VERSION ""

NS_ :

BS_:

BU_: TestTool_HS BCP_HS ECM_HS TCM_HS CGM_HS BCM_HS EBCM_OBD_HS ACCM_HS EBCM_HS TCCM_HS SAS_HS ICCM_OBD_HS ICCM_HS EPS_HS EPB_HS HMIM_HS ONSTAR_HS

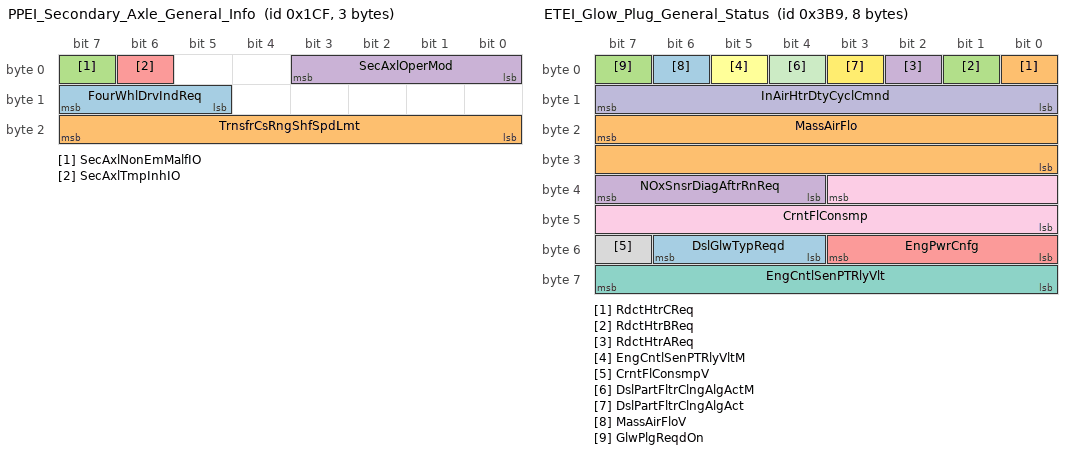
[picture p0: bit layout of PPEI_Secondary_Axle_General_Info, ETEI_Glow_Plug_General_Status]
BO_ 463 PPEI_Secondary_Axle_General_Info: 3 ECM_HS
 SG_ FourWhlDrvIndReq : 15|3@0+ (1,0) [0|7] ""  CGM_HS,BCM_HS
 SG_ TrnsfrCsRngShfSpdLmt : 23|8@0+ (1,0) [0|255] "km / h"  CGM_HS,BCM_HS
 SG_ SecAxlNonEmMalfIO : 7|1@0+ (1,0) [0|1] ""  CGM_HS,BCM_HS
 SG_ SecAxlOperMod : 3|4@0+ (1,0) [0|15] ""  CGM_HS,EBCM_OBD_HS,ONSTAR_HS,EBCM_HS,BCM_HS,TCM_HS,ECM_HS
 SG_ SecAxlTmpInhIO : 6|1@0+ (1,0) [0|1] ""  CGM_HS,ONSTAR_HS,BCM_HS

BO_ 953 ETEI_Glow_Plug_General_Status: 8 ECM_HS
 SG_ DslGlwTypReqd : 54|3@0+ (1,0) [0|7] "" Vector__XXX
 SG_ RdctHtrCReq : 0|1@0+ (1,0) [0|1] "" Vector__XXX
 SG_ RdctHtrBReq : 1|1@0+ (1,0) [0|1] "" Vector__XXX
 SG_ RdctHtrAReq : 2|1@0+ (1,0) [0|1] "" Vector__XXX
 SG_ EngPwrCnfg : 51|4@0+ (1,0) [0|15] "" Vector__XXX
 SG_ EngCntlSenPTRlyVltM : 5|1@0+ (1,0) [0|1] "" Vector__XXX
 SG_ EngCntlSenPTRlyVlt : 63|8@0+ (0.1,0) [0|25.5] "volts" Vector__XXX
 SG_ CrntFlConsmpV : 55|1@0+ (1,0) [0|1] "" Vector__XXX
 SG_ CrntFlConsmp : 35|12@0+ (0.05,0) [0|204.75] "mm3/stk" Vector__XXX
 SG_ InAirHtrDtyCyclCmnd : 15|8@0+ (0.392157,0) [0|100.000035] "%" Vector__XXX
 SG_ DslPartFltrClngAlgActM : 4|1@0+ (1,0) [0|1] "" Vector__XXX
 SG_ DslPartFltrClngAlgAct : 3|1@0+ (1,0) [0|1] "" Vector__XXX
 SG_ MassAirFloV : 6|1@0+ (1,0) [0|1] "" Vector__XXX
 SG_ MassAirFlo : 23|16@0+ (0.01,0) [0|655.35] "grams/s" Vector__XXX
 SG_ GlwPlgReqdOn : 7|1@0+ (1,0) [0|1] "" Vector__XXX
 SG_ NOxSnsrDiagAftrRnReq : 39|4@0+ (20,0) [0|300] "Sec" Vector__XXX

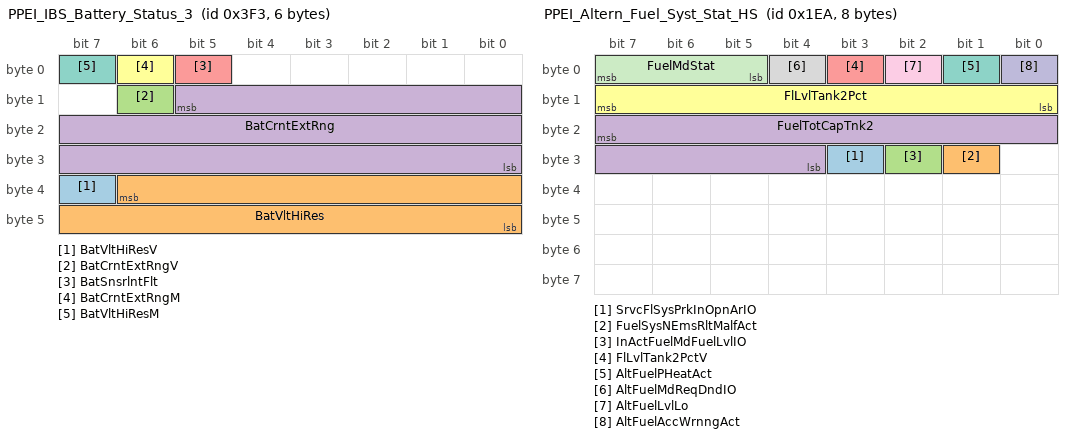
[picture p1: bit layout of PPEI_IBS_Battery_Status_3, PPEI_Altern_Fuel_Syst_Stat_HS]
BO_ 1011 PPEI_IBS_Battery_Status_3: 6 ECM_HS
 SG_ BatVltHiResV : 39|1@0+ (1,0) [0|1] ""  BCM_HS
 SG_ BatVltHiRes : 38|15@0+ (0.001,0) [0|32.767] "volts"  BCM_HS
 SG_ BatCrntExtRngV : 14|1@0+ (1,0) [0|1] ""  BCM_HS
 SG_ BatCrntExtRng : 13|22@0+ (0.001,-2097.152) [-2097.152|2097.151] "amps"  BCM_HS
 SG_ BatSnsrlntFlt : 5|1@0+ (1,0) [0|1] ""  BCM_HS
 SG_ BatCrntExtRngM : 6|1@0+ (1,0) [0|1] ""  BCM_HS
 SG_ BatVltHiResM : 7|1@0+ (1,0) [0|1] ""  BCM_HS

BO_ 490 PPEI_Altern_Fuel_Syst_Stat_HS: 8 ECM_HS
 SG_ SrvcFlSysPrkInOpnArIO : 27|1@0+ (1,0) [0|1] ""  BCM_HS
 SG_ FuelSysNEmsRltMalfAct : 25|1@0+ (1,0) [0|1] ""  BCM_HS
 SG_ InActFuelMdFuelLvlIO : 26|1@0+ (1,0) [0|1] ""  BCM_HS
 SG_ FuelTotCapTnk2 : 23|12@0+ (0.125,0) [0|511.875] "liters"  BCM_HS
 SG_ FlLvlTank2PctV : 3|1@0+ (1,0) [0|1] ""  BCM_HS
 SG_ FlLvlTank2Pct : 15|8@0+ (0.392157,0) [0|100.000035] "%"  BCM_HS
 SG_ AltFuelPHeatAct : 1|1@0+ (1,0) [0|1] ""  BCM_HS,ECM_HS
 SG_ AltFuelMdReqDndIO : 4|1@0+ (1,0) [0|1] ""  BCM_HS
 SG_ AltFuelLvlLo : 2|1@0+ (1,0) [0|1] ""  BCM_HS,ECM_HS
 SG_ AltFuelAccWrnngAct : 0|1@0+ (1,0) [0|1] ""  BCM_HS
 SG_ FuelMdStat : 7|3@0+ (1,0) [0|7] ""  BCM_HS,ECM_HS

BO_ 1267 PPEI_Powertrain_Config_Data_2: 1 ECM_HS
 SG_ VehMassNom : 7|8@0+ (20,500) [500|5600] "kg"  CGM_HS

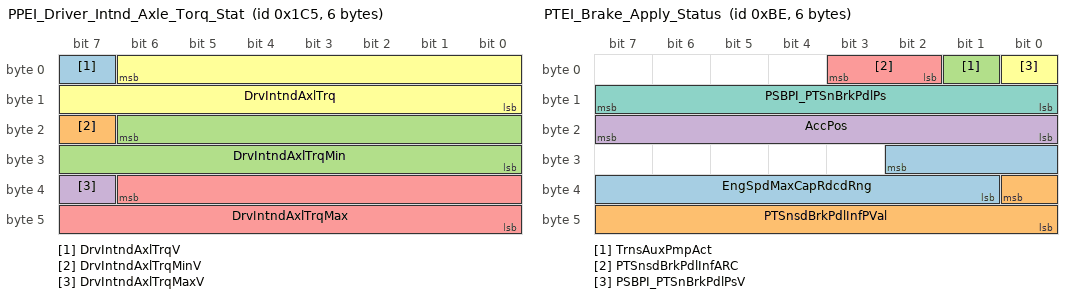
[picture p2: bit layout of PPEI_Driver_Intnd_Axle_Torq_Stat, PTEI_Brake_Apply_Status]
BO_ 453 PPEI_Driver_Intnd_Axle_Torq_Stat: 6 ECM_HS
 SG_ DrvIntndAxlTrqV : 7|1@0+ (1,0) [0|1] ""  CGM_HS,ICCM_OBD_HS,EBCM_OBD_HS,ICCM_HS,EBCM_HS
 SG_ DrvIntndAxlTrqMinV : 23|1@0+ (1,0) [0|1] ""  CGM_HS
 SG_ DrvIntndAxlTrqMin : 22|15@0+ (2,-22534) [-22534|43000] "Nm"  CGM_HS
 SG_ DrvIntndAxlTrqMaxV : 39|1@0+ (1,0) [0|1] ""  CGM_HS
 SG_ DrvIntndAxlTrqMax : 38|15@0+ (2,-22534) [-22534|43000] "Nm"  CGM_HS
 SG_ DrvIntndAxlTrq : 6|15@0+ (2,-22534) [-22534|43000] "Nm"  CGM_HS,ICCM_OBD_HS,EBCM_OBD_HS,ICCM_HS,EBCM_HS

BO_ 452 PPEI_Torque_Request_Status: 8 ECM_HS
 SG_ FSpRgACCSwADdPVal : 50|2@0+ (1,0) [0|3] ""  CGM_HS,EBCM_OBD_HS,EBCM_HS
 SG_ FSpRgACCSwADdARC : 6|2@0+ (1,0) [0|3] ""  CGM_HS,EBCM_OBD_HS,EBCM_HS
 SG_ FSpRgACCSwADd : 7|1@0+ (1,0) [0|1] ""  CGM_HS,EBCM_OBD_HS,EBCM_HS
 SG_ AutBrkAccActPsStRC : 34|2@0+ (1,0) [0|3] ""  CGM_HS,EBCM_OBD_HS,EPB_HS,EBCM_HS
 SG_ AutBrkAccActPsStPVal : 48|9@0+ (1,0) [0|511] ""  CGM_HS,EBCM_OBD_HS,EPB_HS,EBCM_HS
 SG_ ABAAPS_AccPos : 47|8@0+ (0.392157,0) [0|100.000035] "%"  CGM_HS,EBCM_OBD_HS,EPB_HS,EBCM_HS
 SG_ ABAAPS_AccPosV : 32|1@0+ (1,0) [0|1] ""  CGM_HS,EBCM_OBD_HS,EPB_HS,EBCM_HS
 SG_ ACCATCS_LmtgStat : 12|2@0+ (1,0) [0|3] ""  CGM_HS
 SG_ ACCATCS_RqStat : 15|3@0+ (1,0) [0|7] ""  CGM_HS
 SG_ RdLdNomAxlTrq : 10|19@0+ (0.125,-22534) [-22534|43001.875] "Nm"  CGM_HS
 SG_ AccPdlOvrrdAtvProtVal : 1|2@0+ (1,0) [0|3] ""  CGM_HS,EBCM_OBD_HS,EBCM_HS
 SG_ AccPdlOvrrdAtvARC : 3|2@0+ (1,0) [0|3] ""  CGM_HS,EBCM_OBD_HS,EBCM_HS
 SG_ AccPdlOvrrdAtv : 4|1@0+ (1,0) [0|1] ""  CGM_HS,EBCM_OBD_HS,EBCM_HS,BCM_HS
 SG_ CPSATCS_ReqStatus : 37|3@0+ (1,0) [0|7] ""  CGM_HS
 SG_ CPSATCS_LmtngStatus : 39|2@0+ (1,0) [0|3] ""  CGM_HS
 SG_ RVBATCS_ReqStat : 53|3@0+ (1,0) [0|7] ""  CGM_HS
 SG_ RVBATCS_LmtngStat : 55|2@0+ (1,0) [0|3] ""  CGM_HS

BO_ 190 PTEI_Brake_Apply_Status: 6 ECM_HS
 SG_ EngSpdMaxCapRdcdRng : 26|10@0+ (8,0) [0|8184] "rpm"  TCM_HS
 SG_ PTSnsdBrkPdlInfPVal : 32|9@0+ (1,0) [0|511] ""  ICCM_OBD_HS,EBCM_OBD_HS,ICCM_HS,EBCM_HS
 SG_ TrnsAuxPmpAct : 1|1@0+ (1,0) [0|1] ""  TCM_HS
 SG_ AccPos : 23|8@0+ (0.392157,0) [0|100.000035] "%"  BCP_HS,TCCM_HS,TCM_HS
 SG_ PTSnsdBrkPdlInfARC : 3|2@0+ (1,0) [0|3] ""  ICCM_OBD_HS,EBCM_OBD_HS,ICCM_HS,EBCM_HS
 SG_ PSBPI_PTSnBrkPdlPsV : 0|1@0+ (1,0) [0|1] ""  ICCM_OBD_HS,EBCM_OBD_HS,ICCM_HS,EBCM_HS,TCM_HS
 SG_ PSBPI_PTSnBrkPdlPs : 15|8@0+ (0.392157,0) [0|100.000035] "%"  ICCM_OBD_HS,EBCM_OBD_HS,ICCM_HS,EBCM_HS,TCM_HS

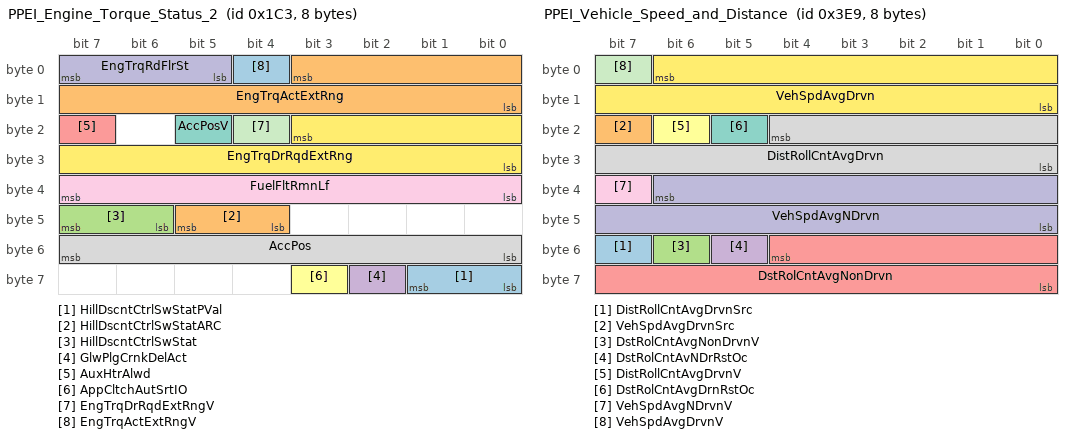
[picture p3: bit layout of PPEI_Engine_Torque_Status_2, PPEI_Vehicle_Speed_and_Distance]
BO_ 451 PPEI_Engine_Torque_Status_2: 8 ECM_HS
 SG_ HillDscntCtrlSwStatPVal : 57|2@0+ (1,0) [0|3] ""  CGM_HS,EBCM_OBD_HS,EBCM_HS
 SG_ HillDscntCtrlSwStatARC : 45|2@0+ (1,0) [0|3] ""  CGM_HS,EBCM_OBD_HS,EBCM_HS
 SG_ HillDscntCtrlSwStat : 47|2@0+ (1,0) [0|3] ""  CGM_HS,EBCM_OBD_HS,EBCM_HS
 SG_ GlwPlgCrnkDelAct : 58|1@0+ (1,0) [0|1] ""  CGM_HS,BCM_HS
 SG_ AuxHtrAlwd : 23|1@0+ (1,0) [0|1] ""  CGM_HS,BCM_HS
 SG_ AppCltchAutSrtIO : 59|1@0+ (1,0) [0|1] ""  CGM_HS,BCM_HS
 SG_ AccPosV : 21|1@0+ (1,0) [0|1] ""  CGM_HS,ICCM_OBD_HS,EBCM_OBD_HS,ICCM_HS,TCCM_HS,EBCM_HS
 SG_ AccPos : 55|8@0+ (0.392157,0) [0|100.000035] "%"  CGM_HS,ICCM_OBD_HS,EBCM_OBD_HS,ICCM_HS,TCCM_HS,EBCM_HS
 SG_ FuelFltRmnLf : 39|8@0+ (0.392157,0) [0|100.000035] "%"  CGM_HS,ONSTAR_HS,BCM_HS
 SG_ EngTrqRdFlrSt : 7|3@0+ (1,0) [0|7] ""  CGM_HS,EBCM_OBD_HS,EBCM_HS
 SG_ EngTrqDrRqdExtRngV : 20|1@0+ (1,0) [0|1] ""  CGM_HS,EBCM_OBD_HS,EBCM_HS,BCM_HS
 SG_ EngTrqDrRqdExtRng : 19|12@0+ (0.5,-848) [-848|1199.5] "Nm"  CGM_HS,EBCM_OBD_HS,EBCM_HS,BCM_HS
 SG_ EngTrqActExtRngV : 4|1@0+ (1,0) [0|1] ""  CGM_HS,ICCM_OBD_HS,EBCM_OBD_HS,ICCM_HS,EPS_HS,EPB_HS,TCCM_HS,EBCM_HS,BCM_HS
 SG_ EngTrqActExtRng : 3|12@0+ (0.5,-848) [-848|1199.5] "Nm"  CGM_HS,ICCM_OBD_HS,EBCM_OBD_HS,ICCM_HS,EPS_HS,EPB_HS,TCCM_HS,EBCM_HS,BCM_HS

BO_ 495 PPEI_Fuel_System_Request_2: 4 ECM_HS
 SG_ MassAirFloV : 7|1@0+ (1,0) [0|1] "" Vector__XXX
 SG_ MassAirFlo : 23|16@0+ (0.01,0) [0|655.35] "grams/s" Vector__XXX

BO_ 1906 DTC_Triggered_772: 7 ECM_HS
 SG_ DTCI_DTCFaultType_772 : 55|8@0+ (1,0) [0|255] ""  CGM_HS,HMIM_HS,ONSTAR_HS
 SG_ DTCI_CodeSupported_772 : 40|1@0+ (1,0) [0|1] ""  CGM_HS,HMIM_HS,ONSTAR_HS
 SG_ DTCI_CurrentStatus_772 : 41|1@0+ (1,0) [0|1] ""  CGM_HS,HMIM_HS,ONSTAR_HS
 SG_ DTCI_TstNPsdCdClrdSt_772 : 42|1@0+ (1,0) [0|1] ""  CGM_HS,HMIM_HS,ONSTAR_HS
 SG_ DTCI_TstFldCdClrdStat_772 : 43|1@0+ (1,0) [0|1] ""  CGM_HS,HMIM_HS,ONSTAR_HS
 SG_ DTCI_HistStat_772 : 44|1@0+ (1,0) [0|1] ""  CGM_HS,HMIM_HS,ONSTAR_HS
 SG_ DTCI_TstNPsdPwrUpSt_772 : 45|1@0+ (1,0) [0|1] ""  CGM_HS,HMIM_HS,ONSTAR_HS
 SG_ DTCI_TstFldPwrUpSt_772 : 46|1@0+ (1,0) [0|1] ""  CGM_HS,HMIM_HS,ONSTAR_HS
 SG_ DTCI_WrnIndRqdSt_772 : 47|1@0+ (1,0) [0|1] ""  CGM_HS,HMIM_HS,ONSTAR_HS
 SG_ DTCI_DTCFailType_772 : 39|8@0+ (1,0) [0|255] ""  CGM_HS,HMIM_HS,ONSTAR_HS
 SG_ DTCI_DTCNumber_772 : 23|16@0+ (1,0) [0|65535] ""  CGM_HS,HMIM_HS,ONSTAR_HS
 SG_ DTCI_DTCSource_772 : 15|8@0+ (1,0) [0|255] ""  CGM_HS,HMIM_HS,ONSTAR_HS
 SG_ DTCI_DTCTriggered_772 : 0|1@0+ (1,0) [0|1] ""  CGM_HS,HMIM_HS,ONSTAR_HS
 SG_ DTCIUnused7_772 : 1|1@0+ (1,0) [0|1] ""  CGM_HS,HMIM_HS,ONSTAR_HS
 SG_ DTCIUnused6_772 : 2|1@0+ (1,0) [0|1] ""  CGM_HS,HMIM_HS,ONSTAR_HS
 SG_ DTCIUnused5_772 : 3|1@0+ (1,0) [0|1] ""  CGM_HS,HMIM_HS,ONSTAR_HS
 SG_ DTCIUnused4_772 : 4|1@0+ (1,0) [0|1] ""  CGM_HS,HMIM_HS,ONSTAR_HS
 SG_ DTCIUnused3_772 : 5|1@0+ (1,0) [0|1] ""  CGM_HS,HMIM_HS,ONSTAR_HS
 SG_ DTCIUnused2_772 : 6|1@0+ (1,0) [0|1] ""  CGM_HS,HMIM_HS,ONSTAR_HS
 SG_ DTCIUnused1_772 : 7|1@0+ (1,0) [0|1] ""  CGM_HS,HMIM_HS,ONSTAR_HS

BO_ 1001 PPEI_Vehicle_Speed_and_Distance: 8 ECM_HS
 SG_ DistRollCntAvgDrvnSrc : 55|1@0+ (1,0) [0|1] ""  CGM_HS,EBCM_OBD_HS,HMIM_HS,EPS_HS,BCP_HS,TCCM_HS,EBCM_HS,BCM_HS,TCM_HS
 SG_ VehSpdAvgDrvnSrc : 23|1@0+ (1,0) [0|1] ""  CGM_HS,EBCM_OBD_HS,HMIM_HS,EPS_HS,EPB_HS,TCCM_HS,EBCM_HS,BCM_HS,TCM_HS
 SG_ DstRolCntAvgNonDrvnV : 54|1@0+ (1,0) [0|1] ""  CGM_HS,EBCM_OBD_HS,HMIM_HS,EPS_HS,TCCM_HS,EBCM_HS,BCM_HS
 SG_ DstRolCntAvNDrRstOc : 53|1@0+ (1,0) [0|1] ""  CGM_HS,EBCM_OBD_HS,HMIM_HS,EPS_HS,TCCM_HS,EBCM_HS,BCM_HS
 SG_ DstRolCntAvgNonDrvn : 52|13@0+ (0.125,0) [0|1023.875] "m"  CGM_HS,EBCM_OBD_HS,HMIM_HS,EPS_HS,TCCM_HS,EBCM_HS,BCM_HS
 SG_ DistRollCntAvgDrvnV : 22|1@0+ (1,0) [0|1] ""  CGM_HS,ICCM_OBD_HS,EBCM_OBD_HS,ICCM_HS,HMIM_HS,EPS_HS,BCP_HS,TCCM_HS,EBCM_HS,BCM_HS,TCM_HS
 SG_ DstRolCntAvgDrnRstOc : 21|1@0+ (1,0) [0|1] ""  CGM_HS,ICCM_OBD_HS,EBCM_OBD_HS,ICCM_HS,HMIM_HS,EPS_HS,BCP_HS,TCCM_HS,EBCM_HS,BCM_HS,TCM_HS
 SG_ DistRollCntAvgDrvn : 20|13@0+ (0.125,0) [0|1023.875] "m"  CGM_HS,ICCM_OBD_HS,EBCM_OBD_HS,ICCM_HS,HMIM_HS,EPS_HS,BCP_HS,TCCM_HS,EBCM_HS,BCM_HS,TCM_HS
 SG_ VehSpdAvgNDrvnV : 39|1@0+ (1,0) [0|1] ""  CGM_HS,ICCM_OBD_HS,EBCM_OBD_HS,ICCM_HS,HMIM_HS,EPS_HS,BCP_HS,ONSTAR_HS,EPB_HS,TCCM_HS,EBCM_HS,BCM_HS
 SG_ VehSpdAvgNDrvn : 38|15@0+ (0.015625,0) [0|511.984375] "km / h"  CGM_HS,ICCM_OBD_HS,EBCM_OBD_HS,ICCM_HS,HMIM_HS,EPS_HS,BCP_HS,ONSTAR_HS,EPB_HS,TCCM_HS,EBCM_HS,BCM_HS
 SG_ VehSpdAvgDrvnV : 7|1@0+ (1,0) [0|1] ""  CGM_HS,ICCM_OBD_HS,EBCM_OBD_HS,ICCM_HS,HMIM_HS,EPS_HS,BCP_HS,ONSTAR_HS,EPB_HS,TCCM_HS,EBCM_HS,BCM_HS,TCM_HS
 SG_ VehSpdAvgDrvn : 6|15@0+ (0.015625,0) [0|511.984375] "km / h"  CGM_HS,ICCM_OBD_HS,EBCM_OBD_HS,ICCM_HS,HMIM_HS,EPS_HS,BCP_HS,ONSTAR_HS,EPB_HS,TCCM_HS,EBCM_HS,BCM_HS,TCM_HS

BO_ 961 PPEI_Powertrain_Immobilizer_Data: 8 ECM_HS
 SG_ PTImmblzerInfo : 7|64@0+ (1,0) [0|1.84467440737096E+019] ""  ONSTAR_HS,BCM_HS,ECM_HS

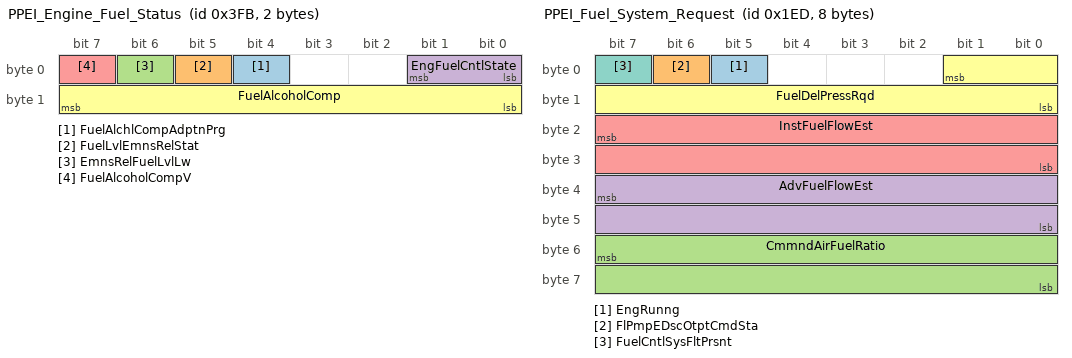
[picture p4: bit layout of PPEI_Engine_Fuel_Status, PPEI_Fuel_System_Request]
BO_ 1019 PPEI_Engine_Fuel_Status: 2 ECM_HS
 SG_ FuelAlchlCompAdptnPrg : 4|1@0+ (1,0) [0|1] ""  CGM_HS,BCM_HS
 SG_ FuelLvlEmnsRelStat : 5|1@0+ (1,0) [0|1] ""  CGM_HS,BCP_HS
 SG_ EmnsRelFuelLvlLw : 6|1@0+ (1,0) [0|1] ""  CGM_HS,ICCM_OBD_HS,ICCM_HS,BCP_HS
 SG_ EngFuelCntlState : 1|2@0+ (1,0) [0|3] ""  CGM_HS,ICCM_OBD_HS,ICCM_HS
 SG_ FuelAlcoholCompV : 7|1@0+ (1,0) [0|1] ""  CGM_HS,ICCM_OBD_HS,ICCM_HS,ONSTAR_HS,BCM_HS
 SG_ FuelAlcoholComp : 15|8@0+ (0.392157,0) [0|100.000035] "%"  CGM_HS,ICCM_OBD_HS,ICCM_HS,ONSTAR_HS,BCM_HS

BO_ 493 PPEI_Fuel_System_Request: 8 ECM_HS
 SG_ EngRunng : 5|1@0+ (1,0) [0|1] ""  CGM_HS,ICCM_OBD_HS,ICCM_HS
 SG_ FlPmpEDscOtptCmdSta : 6|1@0+ (1,0) [0|1] ""  CGM_HS,ICCM_OBD_HS,ICCM_HS
 SG_ CmmndAirFuelRatio : 55|16@0+ (0.000488281,0) [0|31.999495335] ""  CGM_HS,ICCM_OBD_HS,ICCM_HS
 SG_ AdvFuelFlowEst : 39|16@0+ (0.000976562,0) [0|63.99899067] "grams/s"  CGM_HS,ICCM_OBD_HS,ICCM_HS
 SG_ InstFuelFlowEst : 23|16@0+ (0.000976562,0) [0|63.99899067] "grams/s"  CGM_HS,ICCM_OBD_HS,ICCM_HS
 SG_ FuelDelPressRqd : 1|10@0+ (1,0) [0|1023] "kPa"  CGM_HS,ICCM_OBD_HS,ICCM_HS
 SG_ FuelCntlSysFltPrsnt : 7|1@0+ (1,0) [0|1] ""  CGM_HS,ICCM_OBD_HS,ICCM_HS

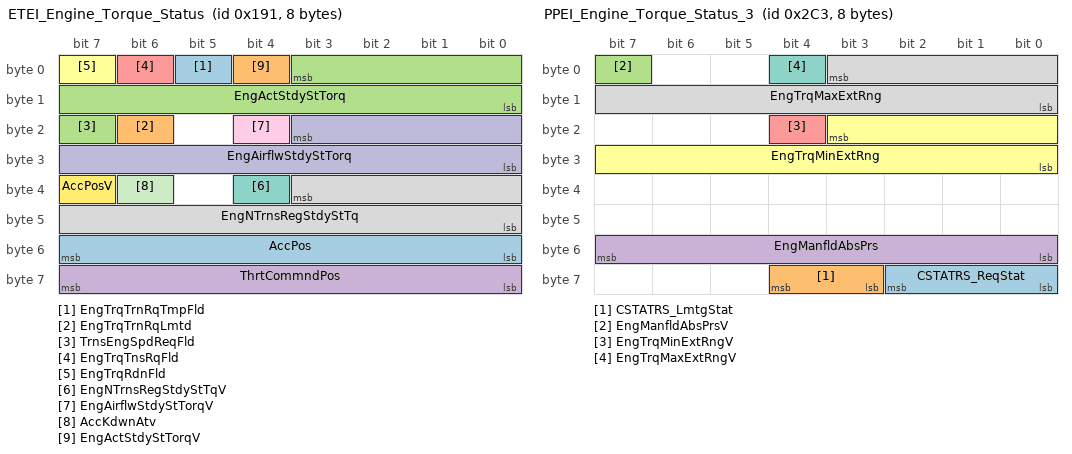
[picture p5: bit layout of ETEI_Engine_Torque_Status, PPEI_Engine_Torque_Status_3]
BO_ 401 ETEI_Engine_Torque_Status: 8 ECM_HS
 SG_ EngTrqTrnRqTmpFld : 5|1@0+ (1,0) [0|1] ""  TCCM_HS,TCM_HS
 SG_ EngTrqTrnRqLmtd : 22|1@0+ (1,0) [0|1] ""  TCCM_HS,TCM_HS
 SG_ TrnsEngSpdReqFld : 23|1@0+ (1,0) [0|1] ""  TCCM_HS,TCM_HS
 SG_ ThrtCommndPos : 63|8@0+ (0.392157,0) [0|100.000035] "%"  TCCM_HS
 SG_ EngTrqTnsRqFld : 6|1@0+ (1,0) [0|1] ""  TCCM_HS,TCM_HS
 SG_ EngTrqRdnFld : 7|1@0+ (1,0) [0|1] ""  TCCM_HS,TCM_HS
 SG_ EngNTrnsRegStdyStTqV : 36|1@0+ (1,0) [0|1] ""  TCCM_HS,TCM_HS
 SG_ EngNTrnsRegStdyStTq : 35|12@0+ (0.5,-848) [-848|1199.5] "Nm"  TCCM_HS,TCM_HS
 SG_ EngAirflwStdyStTorqV : 20|1@0+ (1,0) [0|1] ""  TCCM_HS,TCM_HS
 SG_ EngAirflwStdyStTorq : 19|12@0+ (0.5,-848) [-848|1199.5] "Nm"  TCCM_HS,TCM_HS
 SG_ AccKdwnAtv : 38|1@0+ (1,0) [0|1] ""  TCCM_HS,TCM_HS
 SG_ AccPosV : 39|1@0+ (1,0) [0|1] ""  BCP_HS,TCM_HS
 SG_ AccPos : 55|8@0+ (0.392157,0) [0|100.000035] "%"  BCP_HS,TCM_HS
 SG_ EngActStdyStTorqV : 4|1@0+ (1,0) [0|1] ""  TCCM_HS,TCM_HS
 SG_ EngActStdyStTorq : 3|12@0+ (0.5,-848) [-848|1199.5] "Nm"  TCCM_HS,TCM_HS

BO_ 707 PPEI_Engine_Torque_Status_3: 8 ECM_HS
 SG_ CSTATRS_ReqStat : 58|3@0+ (1,0) [0|7] ""  CGM_HS,EBCM_OBD_HS,EBCM_HS
 SG_ CSTATRS_LmtgStat : 60|2@0+ (1,0) [0|3] ""  CGM_HS,EBCM_OBD_HS,EBCM_HS
 SG_ EngManfldAbsPrsV : 7|1@0+ (1,0) [0|1] ""  CGM_HS,EBCM_OBD_HS,BCP_HS,EBCM_HS
 SG_ EngManfldAbsPrs : 55|8@0+ (0.5,0) [0|127.5] "kPa"  CGM_HS,EBCM_OBD_HS,BCP_HS,EBCM_HS
 SG_ EngTrqMinExtRngV : 20|1@0+ (1,0) [0|1] ""  CGM_HS,EBCM_OBD_HS,EBCM_HS
 SG_ EngTrqMinExtRng : 19|12@0+ (0.5,-848) [-848|1199.5] "Nm"  CGM_HS,EBCM_OBD_HS,EBCM_HS
 SG_ EngTrqMaxExtRngV : 4|1@0+ (1,0) [0|1] ""  CGM_HS,EBCM_OBD_HS,TCCM_HS,EBCM_HS
 SG_ EngTrqMaxExtRng : 3|12@0+ (0.5,-848) [-848|1199.5] "Nm"  CGM_HS,EBCM_OBD_HS,TCCM_HS,EBCM_HS

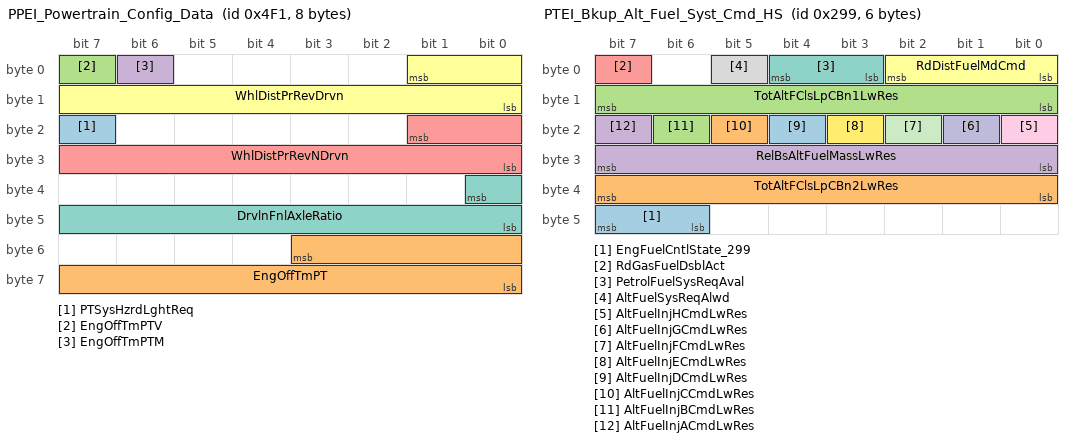
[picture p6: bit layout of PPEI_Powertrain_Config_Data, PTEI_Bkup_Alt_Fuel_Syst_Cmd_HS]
BO_ 1265 PPEI_Powertrain_Config_Data: 8 ECM_HS
 SG_ PTSysHzrdLghtReq : 23|1@0+ (1,0) [0|1] ""  CGM_HS,BCM_HS
 SG_ EngOffTmPT : 51|12@0+ (0.5,0) [0|2047.5] "min"  CGM_HS,EBCM_OBD_HS,EBCM_HS,TCM_HS
 SG_ EngOffTmPTV : 7|1@0+ (1,0) [0|1] ""  CGM_HS,EBCM_OBD_HS,EBCM_HS,TCM_HS
 SG_ EngOffTmPTM : 6|1@0+ (1,0) [0|1] ""  CGM_HS,EBCM_OBD_HS,EBCM_HS,TCM_HS
 SG_ WhlDistPrRevNDrvn : 17|10@0+ (3,800) [800|3869] "mm"  CGM_HS,ICCM_OBD_HS,EBCM_OBD_HS,ICCM_HS,HMIM_HS,EPS_HS,EPB_HS,TCCM_HS,EBCM_HS,TCM_HS
 SG_ WhlDistPrRevDrvn : 1|10@0+ (3,800) [800|3869] "mm"  CGM_HS,ICCM_OBD_HS,EBCM_OBD_HS,ICCM_HS,HMIM_HS,EPS_HS,EPB_HS,TCCM_HS,EBCM_HS,BCM_HS,TCM_HS
 SG_ DrvlnFnlAxleRatio : 32|9@0+ (0.01,2) [2|7.11] ""  CGM_HS,EBCM_OBD_HS,TCCM_HS,EBCM_HS,BCM_HS,TCM_HS

BO_ 417 ETEI_Engine_General_Status: 7 ECM_HS
 SG_ EngCrsCntrlMode : 29|3@0+ (1,0) [0|7] ""  TCM_HS
 SG_ EngPstOxgSnsDgAstRq : 31|1@0+ (1,0) [0|1] ""  TCM_HS
 SG_ CrsCtrlCnstSpdAct : 26|1@0+ (1,0) [0|1] ""  TCM_HS
 SG_ WrmUpShftPtrnRq : 25|1@0+ (1,0) [0|1] ""  TCM_HS
 SG_ EngIdlSpdRdcdRng : 39|8@0+ (8,0) [0|2040] "rpm"  BCP_HS,TCM_HS
 SG_ EngAlwCltAdp : 24|1@0+ (1,0) [0|1] ""  TCM_HS
 SG_ BsTrgtEngIdlSpd : 47|8@0+ (8,0) [0|2040] "rpm"  TCM_HS
 SG_ AccPdlPosPcntFullRngV : 17|1@0+ (1,0) [0|1] ""  TCM_HS
 SG_ AccPdlPosPcntFullRng : 55|8@0+ (0.392157,0) [0|100.000035] "%"  TCM_HS
 SG_ DslPrtFltrIdlRgtnMdReq : 20|1@0+ (1,0) [0|1] ""  TCM_HS
 SG_ DslPartFltrClngAlgActM : 18|1@0+ (1,0) [0|1] ""  TCM_HS
 SG_ DslPartFltrClngAlgAct : 19|1@0+ (1,0) [0|1] ""  TCM_HS
 SG_ EngCylDeactMd : 9|2@0+ (1,0) [0|3] ""  BCP_HS
 SG_ ACCmCltEngd : 13|1@0+ (1,0) [0|1] ""  TCM_HS
 SG_ ParkNeutralSwStatV : 21|1@0+ (1,0) [0|1] ""  TCM_HS
 SG_ ParkNeutralSwStat : 22|1@0+ (1,0) [0|1] ""  TCM_HS
 SG_ EngColdHiIdleActive : 23|1@0+ (1,0) [0|1] ""  TCM_HS
 SG_ EngCyDactTqSmtAct : 6|1@0+ (1,0) [0|1] ""  TCM_HS
 SG_ EngBrkStat : 15|2@0+ (1,0) [0|3] ""  TCM_HS
 SG_ TracCntlSysPwrtrnInhbt : 12|1@0+ (1,0) [0|1] ""  TCM_HS
 SG_ EngMtlProtAtv : 11|1@0+ (1,0) [0|1] ""  TCM_HS
 SG_ EngDgTrqCnvClUnlkRqd : 7|1@0+ (1,0) [0|1] ""  TCM_HS
 SG_ EngCyldrDeactReqd : 10|1@0+ (1,0) [0|1] ""  TCM_HS
 SG_ ETGRReqdGear : 3|4@0+ (1,0) [0|15] ""  TCM_HS
 SG_ ETGRReqType : 5|2@0+ (1,0) [0|3] ""  TCM_HS

BO_ 1233 PPEI_Engine_General_Status_5: 8 ECM_HS
 SG_ a_12VBatSysUnstab : 30|1@0+ (1,0) [0|1] ""  CGM_HS,BCM_HS
 SG_ EngShtdwnAct : 48|1@0+ (1,0) [0|1] ""  CGM_HS
 SG_ EngShtdwnPndgIO : 49|1@0+ (1,0) [0|1] ""  CGM_HS,ONSTAR_HS,BCM_HS
 SG_ FuelFltChgNwIO : 51|1@0+ (1,0) [0|1] ""  CGM_HS,ONSTAR_HS,BCM_HS
 SG_ PTExPrtclFltrWrn2IO : 50|1@0+ (1,0) [0|1] ""  CGM_HS,ONSTAR_HS,BCM_HS
 SG_ PTHiElecLdReqd : 52|1@0+ (1,0) [0|1] ""  CGM_HS,BCM_HS
 SG_ PTExPrtclFltrWrnIO : 53|1@0+ (1,0) [0|1] ""  CGM_HS,ONSTAR_HS,BCM_HS
 SG_ AirCndOffIO : 0|1@0+ (1,0) [0|1] ""  CGM_HS,BCM_HS
 SG_ DslGlwPlgIO : 55|1@0+ (1,0) [0|1] ""  CGM_HS,BCM_HS
 SG_ RdcdPwrIO : 31|1@0+ (1,0) [0|1] ""  CGM_HS,ONSTAR_HS,BCM_HS
 SG_ FuelTotCap : 27|12@0+ (0.125,0) [0|511.875] "liters"  CGM_HS,BCM_HS
 SG_ FlLvlPctV : 28|1@0+ (1,0) [0|1] ""  CGM_HS,BCM_HS
 SG_ FlLvlPct : 47|8@0+ (0.392157,0) [0|100.000035] "%"  CGM_HS,BCM_HS
 SG_ EngWtrInFlIO : 54|1@0+ (1,0) [0|1] ""  CGM_HS,ONSTAR_HS,BCM_HS
 SG_ EngOilTmpV : 7|1@0+ (1,0) [0|1] ""  CGM_HS,EPS_HS,BCM_HS
 SG_ EngOilTmp : 15|8@0+ (1,-40) [-40|215] "deg C"  CGM_HS,EPS_HS,BCM_HS
 SG_ EngOilPrsV : 6|1@0+ (1,0) [0|1] ""  CGM_HS,BCM_HS
 SG_ EngOilPrsLwIO : 5|1@0+ (1,0) [0|1] ""  CGM_HS,ONSTAR_HS,BCM_HS
 SG_ EngOilPrs : 23|8@0+ (4,0) [0|1020] "kPa"  CGM_HS,BCM_HS
 SG_ EngOilLvlLwIO : 4|1@0+ (1,0) [0|1] ""  CGM_HS,ONSTAR_HS,BCM_HS
 SG_ EngOilChngIO : 3|1@0+ (1,0) [0|1] ""  CGM_HS,BCM_HS
 SG_ EngHt_StpEngIO : 1|1@0+ (1,0) [0|1] ""  CGM_HS,ONSTAR_HS,BCM_HS
 SG_ EngHotFuelEnrchmntIO : 2|1@0+ (1,0) [0|1] ""  CGM_HS,ONSTAR_HS,BCM_HS
 SG_ CkFlFilrCapIO : 29|1@0+ (1,0) [0|1] ""  CGM_HS,BCM_HS

BO_ 1217 PPEI_Engine_General_Status_4: 8 ECM_HS
 SG_ LDMinEngCltTmpRchd : 43|1@0+ (1,0) [0|1] ""  CGM_HS,TCCM_HS,TCM_HS
 SG_ LegPstDTCClrDrvCyCm : 40|1@0+ (1,0) [0|1] ""  CGM_HS,ICCM_OBD_HS,EBCM_OBD_HS,ICCM_HS,BCP_HS,EBCM_HS,TCM_HS
 SG_ LegDiagColdStCndMet : 47|1@0+ (1,0) [0|1] ""  CGM_HS,ICCM_OBD_HS,EBCM_OBD_HS,ICCM_HS,BCP_HS,TCCM_HS,EBCM_HS,TCM_HS
 SG_ LegDiagColdStCndFltPr : 46|1@0+ (1,0) [0|1] ""  CGM_HS,ICCM_OBD_HS,EBCM_OBD_HS,ICCM_HS,BCP_HS,TCCM_HS,EBCM_HS,TCM_HS
 SG_ EngEconMdCmnd : 44|1@0+ (1,0) [0|1] ""  CGM_HS,TCM_HS
 SG_ DslExhFldRmngDstHRsV : 41|1@0+ (1,0) [0|1] ""  CGM_HS,ONSTAR_HS,BCM_HS
 SG_ DslExhFldRmngDstHRs : 54|15@0+ (2,0) [0|65534] "km"  CGM_HS,ONSTAR_HS,BCM_HS
 SG_ EngOilHotIO : 45|1@0+ (1,0) [0|1] ""  CGM_HS,BCM_HS
 SG_ OAT_PT_EstV : 3|1@0+ (1,0) [0|1] ""  CGM_HS,EBCM_OBD_HS,BCP_HS,TCCM_HS,EBCM_HS,BCM_HS,TCM_HS
 SG_ LegDiagStndCndMet : 2|1@0+ (1,0) [0|1] ""  CGM_HS,ICCM_OBD_HS,EBCM_OBD_HS,ICCM_HS,BCP_HS,ONSTAR_HS,TCCM_HS,EBCM_HS,TCM_HS
 SG_ LegDiagStndCndFltPr : 1|1@0+ (1,0) [0|1] ""  CGM_HS,ICCM_OBD_HS,EBCM_OBD_HS,ICCM_HS,BCP_HS,TCCM_HS,EBCM_HS,TCM_HS
 SG_ OAT_PT_EstM : 4|1@0+ (1,0) [0|1] ""  CGM_HS,EBCM_OBD_HS,BCP_HS,TCCM_HS,EBCM_HS,BCM_HS,TCM_HS
 SG_ OAT_PT_Est : 39|8@0+ (0.5,-40) [-40|87.5] "deg C"  CGM_HS,EBCM_OBD_HS,BCP_HS,TCCM_HS,EBCM_HS,BCM_HS,TCM_HS
 SG_ EngWrmUpAch : 0|1@0+ (1,0) [0|1] ""  CGM_HS,ICCM_OBD_HS,EBCM_OBD_HS,ICCM_HS,BCP_HS,TCCM_HS,EBCM_HS,TCM_HS
 SG_ EngIntAirTmpV : 5|1@0+ (1,0) [0|1] ""  CGM_HS,ICCM_OBD_HS,EBCM_OBD_HS,ICCM_HS,BCP_HS,ONSTAR_HS,TCCM_HS,EBCM_HS,BCM_HS
 SG_ EngIntAirTmp : 31|8@0+ (1,-40) [-40|215] "deg C"  CGM_HS,ICCM_OBD_HS,EBCM_OBD_HS,ICCM_HS,BCP_HS,ONSTAR_HS,TCCM_HS,EBCM_HS,BCM_HS
 SG_ EngCltTmpV : 6|1@0+ (1,0) [0|1] ""  CGM_HS,ICCM_OBD_HS,EBCM_OBD_HS,ICCM_HS,EPS_HS,BCP_HS,ONSTAR_HS,EBCM_HS,BCM_HS
 SG_ EngCltTmp : 23|8@0+ (1,-40) [-40|215] "deg C"  CGM_HS,ICCM_OBD_HS,EBCM_OBD_HS,ICCM_HS,EPS_HS,BCP_HS,ONSTAR_HS,EBCM_HS,BCM_HS
 SG_ BarPrsAbsV : 7|1@0+ (1,0) [0|1] ""  CGM_HS,ICCM_OBD_HS,EBCM_OBD_HS,ICCM_HS,BCP_HS,EBCM_HS,BCM_HS
 SG_ BarPrsAbs : 15|8@0+ (0.5,0) [0|127.5] "kPa"  CGM_HS,ICCM_OBD_HS,EBCM_OBD_HS,ICCM_HS,BCP_HS,EBCM_HS,BCM_HS

BO_ 665 PTEI_Bkup_Alt_Fuel_Syst_Cmd_HS: 6 ECM_HS
 SG_ EngFuelCntlState_299 : 47|2@0+ (1,0) [0|3] "" Vector__XXX
 SG_ TotAltFClsLpCBn2LwRes : 39|8@0- (0.0078125,0) [-1|0.9921875] "" Vector__XXX
 SG_ TotAltFClsLpCBn1LwRes : 15|8@0- (0.0078125,0) [-1|0.9921875] "" Vector__XXX
 SG_ RelBsAltFuelMassLwRes : 31|8@0+ (0.00390625,0) [0|0.99609375] "" Vector__XXX
 SG_ RdGasFuelDsblAct : 7|1@0+ (1,0) [0|1] "" Vector__XXX
 SG_ RdDistFuelMdCmd : 2|3@0+ (1,0) [0|7] "" Vector__XXX
 SG_ PetrolFuelSysReqAval : 4|2@0+ (1,0) [0|3] "" Vector__XXX
 SG_ AltFuelSysReqAlwd : 5|1@0+ (1,0) [0|1] "" Vector__XXX
 SG_ AltFuelInjHCmdLwRes : 16|1@0+ (1,0) [0|1] "" Vector__XXX
 SG_ AltFuelInjGCmdLwRes : 17|1@0+ (1,0) [0|1] "" Vector__XXX
 SG_ AltFuelInjFCmdLwRes : 18|1@0+ (1,0) [0|1] "" Vector__XXX
 SG_ AltFuelInjECmdLwRes : 19|1@0+ (1,0) [0|1] "" Vector__XXX
 SG_ AltFuelInjDCmdLwRes : 20|1@0+ (1,0) [0|1] "" Vector__XXX
 SG_ AltFuelInjCCmdLwRes : 21|1@0+ (1,0) [0|1] "" Vector__XXX
 SG_ AltFuelInjBCmdLwRes : 22|1@0+ (1,0) [0|1] "" Vector__XXX
 SG_ AltFuelInjACmdLwRes : 23|1@0+ (1,0) [0|1] "" Vector__XXX

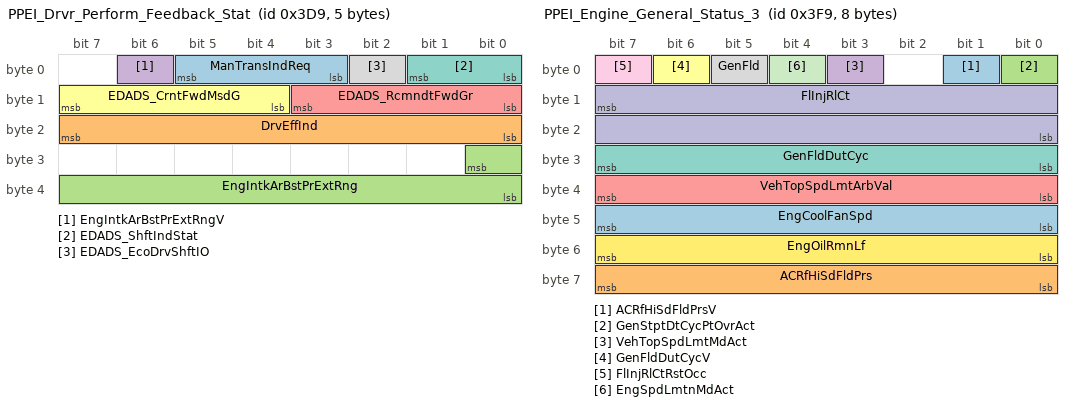
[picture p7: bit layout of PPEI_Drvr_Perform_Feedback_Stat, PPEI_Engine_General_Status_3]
BO_ 985 PPEI_Drvr_Perform_Feedback_Stat: 5 ECM_HS
 SG_ ManTransIndReq : 5|3@0+ (1,0) [0|7] ""  BCM_HS
 SG_ DrvEffInd : 23|8@0- (0.78125,0) [-100|99.21875] "%"  BCM_HS
 SG_ EngIntkArBstPrExtRng : 24|9@0+ (1,-110) [-110|401] "kPa"  BCM_HS
 SG_ EngIntkArBstPrExtRngV : 6|1@0+ (1,0) [0|1] ""  BCM_HS
 SG_ EDADS_RcmndtFwdGr : 11|4@0+ (1,0) [0|15] ""  BCM_HS
 SG_ EDADS_CrntFwdMsdG : 15|4@0+ (1,0) [0|15] ""  BCM_HS
 SG_ EDADS_ShftIndStat : 1|2@0+ (1,0) [0|3] ""  BCM_HS
 SG_ EDADS_EcoDrvShftIO : 2|1@0+ (1,0) [0|1] ""  BCM_HS

BO_ 1017 PPEI_Engine_General_Status_3: 8 ECM_HS
 SG_ ACRfHiSdFldPrsV : 1|1@0+ (1,0) [0|1] ""  CGM_HS,ICCM_OBD_HS,ICCM_HS,ONSTAR_HS,BCM_HS
 SG_ ACRfHiSdFldPrs : 63|8@0+ (14,0) [0|3570] "kPaG"  CGM_HS,ICCM_OBD_HS,ICCM_HS,ONSTAR_HS,BCM_HS
 SG_ GenStptDtCycPtOvrAct : 0|1@0+ (1,0) [0|1] ""  CGM_HS,BCM_HS
 SG_ VehTopSpdLmtMdAct : 3|1@0+ (1,0) [0|1] ""  CGM_HS,BCM_HS
 SG_ VehTopSpdLmtArbVal : 39|8@0+ (2,0) [0|510] "km / h"  CGM_HS,BCM_HS
 SG_ GenFldDutCycV : 6|1@0+ (1,0) [0|1] ""  CGM_HS,BCM_HS
 SG_ GenFldDutCyc : 31|8@0+ (0.392157,0) [0|100.000035] "%"  CGM_HS,BCM_HS
 SG_ GenFld : 5|1@0+ (1,0) [0|1] ""  CGM_HS,ONSTAR_HS,BCM_HS
 SG_ FlInjRlCtRstOcc : 7|1@0+ (1,0) [0|1] ""  CGM_HS,ONSTAR_HS,BCM_HS
 SG_ FlInjRlCt : 15|16@0+ (3.05176E-005,0) [0|1.999970916] "liters"  CGM_HS,ONSTAR_HS,BCM_HS
 SG_ EngSpdLmtnMdAct : 4|1@0+ (1,0) [0|1] ""  CGM_HS,BCM_HS
 SG_ EngOilRmnLf : 55|8@0+ (0.392157,0) [0|100.000035] "%"  CGM_HS,BCM_HS
 SG_ EngCoolFanSpd : 47|8@0+ (0.392157,0) [0|100.000035] "%"  CGM_HS,ICCM_OBD_HS,ICCM_HS,BCM_HS

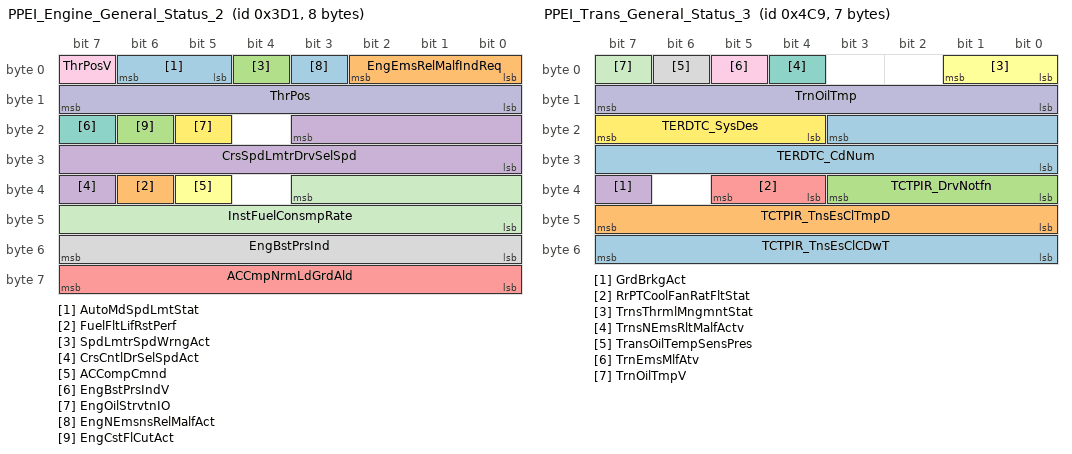
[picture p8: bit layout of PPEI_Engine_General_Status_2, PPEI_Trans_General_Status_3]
BO_ 977 PPEI_Engine_General_Status_2: 8 ECM_HS
 SG_ AutoMdSpdLmtStat : 6|2@0+ (1,0) [0|3] ""  CGM_HS,BCM_HS
 SG_ FuelFltLifRstPerf : 38|1@0+ (1,0) [0|1] ""  CGM_HS,ONSTAR_HS,BCM_HS
 SG_ SpdLmtrSpdWrngAct : 4|1@0+ (1,0) [0|1] ""  CGM_HS,BCM_HS
 SG_ CrsCntlDrSelSpdAct : 39|1@0+ (1,0) [0|1] ""  CGM_HS,BCM_HS
 SG_ ACCmpNrmLdGrdAld : 63|8@0+ (0.1,0) [0|25.5] "dm3/m/s"  CGM_HS,BCM_HS
 SG_ ACCompCmnd : 37|1@0+ (1,0) [0|1] ""  CGM_HS,ICCM_OBD_HS,ICCM_HS,BCM_HS,TCM_HS
 SG_ EngBstPrsIndV : 23|1@0+ (1,0) [0|1] ""  CGM_HS,BCM_HS
 SG_ EngBstPrsInd : 55|8@0+ (0.392157,0) [0|100.000035] "%"  CGM_HS,BCM_HS
 SG_ ThrPosV : 7|1@0+ (1,0) [0|1] ""  CGM_HS,BCM_HS
 SG_ ThrPos : 15|8@0+ (0.392157,0) [0|100.000035] "%"  CGM_HS,BCM_HS
 SG_ InstFuelConsmpRate : 35|12@0+ (0.025,0) [0|102.375] "ltrs/hr"  CGM_HS,BCM_HS
 SG_ EngOilStrvtnIO : 21|1@0+ (1,0) [0|1] ""  CGM_HS,BCM_HS
 SG_ EngNEmsnsRelMalfAct : 3|1@0+ (1,0) [0|1] ""  CGM_HS,BCM_HS
 SG_ EngEmsRelMalfIndReq : 2|3@0+ (1,0) [0|7] ""  CGM_HS,BCM_HS
 SG_ EngCstFlCutAct : 22|1@0+ (1,0) [0|1] ""  CGM_HS,BCP_HS,BCM_HS,TCM_HS
 SG_ CrsSpdLmtrDrvSelSpd : 19|12@0+ (0.0625,0) [0|255.9375] "km / h"  CGM_HS,BCM_HS,TCM_HS

BO_ 201 PPEI_Engine_General_Status_1: 8 ECM_HS
 SG_ Eng12vStrtrMtrCmmdOn : 53|1@0+ (1,0) [0|1] ""  CGM_HS,ICCM_OBD_HS,EBCM_OBD_HS,ICCM_HS,EPS_HS,BCP_HS,EPB_HS,TCCM_HS,EBCM_HS,BCM_HS,TCM_HS
 SG_ EngCntrlRunCrnkTrmSt : 52|1@0+ (1,0) [0|1] ""  CGM_HS,ICCM_OBD_HS,EBCM_OBD_HS,ICCM_HS,BCP_HS,EBCM_HS,TCM_HS
 SG_ EngAirIntBstPrV : 51|1@0+ (1,0) [0|1] ""  CGM_HS,EBCM_OBD_HS,EBCM_HS,BCM_HS
 SG_ EngAirIntBstPr : 63|8@0- (1,0) [-128|127] "kPaG"  CGM_HS,EBCM_OBD_HS,EBCM_HS,BCM_HS
 SG_ SpdLmtrSpdWrngEnbld : 47|1@0+ (1,0) [0|1] ""  CGM_HS,BCM_HS
 SG_ EngCylDactEvntPndg : 54|1@0+ (1,0) [0|1] ""  CGM_HS,ICCM_OBD_HS,ICCM_HS
 SG_ EngCylDeactMd : 43|2@0+ (1,0) [0|3] ""  CGM_HS,ICCM_OBD_HS,ICCM_HS,BCM_HS
 SG_ RmVhStrtEngRng : 55|1@0+ (1,0) [0|1] ""  CGM_HS,EBCM_OBD_HS,EPB_HS,TCCM_HS,EBCM_HS,BCM_HS
 SG_ PFEngSpdCmndSpcd : 45|1@0+ (1,0) [0|1] ""  CGM_HS,BCM_HS
 SG_ DrThrtlOvrrdDetProtVal : 25|2@0+ (1,0) [0|3] ""  CGM_HS,EBCM_OBD_HS,EBCM_HS
 SG_ DrThrtlOvrdDetAlvRlCnt : 27|2@0+ (1,0) [0|3] ""  CGM_HS,EBCM_OBD_HS,EBCM_HS
 SG_ PltfrmEngSpdCmdInhtRq : 44|1@0+ (1,0) [0|1] ""  CGM_HS,BCM_HS
 SG_ PT_BrkPedDscrtInpStatV : 41|1@0+ (1,0) [0|1] ""  CGM_HS,EBCM_OBD_HS,BCP_HS,TCCM_HS,TCM_HS,EBCM_HS
 SG_ PT_BrkPedDscrtInpStat : 40|1@0+ (1,0) [0|1] ""  CGM_HS,EBCM_OBD_HS,BCP_HS,TCCM_HS,TCM_HS,EBCM_HS
 SG_ AccActPos : 39|8@0+ (0.392157,0) [0|100.000035] "%"  CGM_HS,ICCM_OBD_HS,EBCM_OBD_HS,ICCM_HS,BCP_HS,EPB_HS,TCCM_HS,BCM_HS,TCM_HS,EBCM_HS
 SG_ CrsCntEnbld : 29|1@0+ (1,0) [0|1] ""  CGM_HS,BCM_HS
 SG_ CrsCntAtv : 30|1@0+ (1,0) [0|1] ""  CGM_HS,EBCM_OBD_HS,BCP_HS,EPB_HS,BCM_HS,TCM_HS,EBCM_HS
 SG_ DrvThrottlOvrrdDet : 28|1@0+ (1,0) [0|1] ""  CGM_HS,EBCM_OBD_HS,BCM_HS,EBCM_HS
 SG_ PT_CrnkAct : 6|1@0+ (1,0) [0|1] ""  CGM_HS,ICCM_OBD_HS,EBCM_OBD_HS,ICCM_HS,EPS_HS,BCP_HS,EBCM_HS
 SG_ PTRunAbrt : 4|1@0+ (1,0) [0|1] ""  CGM_HS,BCP_HS,BCM_HS
 SG_ PTO_PT_RunAbrtd : 3|1@0+ (1,0) [0|1] ""  CGM_HS,BCM_HS
 SG_ PTCrnkAbrted : 5|1@0+ (1,0) [0|1] ""  CGM_HS,BCP_HS,BCM_HS
 SG_ EngSpdStat : 1|2@0+ (1,0) [0|3] ""  CGM_HS,ICCM_OBD_HS,EBCM_OBD_HS,ICCM_HS,EPS_HS,BCP_HS,EPB_HS,TCCM_HS,BCM_HS,TCM_HS,EBCM_HS
 SG_ EngSpd : 15|16@0+ (0.25,0) [0|16383.75] "rpm"  CGM_HS,ICCM_OBD_HS,EBCM_OBD_HS,ICCM_HS,EPS_HS,BCP_HS,ONSTAR_HS,EPB_HS,TCCM_HS,BCM_HS,EBCM_HS
 SG_ EngRunAtv : 7|1@0+ (1,0) [0|1] ""  CGM_HS,ICCM_OBD_HS,EBCM_OBD_HS,ICCM_HS,EPS_HS,BCP_HS,ONSTAR_HS,EPB_HS,TCCM_HS,BCM_HS,EBCM_HS
 SG_ EngIdlAtv : 2|1@0+ (1,0) [0|1] ""  CGM_HS,EPB_HS,BCM_HS
 SG_ AccActPosV : 31|1@0+ (1,0) [0|1] ""  CGM_HS,ICCM_OBD_HS,EBCM_OBD_HS,ICCM_HS,BCP_HS,EPB_HS,TCCM_HS,BCM_HS,TCM_HS,EBCM_HS

BO_ 501 PPEI_Trans_General_Status_2: 8 ECM_HS
 SG_ TmpDrvrShftCtlAct : 45|1@0+ (1,0) [0|1] ""  CGM_HS,BCM_HS
 SG_ EngRecDwnshftIO : 54|1@0+ (1,0) [0|1] ""  CGM_HS,BCM_HS
 SG_ TrnsPattSelEcnMdOCm : 52|1@0+ (1,0) [0|1] ""  CGM_HS,ICCM_OBD_HS,ICCM_HS,ECM_HS
 SG_ CltStartSwAtvV : 38|1@0+ (1,0) [0|1] ""  CGM_HS,TCCM_HS,BCM_HS
 SG_ CltStartSwAtv : 37|1@0+ (1,0) [0|1] ""  CGM_HS,TCCM_HS,BCM_HS
 SG_ CltchPdlActPosV : 55|1@0+ (1,0) [0|1] ""  CGM_HS,ICCM_OBD_HS,EBCM_OBD_HS,ICCM_HS,EPB_HS,TCCM_HS,EBCM_HS,ECM_HS
 SG_ CltchPdlActPos : 63|8@0+ (0.392157,0) [0|100.000035] "%"  CGM_HS,ICCM_OBD_HS,EBCM_OBD_HS,ICCM_HS,EPB_HS,TCCM_HS,EBCM_HS,ECM_HS
 SG_ TrnsEngdStateV : 50|1@0+ (1,0) [0|1] ""  CGM_HS,ICCM_OBD_HS,ICCM_HS,BCP_HS,EBCM_OBD_HS,EPB_HS,BCM_HS,EBCM_HS
 SG_ TrnsEngdState : 49|2@0+ (1,0) [0|3] ""  CGM_HS,ICCM_OBD_HS,ICCM_HS,BCP_HS,EBCM_OBD_HS,EPB_HS,BCM_HS,EBCM_HS
 SG_ TrnsShftLvrLckRqd : 47|1@0+ (1,0) [0|1] ""  CGM_HS,ICCM_OBD_HS,ICCM_HS,BCM_HS
 SG_ TransTUDMdStat : 41|2@0+ (1,0) [0|3] ""  CGM_HS,ICCM_OBD_HS,ICCM_HS,BCP_HS,EBCM_OBD_HS,BCM_HS,EBCM_HS,ECM_HS
 SG_ TrnCrpMdAtv : 46|1@0+ (1,0) [0|1] ""  CGM_HS,ICCM_OBD_HS,ICCM_HS,BCM_HS,ECM_HS
 SG_ TrnsSkpShftIO : 23|1@0+ (1,0) [0|1] ""  CGM_HS,ICCM_OBD_HS,ICCM_HS,BCM_HS
 SG_ TrnsSftMdStat : 34|3@0+ (1,0) [0|7] ""  CGM_HS,ICCM_OBD_HS,ICCM_HS,EBCM_OBD_HS,BCM_HS,EBCM_HS
 SG_ TrnsRngInhbtStat : 31|3@0+ (1,0) [0|7] ""  CGM_HS,ICCM_OBD_HS,ICCM_HS,BCM_HS
 SG_ TopTrvlCltchSwActV : 15|1@0+ (1,0) [0|1] ""  CGM_HS,EBCM_OBD_HS,EPB_HS,BCM_HS,EBCM_HS
 SG_ TopTrvlCltchSwAct : 14|1@0+ (1,0) [0|1] ""  CGM_HS,EBCM_OBD_HS,EPB_HS,BCM_HS,EBCM_HS
 SG_ EngRecmndUpshftIO : 22|1@0+ (1,0) [0|1] ""  CGM_HS,BCM_HS
 SG_ DrvtShftCntrlTrgtGear : 19|4@0+ (1,0) [0|15] ""  CGM_HS,ICCM_OBD_HS,ICCM_HS,BCM_HS
 SG_ DrShftCntrlReqDndIO : 21|1@0+ (1,0) [0|1] ""  CGM_HS,ICCM_OBD_HS,ICCM_HS,BCM_HS
 SG_ TrnShftPtrnActStat : 44|3@0+ (1,0) [0|7] ""  CGM_HS,ICCM_OBD_HS,ICCM_HS,EPS_HS,EBCM_OBD_HS,BCM_HS,EBCM_HS
 SG_ TrnsFldPrsPrsnt : 51|1@0+ (1,0) [0|1] ""  CGM_HS,ECM_HS
 SG_ TrnsShftLvrPos : 27|4@0+ (1,0) [0|15] ""  CGM_HS,ICCM_OBD_HS,ICCM_HS,HMIM_HS,EPS_HS,BCP_HS,EBCM_OBD_HS,EPB_HS,BCM_HS,EBCM_HS,ECM_HS
 SG_ TrnsShftLvrPosV : 28|1@0+ (1,0) [0|1] ""  CGM_HS,ICCM_OBD_HS,ICCM_HS,HMIM_HS,EPS_HS,BCP_HS,EBCM_OBD_HS,EPB_HS,BCM_HS,EBCM_HS,ECM_HS
 SG_ TrnsTrqCnvCltCmndMd : 7|3@0+ (1,0) [0|7] ""  CGM_HS,BCP_HS,ECM_HS
 SG_ AutoTransComndGear : 11|4@0+ (1,0) [0|15] ""  CGM_HS,ICCM_OBD_HS,ICCM_HS,BCP_HS,EBCM_OBD_HS,TCCM_HS,BCM_HS,EBCM_HS,ECM_HS
 SG_ AutoTransGrSftDirect : 13|2@0+ (1,0) [0|3] ""  CGM_HS,ICCM_OBD_HS,ICCM_HS,BCP_HS,EBCM_OBD_HS,EBCM_HS,ECM_HS
 SG_ TransEstGear : 3|4@0+ (1,0) [0|15] ""  CGM_HS,ICCM_OBD_HS,ICCM_HS,HMIM_HS,EPS_HS,BCP_HS,EBCM_OBD_HS,ONSTAR_HS,EPB_HS,TCCM_HS,BCM_HS,EBCM_HS,ECM_HS
 SG_ TransEstGearV : 4|1@0+ (1,0) [0|1] ""  CGM_HS,ICCM_OBD_HS,ICCM_HS,HMIM_HS,EPS_HS,BCP_HS,EBCM_OBD_HS,ONSTAR_HS,EPB_HS,TCCM_HS,BCM_HS,EBCM_HS,ECM_HS

BO_ 1225 PPEI_Trans_General_Status_3: 7 ECM_HS
 SG_ TCTPIR_TnsEsClCDwT : 55|8@0+ (0.392157,0) [0|100.000035] "%"  CGM_HS,BCM_HS
 SG_ TCTPIR_TnsEsClTmpD : 47|8@0+ (0.392157,0) [0|100.000035] "%"  CGM_HS,BCM_HS
 SG_ TCTPIR_DrvNotfn : 35|4@0+ (1,0) [0|15] ""  CGM_HS,BCM_HS
 SG_ GrdBrkgAct : 39|1@0+ (1,0) [0|1] ""  CGM_HS,BCM_HS
 SG_ RrPTCoolFanRatFltStat : 37|2@0+ (1,0) [0|3] ""  CGM_HS,ICCM_OBD_HS,ICCM_HS
 SG_ TrnsThrmlMngmntStat : 1|2@0+ (1,0) [0|3] ""  CGM_HS,BCM_HS
 SG_ TrnsNEmsRltMalfActv : 4|1@0+ (1,0) [0|1] ""  CGM_HS,ONSTAR_HS,BCM_HS
 SG_ TransOilTempSensPres : 6|1@0+ (1,0) [0|1] ""  CGM_HS,ONSTAR_HS,TCCM_HS,BCM_HS
 SG_ TrnEmsMlfAtv : 5|1@0+ (1,0) [0|1] ""  CGM_HS,BCM_HS,ECM_HS
 SG_ TrnOilTmp : 15|8@0+ (1,-40) [-40|215] "deg C"  CGM_HS,BCP_HS,ONSTAR_HS,TCCM_HS,BCM_HS,ECM_HS
 SG_ TrnOilTmpV : 7|1@0+ (1,0) [0|1] ""  CGM_HS,BCP_HS,ONSTAR_HS,TCCM_HS,BCM_HS,ECM_HS
 SG_ TERDTC_SysDes : 23|4@0+ (1,0) [0|15] ""  CGM_HS,ECM_HS
 SG_ TERDTC_CdNum : 19|12@0+ (1,0) [0|4095] ""  CGM_HS,ECM_HS

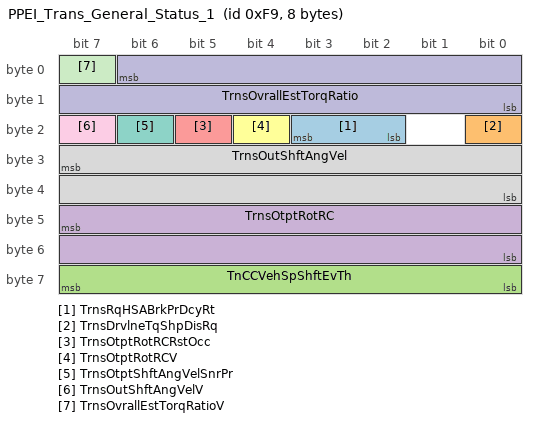
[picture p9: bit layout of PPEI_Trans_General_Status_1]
BO_ 249 PPEI_Trans_General_Status_1: 8 ECM_HS
 SG_ TrnsRqHSABrkPrDcyRt : 19|2@0+ (1,0) [0|3] ""  CGM_HS,EBCM_OBD_HS,EBCM_HS
 SG_ TrnsDrvlneTqShpDisRq : 16|1@0+ (1,0) [0|1] ""  CGM_HS,ECM_HS
 SG_ TnCCVehSpShftEvTh : 63|8@0+ (2,0) [0|510] "km / h"  CGM_HS,ECM_HS
 SG_ TrnsOtptRotRC : 47|16@0+ (0.0078125,0) [0|511.9921875] "rot"  CGM_HS,EBCM_OBD_HS,EBCM_HS,ECM_HS
 SG_ TrnsOtptRotRCRstOcc : 21|1@0+ (1,0) [0|1] ""  CGM_HS,EBCM_OBD_HS,EBCM_HS,ECM_HS
 SG_ TrnsOtptRotRCV : 20|1@0+ (1,0) [0|1] ""  CGM_HS,EBCM_OBD_HS,EBCM_HS,ECM_HS
 SG_ TrnsOtptShftAngVelSnrPr : 22|1@0+ (1,0) [0|1] ""  CGM_HS,TCCM_HS,ECM_HS
 SG_ TrnsOutShftAngVel : 31|16@0+ (0.25,0) [0|16383.75] "rpm"  CGM_HS,EBCM_OBD_HS,TCCM_HS,EBCM_HS,ECM_HS
 SG_ TrnsOutShftAngVelV : 23|1@0+ (1,0) [0|1] ""  CGM_HS,EBCM_OBD_HS,TCCM_HS,EBCM_HS,ECM_HS
 SG_ TrnsOvrallEstTorqRatio : 6|15@0- (0.00390625,0) [-64|63.99609375] ""  CGM_HS,EBCM_OBD_HS,TCCM_HS,EBCM_HS,ECM_HS
 SG_ TrnsOvrallEstTorqRatioV : 7|1@0+ (1,0) [0|1] ""  CGM_HS,EBCM_OBD_HS,TCCM_HS,EBCM_HS,ECM_HS

BO_ 2024 USDT_Resp_From_ECM_HS: 8 ECM_HS
 SG_ DgnInf : 7|64@0+ (1,0) [0|1.84467440737096E+019] ""  CGM_HS,TestTool_HS,ONSTAR_HS

BO_ 1512 UUDT_Resp_From_ECM: 8 ECM_HS
 SG_ DgnInf : 7|64@0+ (1,0) [0|1.84467440737096E+019] ""  CGM_HS,TestTool_HS,ONSTAR_HS

BO_TX_BU_ 463 : TCCM_HS,ECM_HS;
BO_TX_BU_ 501 : TCM_HS,ECM_HS;
BO_TX_BU_ 1225 : TCM_HS,ECM_HS;
BO_TX_BU_ 249 : TCM_HS,ECM_HS;
CM_ SG_ 1906 DTCI_DTCFaultType_772 "Based on Powertrain definition.  Not expected to be supported by all devices.";
CM_ SG_ 1906 DTCI_DTCFailType_772 "Assigned per GMW3110, Appendix E";
CM_ SG_ 1906 DTCI_DTCSource_772 "This shall be equal to the Diagnostic Address of the transmittting device.";
CM_ SG_ 401 EngTrqTnsRqFld "Indicates that the Engine controller will not honor the torque request from the Transmission Controller due to a failure in the Rolling count, protection value, etc.";
CM_ SG_ 401 EngNTrnsRegStdyStTqV "ETEI 3.1";
CM_ SG_ 401 EngNTrnsRegStdyStTq "ETEI 3.1";
CM_ SG_ 401 EngAirflwStdyStTorqV "ETEI 3.1";
CM_ SG_ 401 EngAirflwStdyStTorq "ETEI 3.1";
CM_ SG_ 401 EngActStdyStTorqV "ETEI 3.1";
CM_ SG_ 401 EngActStdyStTorq "ETEI 3.1";
CM_ SG_ 417 TracCntlSysPwrtrnInhbt "ETEI 3.1";
CM_ SG_ 977 ACCmpNrmLdGrdAld "dm3/m/s = dm3/minute/second";
CM_ BO_ 201 "Changed for PPEI 3.6";
CM_ SG_ 201 EngRunAtv "Indication from powertrain that the engine is running (Has RPM > 0)";
CM_ SG_ 501 TrnShftPtrnActStat "(PT = Powertrain)";
BA_DEF_ SG_  "VNSigSLHSSharedDiagnostic" ENUM  "No","Yes";
BA_DEF_ SG_  "VNSigSLHS_VNReq" ENUM  "No","Yes";
BA_DEF_ SG_  "GenSigSendOnInit" ENUM  "Not Initialized","Application","Handler";
BA_DEF_ SG_  "GenSigSendType" ENUM  "not used","not used","not used","not used","not used","not used","not used","NoSigSendType","not used","not used","OnAnyChange","OnChangeIfActive","OnDelta";
BA_DEF_ SG_  "GenSigDeltaValue" INT 0 0;
BA_DEF_ SG_  "VNSigAllNodes" ENUM  "No","Yes";
BA_DEF_ SG_  "SignalType" STRING ;
BA_DEF_ SG_  "PacketOrder" INT 0 65535;
BA_DEF_ SG_  "SignalLongName" STRING ;
BA_DEF_ SG_  "GenSigStartValue" INT 0 65535;
BA_DEF_ SG_  "TxSignalSendOnInit" ENUM  "Not Initialized","Application","Handler";
BA_DEF_ BO_  "GenMsgILSupport" ENUM  "No","Yes";
BA_DEF_ BO_  "AppGenMsgCycleTime" INT 0 0;
BA_DEF_ BO_  "TpApplType" STRING ;
BA_DEF_ BO_  "Prio" INT 0 7;
BA_DEF_ BO_  "MessageSubnet" ENUM  "LS","MS","HS","CE","PE","HV","FO","S1","HE","LE","HE2","vector_leerstring";
BA_DEF_ BO_  "DiagState" ENUM  "No","Yes";
BA_DEF_ BO_  "GenMsgIlSupport" ENUM  "No","Yes";
BA_DEF_ BO_  "GenMsgStartDelayTime" INT 0 100000;
BA_DEF_ BO_  "GenMsgDelayTime" INT 0 100000;
BA_DEF_ BO_  "GenMsgCycleTime" INT 0 100000;
BA_DEF_ BO_  "GenMsgSendType" ENUM  "cyclicX","spontanX","cyclicIfActiveX","spontanWithDelay","cyclicAndSpontanX","cyclicAndSpontanWithDelay","spontanWithRepitition","cyclicIfActiveAndSpontanWD";
BA_DEF_ BO_  "DiagResponse" ENUM  "No","Yes";
BA_DEF_ BO_  "DiagRequest" ENUM  "No","Yes";
BA_DEF_ BO_  "NmMessage" ENUM  "No","Yes";
BA_DEF_REL_ BU_SG_REL_  "GenSigSuprvResp" ENUM  "None","Notify App","Substitute Default";
BA_DEF_REL_ BU_SG_REL_  "GenSigSuprvRespSubValue" INT 0 65535;
BA_DEF_REL_ BU_SG_REL_  "GenSigRxStartValue" STRING ;
BA_DEF_REL_ BU_SG_REL_  "GenSigVDAFailResp" ENUM  "No","Yes";
BA_DEF_REL_ BU_SG_REL_  "GenSigVDAFailComment" STRING ;
BA_DEF_REL_ BU_SG_REL_  "GenSigVBitRespComment" STRING ;
BA_DEF_REL_ BU_SG_REL_  "GenSigVBitResp" ENUM  "No","Yes";
BA_DEF_REL_ BU_SG_REL_  "GenSigSuprvRespComment" STRING ;
BA_DEF_REL_ BU_SG_REL_  "GenSigTimeoutMsg" HEX 0 268435455;
BA_DEF_REL_ BU_SG_REL_  "GenSigTimeoutTime" INT 0 5000;
BA_DEF_DEF_  "VNSigSLHSSharedDiagnostic" "No";
BA_DEF_DEF_  "VNSigSLHS_VNReq" "No";
BA_DEF_DEF_  "GenSigSendOnInit" "Not Initialized";
BA_DEF_DEF_  "GenSigSendType" "NoSigSendType";
BA_DEF_DEF_  "GenSigDeltaValue" 0;
BA_DEF_DEF_  "VNSigAllNodes" "No";
BA_DEF_DEF_  "SignalType" "";
BA_DEF_DEF_  "PacketOrder" 0;
BA_DEF_DEF_  "SignalLongName" "";
BA_DEF_DEF_  "GenSigStartValue" 0;
BA_DEF_DEF_  "TxSignalSendOnInit" "Not Initialized";
BA_DEF_DEF_  "GenMsgILSupport" "Yes";
BA_DEF_DEF_  "AppGenMsgCycleTime" 0;
BA_DEF_DEF_  "TpApplType" "";
BA_DEF_DEF_  "Prio" 0;
BA_DEF_DEF_  "MessageSubnet" "LS";
BA_DEF_DEF_  "DiagState" "No";
BA_DEF_DEF_  "GenMsgIlSupport" "Yes";
BA_DEF_DEF_  "GenMsgStartDelayTime" 0;
BA_DEF_DEF_  "GenMsgDelayTime" 0;
BA_DEF_DEF_  "GenMsgCycleTime" 0;
BA_DEF_DEF_  "GenMsgSendType" "spontanX";
BA_DEF_DEF_  "DiagResponse" "No";
BA_DEF_DEF_  "DiagRequest" "No";
BA_DEF_DEF_  "NmMessage" "No";
BA_DEF_DEF_REL_ "GenSigSuprvResp" "None";
BA_DEF_DEF_REL_ "GenSigSuprvRespSubValue" 0;
BA_DEF_DEF_REL_ "GenSigRxStartValue" "";
BA_DEF_DEF_REL_ "GenSigVDAFailResp" "No";
BA_DEF_DEF_REL_ "GenSigVDAFailComment" "";
BA_DEF_DEF_REL_ "GenSigVBitRespComment" "";
BA_DEF_DEF_REL_ "GenSigVBitResp" "No";
BA_DEF_DEF_REL_ "GenSigSuprvRespComment" "";
BA_DEF_DEF_REL_ "GenSigTimeoutMsg" 0;
BA_DEF_DEF_REL_ "GenSigTimeoutTime" 0;
BA_ "GenMsgSendType" BO_ 463 0;
BA_ "GenMsgCycleTime" BO_ 463 100;
BA_ "MessageSubnet" BO_ 463 2;
BA_ "GenMsgSendType" BO_ 953 0;
BA_ "GenMsgCycleTime" BO_ 953 100;
BA_ "MessageSubnet" BO_ 953 2;
BA_ "GenMsgSendType" BO_ 1011 0;
BA_ "GenMsgCycleTime" BO_ 1011 250;
BA_ "MessageSubnet" BO_ 1011 2;
BA_ "GenMsgSendType" BO_ 490 0;
BA_ "GenMsgCycleTime" BO_ 490 12;
BA_ "MessageSubnet" BO_ 490 2;
BA_ "GenMsgSendType" BO_ 1267 0;
BA_ "GenMsgCycleTime" BO_ 1267 1000;
BA_ "MessageSubnet" BO_ 1267 2;
BA_ "GenMsgSendType" BO_ 453 0;
BA_ "GenMsgCycleTime" BO_ 453 25;
BA_ "MessageSubnet" BO_ 453 2;
BA_ "GenMsgSendType" BO_ 452 0;
BA_ "GenMsgCycleTime" BO_ 452 25;
BA_ "MessageSubnet" BO_ 452 2;
BA_ "GenMsgSendType" BO_ 190 0;
BA_ "GenMsgCycleTime" BO_ 190 12;
BA_ "MessageSubnet" BO_ 190 2;
BA_ "GenMsgSendType" BO_ 451 0;
BA_ "GenMsgCycleTime" BO_ 451 25;
BA_ "MessageSubnet" BO_ 451 2;
BA_ "GenMsgSendType" BO_ 495 0;
BA_ "GenMsgCycleTime" BO_ 495 12;
BA_ "MessageSubnet" BO_ 495 2;
BA_ "GenMsgSendType" BO_ 1906 0;
BA_ "GenMsgCycleTime" BO_ 1906 1000;
BA_ "MessageSubnet" BO_ 1906 2;
BA_ "Prio" BO_ 1906 6;
BA_ "GenMsgSendType" BO_ 1001 0;
BA_ "GenMsgCycleTime" BO_ 1001 100;
BA_ "MessageSubnet" BO_ 1001 2;
BA_ "GenMsgSendType" BO_ 961 0;
BA_ "GenMsgCycleTime" BO_ 961 100;
BA_ "MessageSubnet" BO_ 961 2;
BA_ "GenMsgSendType" BO_ 1019 0;
BA_ "GenMsgCycleTime" BO_ 1019 250;
BA_ "MessageSubnet" BO_ 1019 2;
BA_ "GenMsgSendType" BO_ 493 0;
BA_ "GenMsgCycleTime" BO_ 493 12;
BA_ "MessageSubnet" BO_ 493 2;
BA_ "GenMsgSendType" BO_ 401 0;
BA_ "GenMsgCycleTime" BO_ 401 12;
BA_ "MessageSubnet" BO_ 401 2;
BA_ "GenMsgSendType" BO_ 707 0;
BA_ "GenMsgCycleTime" BO_ 707 50;
BA_ "MessageSubnet" BO_ 707 2;
BA_ "GenMsgSendType" BO_ 1265 0;
BA_ "GenMsgCycleTime" BO_ 1265 1000;
BA_ "MessageSubnet" BO_ 1265 2;
BA_ "GenMsgSendType" BO_ 417 0;
BA_ "GenMsgCycleTime" BO_ 417 25;
BA_ "MessageSubnet" BO_ 417 2;
BA_ "GenMsgSendType" BO_ 1233 0;
BA_ "GenMsgCycleTime" BO_ 1233 500;
BA_ "MessageSubnet" BO_ 1233 2;
BA_ "GenMsgSendType" BO_ 1217 0;
BA_ "GenMsgCycleTime" BO_ 1217 500;
BA_ "MessageSubnet" BO_ 1217 2;
BA_ "GenMsgSendType" BO_ 665 0;
BA_ "GenMsgCycleTime" BO_ 665 100;
BA_ "MessageSubnet" BO_ 665 2;
BA_ "GenMsgSendType" BO_ 985 0;
BA_ "GenMsgCycleTime" BO_ 985 100;
BA_ "MessageSubnet" BO_ 985 2;
BA_ "GenMsgSendType" BO_ 1017 0;
BA_ "GenMsgCycleTime" BO_ 1017 250;
BA_ "MessageSubnet" BO_ 1017 2;
BA_ "GenMsgSendType" BO_ 977 0;
BA_ "GenMsgCycleTime" BO_ 977 100;
BA_ "MessageSubnet" BO_ 977 2;
BA_ "GenMsgSendType" BO_ 201 0;
BA_ "GenMsgCycleTime" BO_ 201 12;
BA_ "MessageSubnet" BO_ 201 2;
BA_ "GenMsgSendType" BO_ 501 0;
BA_ "GenMsgCycleTime" BO_ 501 25;
BA_ "MessageSubnet" BO_ 501 2;
BA_ "GenMsgSendType" BO_ 1225 0;
BA_ "GenMsgCycleTime" BO_ 1225 500;
BA_ "MessageSubnet" BO_ 1225 2;
BA_ "GenMsgSendType" BO_ 249 0;
BA_ "GenMsgCycleTime" BO_ 249 12;
BA_ "MessageSubnet" BO_ 249 2;
BA_ "DiagResponse" BO_ 2024 1;
BA_ "MessageSubnet" BO_ 2024 2;
BA_ "MessageSubnet" BO_ 1512 2;
BA_ "TpApplType" BO_ 1512 "DiagUUDTResponse";
BA_ "GenMsgILSupport" BO_ 1512 0;
BA_ "SignalLongName" SG_ 463 FourWhlDrvIndReq "Four Wheel Drive Indication Request";
BA_ "SignalType" SG_ 463 FourWhlDrvIndReq "ENM";
BA_ "VNSigAllNodes" SG_ 463 FourWhlDrvIndReq 1;
BA_ "SignalLongName" SG_ 463 TrnsfrCsRngShfSpdLmt "Transfer Case Range Shift Speed Limit";
BA_ "SignalType" SG_ 463 TrnsfrCsRngShfSpdLmt "UNM";
BA_ "VNSigAllNodes" SG_ 463 TrnsfrCsRngShfSpdLmt 1;
BA_ "SignalLongName" SG_ 463 SecAxlNonEmMalfIO "Secondary Axle Non-emissions Malf Ind On";
BA_ "SignalType" SG_ 463 SecAxlNonEmMalfIO "BLN";
BA_ "VNSigAllNodes" SG_ 463 SecAxlNonEmMalfIO 1;
BA_ "SignalLongName" SG_ 463 SecAxlOperMod "Secondary Axle Operational Mode";
BA_ "SignalType" SG_ 463 SecAxlOperMod "ENM";
BA_ "VNSigAllNodes" SG_ 463 SecAxlOperMod 1;
BA_ "SignalLongName" SG_ 463 SecAxlTmpInhIO "Secondary Axle Temporary Inhibit Indication On";
BA_ "SignalType" SG_ 463 SecAxlTmpInhIO "BLN";
BA_ "VNSigAllNodes" SG_ 463 SecAxlTmpInhIO 1;
BA_ "SignalLongName" SG_ 953 DslGlwTypReqd "Diesel Glow Type Requested";
BA_ "SignalType" SG_ 953 DslGlwTypReqd "ENM";
BA_ "VNSigAllNodes" SG_ 953 DslGlwTypReqd 1;
BA_ "SignalLongName" SG_ 953 RdctHtrCReq "Reductant Heater C Request";
BA_ "SignalType" SG_ 953 RdctHtrCReq "ENM";
BA_ "VNSigAllNodes" SG_ 953 RdctHtrCReq 1;
BA_ "SignalLongName" SG_ 953 RdctHtrBReq "Reductant Heater B Request";
BA_ "SignalType" SG_ 953 RdctHtrBReq "ENM";
BA_ "VNSigAllNodes" SG_ 953 RdctHtrBReq 1;
BA_ "SignalLongName" SG_ 953 RdctHtrAReq "Reductant Heater A Request";
BA_ "SignalType" SG_ 953 RdctHtrAReq "ENM";
BA_ "VNSigAllNodes" SG_ 953 RdctHtrAReq 1;
BA_ "SignalLongName" SG_ 953 EngPwrCnfg "Engine Power Configuration";
BA_ "SignalType" SG_ 953 EngPwrCnfg "ENM";
BA_ "VNSigAllNodes" SG_ 953 EngPwrCnfg 1;
BA_ "SignalLongName" SG_ 953 EngCntlSenPTRlyVltM "Engine Controller Sensed Powertrain Relay Voltage Mask";
BA_ "SignalType" SG_ 953 EngCntlSenPTRlyVltM "ENM";
BA_ "VNSigAllNodes" SG_ 953 EngCntlSenPTRlyVltM 1;
BA_ "SignalLongName" SG_ 953 EngCntlSenPTRlyVlt "Engine Controller Sensed Powertrain Relay Voltage";
BA_ "SignalType" SG_ 953 EngCntlSenPTRlyVlt "UNM";
BA_ "VNSigAllNodes" SG_ 953 EngCntlSenPTRlyVlt 1;
BA_ "SignalLongName" SG_ 953 CrntFlConsmpV "Current Fuel Consumption Validity";
BA_ "SignalType" SG_ 953 CrntFlConsmpV "ENM";
BA_ "VNSigAllNodes" SG_ 953 CrntFlConsmpV 1;
BA_ "SignalLongName" SG_ 953 CrntFlConsmp "Current Fuel Consumption";
BA_ "SignalType" SG_ 953 CrntFlConsmp "UNM";
BA_ "VNSigAllNodes" SG_ 953 CrntFlConsmp 1;
BA_ "SignalLongName" SG_ 953 InAirHtrDtyCyclCmnd "Intake Air Heater Duty Cycle Command";
BA_ "SignalType" SG_ 953 InAirHtrDtyCyclCmnd "UNM";
BA_ "VNSigAllNodes" SG_ 953 InAirHtrDtyCyclCmnd 1;
BA_ "SignalLongName" SG_ 953 DslPartFltrClngAlgActM "Diesel Particle Filter Cleaning Algorithm Active Mask";
BA_ "SignalType" SG_ 953 DslPartFltrClngAlgActM "ENM";
BA_ "VNSigAllNodes" SG_ 953 DslPartFltrClngAlgActM 1;
BA_ "SignalLongName" SG_ 953 DslPartFltrClngAlgAct "Diesel Particle Filter Cleaning Algorithm Active";
BA_ "SignalType" SG_ 953 DslPartFltrClngAlgAct "BLN";
BA_ "VNSigAllNodes" SG_ 953 DslPartFltrClngAlgAct 1;
BA_ "SignalLongName" SG_ 953 MassAirFloV "Mass Air Flow Validity";
BA_ "SignalType" SG_ 953 MassAirFloV "ENM";
BA_ "VNSigAllNodes" SG_ 953 MassAirFloV 1;
BA_ "SignalLongName" SG_ 953 MassAirFlo "Mass Air Flow";
BA_ "SignalType" SG_ 953 MassAirFlo "UNM";
BA_ "VNSigAllNodes" SG_ 953 MassAirFlo 1;
BA_ "SignalLongName" SG_ 953 GlwPlgReqdOn "Glow Plugs Requested On";
BA_ "SignalType" SG_ 953 GlwPlgReqdOn "BLN";
BA_ "VNSigAllNodes" SG_ 953 GlwPlgReqdOn 1;
BA_ "SignalLongName" SG_ 953 NOxSnsrDiagAftrRnReq "NOx Sensor Diagnostic After Run Request";
BA_ "SignalType" SG_ 953 NOxSnsrDiagAftrRnReq "UNM";
BA_ "VNSigAllNodes" SG_ 953 NOxSnsrDiagAftrRnReq 1;
BA_ "SignalLongName" SG_ 1011 BatVltHiResV "Battery Voltage High Resolution Validity";
BA_ "SignalType" SG_ 1011 BatVltHiResV "ENM";
BA_ "VNSigAllNodes" SG_ 1011 BatVltHiResV 1;
BA_ "GenSigStartValue" SG_ 1011 BatVltHiRes 12800;
BA_ "SignalLongName" SG_ 1011 BatVltHiRes "Battery Voltage High Resolution";
BA_ "SignalType" SG_ 1011 BatVltHiRes "UNM";
BA_ "VNSigAllNodes" SG_ 1011 BatVltHiRes 1;
BA_ "SignalLongName" SG_ 1011 BatCrntExtRngV "Battery Current Extended Range Validity";
BA_ "SignalType" SG_ 1011 BatCrntExtRngV "ENM";
BA_ "VNSigAllNodes" SG_ 1011 BatCrntExtRngV 1;
BA_ "SignalLongName" SG_ 1011 BatCrntExtRng "Battery Current Extended Range";
BA_ "SignalType" SG_ 1011 BatCrntExtRng "UNM";
BA_ "VNSigAllNodes" SG_ 1011 BatCrntExtRng 1;
BA_ "SignalLongName" SG_ 1011 BatSnsrlntFlt "Intelligent Battery Sensor Internal Fault";
BA_ "SignalType" SG_ 1011 BatSnsrlntFlt "BLN";
BA_ "VNSigAllNodes" SG_ 1011 BatSnsrlntFlt 1;
BA_ "SignalLongName" SG_ 1011 BatCrntExtRngM "Battery Current Extended Range Mask";
BA_ "SignalType" SG_ 1011 BatCrntExtRngM "ENM";
BA_ "VNSigAllNodes" SG_ 1011 BatCrntExtRngM 1;
BA_ "SignalLongName" SG_ 1011 BatVltHiResM "Battery Voltage High Resolution Mask";
BA_ "SignalType" SG_ 1011 BatVltHiResM "ENM";
BA_ "VNSigAllNodes" SG_ 1011 BatVltHiResM 1;
BA_ "SignalLongName" SG_ 490 SrvcFlSysPrkInOpnArIO "Service Fuel System Park In Open Area Indication On";
BA_ "SignalType" SG_ 490 SrvcFlSysPrkInOpnArIO "BLN";
BA_ "VNSigAllNodes" SG_ 490 SrvcFlSysPrkInOpnArIO 1;
BA_ "GenSigSendType" SG_ 490 SrvcFlSysPrkInOpnArIO 10;
BA_ "SignalLongName" SG_ 490 FuelSysNEmsRltMalfAct "Fuel System Non Emissions Related Malfunction Active";
BA_ "SignalType" SG_ 490 FuelSysNEmsRltMalfAct "BLN";
BA_ "VNSigAllNodes" SG_ 490 FuelSysNEmsRltMalfAct 1;
BA_ "GenSigSendType" SG_ 490 FuelSysNEmsRltMalfAct 10;
BA_ "SignalLongName" SG_ 490 InActFuelMdFuelLvlIO "Inactive Fuel Mode Fuel Level Indication On";
BA_ "SignalType" SG_ 490 InActFuelMdFuelLvlIO "BLN";
BA_ "VNSigAllNodes" SG_ 490 InActFuelMdFuelLvlIO 1;
BA_ "GenSigSendType" SG_ 490 InActFuelMdFuelLvlIO 10;
BA_ "SignalLongName" SG_ 490 FuelTotCapTnk2 "Fuel Total Capacity Tank 2";
BA_ "SignalType" SG_ 490 FuelTotCapTnk2 "UNM";
BA_ "VNSigAllNodes" SG_ 490 FuelTotCapTnk2 1;
BA_ "SignalLongName" SG_ 490 FlLvlTank2PctV "Fuel Level Tank 2 Percent Validity";
BA_ "SignalType" SG_ 490 FlLvlTank2PctV "ENM";
BA_ "VNSigAllNodes" SG_ 490 FlLvlTank2PctV 1;
BA_ "SignalLongName" SG_ 490 FlLvlTank2Pct "Fuel Level Tank 2 Percent";
BA_ "SignalType" SG_ 490 FlLvlTank2Pct "UNM";
BA_ "VNSigAllNodes" SG_ 490 FlLvlTank2Pct 1;
BA_ "SignalLongName" SG_ 490 AltFuelPHeatAct "Alternative Fuel Pre-heating Active";
BA_ "SignalType" SG_ 490 AltFuelPHeatAct "BLN";
BA_ "VNSigAllNodes" SG_ 490 AltFuelPHeatAct 1;
BA_ "SignalLongName" SG_ 490 AltFuelMdReqDndIO "Alternative Fuel Mode Request Denied Indication On";
BA_ "SignalType" SG_ 490 AltFuelMdReqDndIO "BLN";
BA_ "VNSigAllNodes" SG_ 490 AltFuelMdReqDndIO 1;
BA_ "SignalLongName" SG_ 490 AltFuelLvlLo "Alternative Fuel Level Low";
BA_ "SignalType" SG_ 490 AltFuelLvlLo "BLN";
BA_ "VNSigAllNodes" SG_ 490 AltFuelLvlLo 1;
BA_ "SignalLongName" SG_ 490 AltFuelAccWrnngAct "Alternative Fuel Acceleration Warning Active";
BA_ "SignalType" SG_ 490 AltFuelAccWrnngAct "BLN";
BA_ "VNSigAllNodes" SG_ 490 AltFuelAccWrnngAct 1;
BA_ "SignalLongName" SG_ 490 FuelMdStat "Fuel Mode Status";
BA_ "SignalType" SG_ 490 FuelMdStat "ENM";
BA_ "VNSigAllNodes" SG_ 490 FuelMdStat 1;
BA_ "SignalLongName" SG_ 1267 VehMassNom "Vehicle Mass Nominal";
BA_ "SignalType" SG_ 1267 VehMassNom "UNM";
BA_ "VNSigAllNodes" SG_ 1267 VehMassNom 1;
BA_ "SignalLongName" SG_ 453 DrvIntndAxlTrqV "Driver Intended Axle Torque Validity";
BA_ "SignalType" SG_ 453 DrvIntndAxlTrqV "ENM";
BA_ "VNSigAllNodes" SG_ 453 DrvIntndAxlTrqV 1;
BA_ "SignalLongName" SG_ 453 DrvIntndAxlTrqMinV "Driver Intended Axle Torque Minimum Validity";
BA_ "SignalType" SG_ 453 DrvIntndAxlTrqMinV "ENM";
BA_ "VNSigAllNodes" SG_ 453 DrvIntndAxlTrqMinV 1;
BA_ "SignalLongName" SG_ 453 DrvIntndAxlTrqMin "Driver Intended Axle Torque Minimum";
BA_ "SignalType" SG_ 453 DrvIntndAxlTrqMin "UNM";
BA_ "VNSigAllNodes" SG_ 453 DrvIntndAxlTrqMin 1;
BA_ "SignalLongName" SG_ 453 DrvIntndAxlTrqMaxV "Driver Intended Axle Torque Maximum Validity";
BA_ "SignalType" SG_ 453 DrvIntndAxlTrqMaxV "ENM";
BA_ "VNSigAllNodes" SG_ 453 DrvIntndAxlTrqMaxV 1;
BA_ "GenSigStartValue" SG_ 453 DrvIntndAxlTrqMax 32767;
BA_ "SignalLongName" SG_ 453 DrvIntndAxlTrqMax "Driver Intended Axle Torque Maximum";
BA_ "SignalType" SG_ 453 DrvIntndAxlTrqMax "UNM";
BA_ "VNSigAllNodes" SG_ 453 DrvIntndAxlTrqMax 1;
BA_ "GenSigStartValue" SG_ 453 DrvIntndAxlTrq 11267;
BA_ "SignalLongName" SG_ 453 DrvIntndAxlTrq "Driver Intended Axle Torque";
BA_ "SignalType" SG_ 453 DrvIntndAxlTrq "UNM";
BA_ "VNSigAllNodes" SG_ 453 DrvIntndAxlTrq 1;
BA_ "SignalLongName" SG_ 452 FSpRgACCSwADdPVal "Full Speed Range ACC Cruise Switch Action Detected Protection Value";
BA_ "SignalType" SG_ 452 FSpRgACCSwADdPVal "UNM";
BA_ "VNSigAllNodes" SG_ 452 FSpRgACCSwADdPVal 1;
BA_ "SignalLongName" SG_ 452 FSpRgACCSwADdARC "Full Speed Range ACC Cruise Switch Action Detected Alive Rolling Count";
BA_ "SignalType" SG_ 452 FSpRgACCSwADdARC "UNM";
BA_ "VNSigAllNodes" SG_ 452 FSpRgACCSwADdARC 1;
BA_ "SignalLongName" SG_ 452 FSpRgACCSwADd "Full Speed Range ACC Cruise Switch Action Detected";
BA_ "SignalType" SG_ 452 FSpRgACCSwADd "BLN";
BA_ "VNSigAllNodes" SG_ 452 FSpRgACCSwADd 1;
BA_ "SignalLongName" SG_ 452 AutBrkAccActPsStRC "Autonomous Braking Accelerator Actual Position Status Rolling Count";
BA_ "SignalType" SG_ 452 AutBrkAccActPsStRC "UNM";
BA_ "VNSigAllNodes" SG_ 452 AutBrkAccActPsStRC 1;
BA_ "SignalLongName" SG_ 452 AutBrkAccActPsStPVal "Autonomous Braking Accelerator Actual Position Status Protection Value";
BA_ "SignalType" SG_ 452 AutBrkAccActPsStPVal "UNM";
BA_ "VNSigAllNodes" SG_ 452 AutBrkAccActPsStPVal 1;
BA_ "SignalLongName" SG_ 452 ABAAPS_AccPos "Autonomous Braking Accelerator Actual Position Status : Accelerator Position";
BA_ "PacketOrder" SG_ 452 ABAAPS_AccPos 2;
BA_ "SignalType" SG_ 452 ABAAPS_AccPos "UNM";
BA_ "VNSigAllNodes" SG_ 452 ABAAPS_AccPos 1;
BA_ "SignalLongName" SG_ 452 ABAAPS_AccPosV "Autonomous Braking Accelerator Actual Position Status : Accelerator Position Validity";
BA_ "PacketOrder" SG_ 452 ABAAPS_AccPosV 1;
BA_ "SignalType" SG_ 452 ABAAPS_AccPosV "ENM";
BA_ "VNSigAllNodes" SG_ 452 ABAAPS_AccPosV 1;
BA_ "SignalLongName" SG_ 452 ACCATCS_LmtgStat "Adaptive Cruise Control Axle Torque Command Status : Limiting Status";
BA_ "PacketOrder" SG_ 452 ACCATCS_LmtgStat 2;
BA_ "SignalType" SG_ 452 ACCATCS_LmtgStat "ENM";
BA_ "VNSigAllNodes" SG_ 452 ACCATCS_LmtgStat 1;
BA_ "SignalLongName" SG_ 452 ACCATCS_RqStat "Adaptive Cruise Control Axle Torque Command Status : Request Status";
BA_ "PacketOrder" SG_ 452 ACCATCS_RqStat 1;
BA_ "SignalType" SG_ 452 ACCATCS_RqStat "ENM";
BA_ "VNSigAllNodes" SG_ 452 ACCATCS_RqStat 1;
BA_ "SignalLongName" SG_ 452 RdLdNomAxlTrq "Road Load Nominal Axle Torque";
BA_ "SignalType" SG_ 452 RdLdNomAxlTrq "UNM";
BA_ "VNSigAllNodes" SG_ 452 RdLdNomAxlTrq 1;
BA_ "SignalLongName" SG_ 452 AccPdlOvrrdAtvProtVal "Accelerator Pedal Override Active Protection Value";
BA_ "SignalType" SG_ 452 AccPdlOvrrdAtvProtVal "UNM";
BA_ "VNSigAllNodes" SG_ 452 AccPdlOvrrdAtvProtVal 1;
BA_ "SignalLongName" SG_ 452 AccPdlOvrrdAtvARC "Accelerator Pedal Override Active Alive Rolling Count";
BA_ "SignalType" SG_ 452 AccPdlOvrrdAtvARC "UNM";
BA_ "VNSigAllNodes" SG_ 452 AccPdlOvrrdAtvARC 1;
BA_ "SignalLongName" SG_ 452 AccPdlOvrrdAtv "Accelerator Pedal Override Active";
BA_ "SignalType" SG_ 452 AccPdlOvrrdAtv "BLN";
BA_ "VNSigAllNodes" SG_ 452 AccPdlOvrrdAtv 1;
BA_ "SignalLongName" SG_ 452 CPSATCS_ReqStatus "Collision Preparation System Axle Torque Command Status : Request Status";
BA_ "PacketOrder" SG_ 452 CPSATCS_ReqStatus 2;
BA_ "SignalType" SG_ 452 CPSATCS_ReqStatus "ENM";
BA_ "VNSigAllNodes" SG_ 452 CPSATCS_ReqStatus 1;
BA_ "SignalLongName" SG_ 452 CPSATCS_LmtngStatus "Collision Preparation System Axle Torque Command Status : Limiting Status";
BA_ "PacketOrder" SG_ 452 CPSATCS_LmtngStatus 1;
BA_ "SignalType" SG_ 452 CPSATCS_LmtngStatus "ENM";
BA_ "VNSigAllNodes" SG_ 452 CPSATCS_LmtngStatus 1;
BA_ "SignalLongName" SG_ 452 RVBATCS_ReqStat "Rear Virtual Bumper Axle Torque Command Status : Request Status";
BA_ "PacketOrder" SG_ 452 RVBATCS_ReqStat 2;
BA_ "SignalType" SG_ 452 RVBATCS_ReqStat "ENM";
BA_ "VNSigAllNodes" SG_ 452 RVBATCS_ReqStat 1;
BA_ "SignalLongName" SG_ 452 RVBATCS_LmtngStat "Rear Virtual Bumper Axle Torque Command Status : Limiting Status";
BA_ "PacketOrder" SG_ 452 RVBATCS_LmtngStat 1;
BA_ "SignalType" SG_ 452 RVBATCS_LmtngStat "ENM";
BA_ "VNSigAllNodes" SG_ 452 RVBATCS_LmtngStat 1;
BA_ "SignalLongName" SG_ 190 EngSpdMaxCapRdcdRng "Engine Speed Maximum Capacity Reduced Range";
BA_ "SignalType" SG_ 190 EngSpdMaxCapRdcdRng "UNM";
BA_ "VNSigAllNodes" SG_ 190 EngSpdMaxCapRdcdRng 1;
BA_ "SignalLongName" SG_ 190 PTSnsdBrkPdlInfPVal "Powertrain Sensed Brake Pedal Information Protection Value";
BA_ "SignalType" SG_ 190 PTSnsdBrkPdlInfPVal "UNM";
BA_ "VNSigAllNodes" SG_ 190 PTSnsdBrkPdlInfPVal 1;
BA_ "SignalLongName" SG_ 190 TrnsAuxPmpAct "Transmission Auxiliary Pump Active";
BA_ "SignalType" SG_ 190 TrnsAuxPmpAct "BLN";
BA_ "VNSigAllNodes" SG_ 190 TrnsAuxPmpAct 1;
BA_ "SignalLongName" SG_ 190 AccPos "Accelerator Effective Position";
BA_ "SignalType" SG_ 190 AccPos "UNM";
BA_ "VNSigAllNodes" SG_ 190 AccPos 1;
BA_ "SignalLongName" SG_ 190 PTSnsdBrkPdlInfARC "Powertrain Sensed Brake Pedal Information Alive Rolling Count";
BA_ "SignalType" SG_ 190 PTSnsdBrkPdlInfARC "UNM";
BA_ "VNSigAllNodes" SG_ 190 PTSnsdBrkPdlInfARC 1;
BA_ "SignalLongName" SG_ 190 PSBPI_PTSnBrkPdlPsV "Powertrain Sensed Brake Pedal Information : Powertrain Sensed Brake Pedal Position Validity";
BA_ "PacketOrder" SG_ 190 PSBPI_PTSnBrkPdlPsV 1;
BA_ "SignalType" SG_ 190 PSBPI_PTSnBrkPdlPsV "ENM";
BA_ "VNSigAllNodes" SG_ 190 PSBPI_PTSnBrkPdlPsV 1;
BA_ "SignalLongName" SG_ 190 PSBPI_PTSnBrkPdlPs "Powertrain Sensed Brake Pedal Information : Powertrain Sensed Brake Pedal Position";
BA_ "PacketOrder" SG_ 190 PSBPI_PTSnBrkPdlPs 2;
BA_ "SignalType" SG_ 190 PSBPI_PTSnBrkPdlPs "UNM";
BA_ "VNSigAllNodes" SG_ 190 PSBPI_PTSnBrkPdlPs 1;
BA_ "SignalLongName" SG_ 451 HillDscntCtrlSwStatPVal "Hill Descent Control Switch Status Protection Value";
BA_ "SignalType" SG_ 451 HillDscntCtrlSwStatPVal "UNM";
BA_ "VNSigAllNodes" SG_ 451 HillDscntCtrlSwStatPVal 1;
BA_ "SignalLongName" SG_ 451 HillDscntCtrlSwStatARC "Hill Descent Control Switch Status Alive Rolling Count";
BA_ "SignalType" SG_ 451 HillDscntCtrlSwStatARC "UNM";
BA_ "VNSigAllNodes" SG_ 451 HillDscntCtrlSwStatARC 1;
BA_ "SignalLongName" SG_ 451 HillDscntCtrlSwStat "Hill Descent Control Switch Status";
BA_ "SignalType" SG_ 451 HillDscntCtrlSwStat "ENM";
BA_ "VNSigAllNodes" SG_ 451 HillDscntCtrlSwStat 1;
BA_ "SignalLongName" SG_ 451 GlwPlgCrnkDelAct "Glow Plugs Crank Delay Active";
BA_ "SignalType" SG_ 451 GlwPlgCrnkDelAct "BLN";
BA_ "VNSigAllNodes" SG_ 451 GlwPlgCrnkDelAct 1;
BA_ "SignalLongName" SG_ 451 AuxHtrAlwd "Auxiliary Heater Allowed";
BA_ "SignalType" SG_ 451 AuxHtrAlwd "BLN";
BA_ "VNSigAllNodes" SG_ 451 AuxHtrAlwd 1;
BA_ "SignalLongName" SG_ 451 AppCltchAutSrtIO "Apply Clutch For Automatic Start Indication On";
BA_ "SignalType" SG_ 451 AppCltchAutSrtIO "BLN";
BA_ "VNSigAllNodes" SG_ 451 AppCltchAutSrtIO 1;
BA_ "SignalLongName" SG_ 451 AccPosV "Accelerator Effective Position Validity";
BA_ "SignalType" SG_ 451 AccPosV "ENM";
BA_ "VNSigAllNodes" SG_ 451 AccPosV 1;
BA_ "SignalLongName" SG_ 451 AccPos "Accelerator Effective Position";
BA_ "SignalType" SG_ 451 AccPos "UNM";
BA_ "VNSigAllNodes" SG_ 451 AccPos 1;
BA_ "SignalLongName" SG_ 451 FuelFltRmnLf "Fuel Filter Remaining Life";
BA_ "SignalType" SG_ 451 FuelFltRmnLf "UNM";
BA_ "VNSigAllNodes" SG_ 451 FuelFltRmnLf 1;
BA_ "SignalLongName" SG_ 451 EngTrqRdFlrSt "Engine Torque Reduction Failure Status";
BA_ "SignalType" SG_ 451 EngTrqRdFlrSt "ENM";
BA_ "VNSigAllNodes" SG_ 451 EngTrqRdFlrSt 1;
BA_ "SignalLongName" SG_ 451 EngTrqDrRqdExtRngV "Engine Torque Driver Requested Extended Range Validity";
BA_ "SignalType" SG_ 451 EngTrqDrRqdExtRngV "ENM";
BA_ "VNSigAllNodes" SG_ 451 EngTrqDrRqdExtRngV 1;
BA_ "GenSigStartValue" SG_ 451 EngTrqDrRqdExtRng 1696;
BA_ "SignalLongName" SG_ 451 EngTrqDrRqdExtRng "Engine Torque Driver Requested Extended Range";
BA_ "SignalType" SG_ 451 EngTrqDrRqdExtRng "UNM";
BA_ "VNSigAllNodes" SG_ 451 EngTrqDrRqdExtRng 1;
BA_ "SignalLongName" SG_ 451 EngTrqActExtRngV "Engine Torque Actual Extended Range Validity";
BA_ "SignalType" SG_ 451 EngTrqActExtRngV "ENM";
BA_ "VNSigAllNodes" SG_ 451 EngTrqActExtRngV 1;
BA_ "GenSigStartValue" SG_ 451 EngTrqActExtRng 1696;
BA_ "SignalLongName" SG_ 451 EngTrqActExtRng "Engine Torque Actual Extended Range";
BA_ "SignalType" SG_ 451 EngTrqActExtRng "UNM";
BA_ "VNSigAllNodes" SG_ 451 EngTrqActExtRng 1;
BA_ "SignalLongName" SG_ 495 MassAirFloV "Mass Air Flow Validity";
BA_ "SignalType" SG_ 495 MassAirFloV "ENM";
BA_ "VNSigAllNodes" SG_ 495 MassAirFloV 1;
BA_ "SignalLongName" SG_ 495 MassAirFlo "Mass Air Flow";
BA_ "SignalType" SG_ 495 MassAirFlo "UNM";
BA_ "VNSigAllNodes" SG_ 495 MassAirFlo 1;
BA_ "SignalLongName" SG_ 1906 DTCI_DTCFaultType_772 "Diagnostic Trouble Code Information Extended 772 : Diagnostic Trouble Code Fault Type";
BA_ "PacketOrder" SG_ 1906 DTCI_DTCFaultType_772 20;
BA_ "SignalType" SG_ 1906 DTCI_DTCFaultType_772 "ENM";
BA_ "VNSigAllNodes" SG_ 1906 DTCI_DTCFaultType_772 1;
BA_ "SignalLongName" SG_ 1906 DTCI_CodeSupported_772 "Diagnostic Trouble Code Information Extended 772 : Code Supported";
BA_ "PacketOrder" SG_ 1906 DTCI_CodeSupported_772 19;
BA_ "SignalType" SG_ 1906 DTCI_CodeSupported_772 "BLN";
BA_ "VNSigAllNodes" SG_ 1906 DTCI_CodeSupported_772 1;
BA_ "SignalLongName" SG_ 1906 DTCI_CurrentStatus_772 "Diagnostic Trouble Code Information Extended 772 : Current Status";
BA_ "PacketOrder" SG_ 1906 DTCI_CurrentStatus_772 18;
BA_ "SignalType" SG_ 1906 DTCI_CurrentStatus_772 "BLN";
BA_ "VNSigAllNodes" SG_ 1906 DTCI_CurrentStatus_772 1;
BA_ "SignalLongName" SG_ 1906 DTCI_TstNPsdCdClrdSt_772 "Diagnostic Trouble Code Information Extended 772 : Test Not Passed Since Code Cleared Status";
BA_ "PacketOrder" SG_ 1906 DTCI_TstNPsdCdClrdSt_772 17;
BA_ "SignalType" SG_ 1906 DTCI_TstNPsdCdClrdSt_772 "BLN";
BA_ "VNSigAllNodes" SG_ 1906 DTCI_TstNPsdCdClrdSt_772 1;
BA_ "SignalLongName" SG_ 1906 DTCI_TstFldCdClrdStat_772 "Diagnostic Trouble Code Information Extended 772 : Test Failed Since Code Cleared Status";
BA_ "PacketOrder" SG_ 1906 DTCI_TstFldCdClrdStat_772 16;
BA_ "SignalType" SG_ 1906 DTCI_TstFldCdClrdStat_772 "BLN";
BA_ "VNSigAllNodes" SG_ 1906 DTCI_TstFldCdClrdStat_772 1;
BA_ "SignalLongName" SG_ 1906 DTCI_HistStat_772 "Diagnostic Trouble Code Information Extended 772 : History Status";
BA_ "PacketOrder" SG_ 1906 DTCI_HistStat_772 15;
BA_ "SignalType" SG_ 1906 DTCI_HistStat_772 "BLN";
BA_ "VNSigAllNodes" SG_ 1906 DTCI_HistStat_772 1;
BA_ "SignalLongName" SG_ 1906 DTCI_TstNPsdPwrUpSt_772 "Diagnostic Trouble Code Information Extended 772 : Test Not Passed Since Power Up Status";
BA_ "PacketOrder" SG_ 1906 DTCI_TstNPsdPwrUpSt_772 14;
BA_ "SignalType" SG_ 1906 DTCI_TstNPsdPwrUpSt_772 "BLN";
BA_ "VNSigAllNodes" SG_ 1906 DTCI_TstNPsdPwrUpSt_772 1;
BA_ "SignalLongName" SG_ 1906 DTCI_TstFldPwrUpSt_772 "Diagnostic Trouble Code Information Extended 772 : Test Failed Since Power Up Status";
BA_ "PacketOrder" SG_ 1906 DTCI_TstFldPwrUpSt_772 13;
BA_ "SignalType" SG_ 1906 DTCI_TstFldPwrUpSt_772 "BLN";
BA_ "VNSigAllNodes" SG_ 1906 DTCI_TstFldPwrUpSt_772 1;
BA_ "SignalLongName" SG_ 1906 DTCI_WrnIndRqdSt_772 "Diagnostic Trouble Code Information Extended 772 : Warning Indicator Requested Status";
BA_ "PacketOrder" SG_ 1906 DTCI_WrnIndRqdSt_772 12;
BA_ "SignalType" SG_ 1906 DTCI_WrnIndRqdSt_772 "BLN";
BA_ "VNSigAllNodes" SG_ 1906 DTCI_WrnIndRqdSt_772 1;
BA_ "SignalLongName" SG_ 1906 DTCI_DTCFailType_772 "Diagnostic Trouble Code Information Extended 772 : Diagnostic Trouble Code Failure Type";
BA_ "PacketOrder" SG_ 1906 DTCI_DTCFailType_772 11;
BA_ "SignalType" SG_ 1906 DTCI_DTCFailType_772 "UNM";
BA_ "VNSigAllNodes" SG_ 1906 DTCI_DTCFailType_772 1;
BA_ "SignalLongName" SG_ 1906 DTCI_DTCNumber_772 "Diagnostic Trouble Code Information Extended 772 : Diagnostic Trouble Code Number";
BA_ "PacketOrder" SG_ 1906 DTCI_DTCNumber_772 10;
BA_ "SignalType" SG_ 1906 DTCI_DTCNumber_772 "UNM";
BA_ "VNSigAllNodes" SG_ 1906 DTCI_DTCNumber_772 1;
BA_ "SignalLongName" SG_ 1906 DTCI_DTCSource_772 "Diagnostic Trouble Code Information Extended 772 : Diagnostic Trouble Code Source";
BA_ "PacketOrder" SG_ 1906 DTCI_DTCSource_772 9;
BA_ "SignalType" SG_ 1906 DTCI_DTCSource_772 "UNM";
BA_ "VNSigAllNodes" SG_ 1906 DTCI_DTCSource_772 1;
BA_ "SignalLongName" SG_ 1906 DTCI_DTCTriggered_772 "Diagnostic Trouble Code Information Extended 772 : Diagnostic Trouble Code Triggered";
BA_ "PacketOrder" SG_ 1906 DTCI_DTCTriggered_772 8;
BA_ "SignalType" SG_ 1906 DTCI_DTCTriggered_772 "BLN";
BA_ "VNSigAllNodes" SG_ 1906 DTCI_DTCTriggered_772 1;
BA_ "SignalLongName" SG_ 1906 DTCIUnused7_772 "Diagnostic Trouble Code Information Extended 772 : Unused 7";
BA_ "PacketOrder" SG_ 1906 DTCIUnused7_772 7;
BA_ "SignalType" SG_ 1906 DTCIUnused7_772 "BLN";
BA_ "VNSigAllNodes" SG_ 1906 DTCIUnused7_772 1;
BA_ "SignalLongName" SG_ 1906 DTCIUnused6_772 "Diagnostic Trouble Code Information Extended 772 : Unused 6";
BA_ "PacketOrder" SG_ 1906 DTCIUnused6_772 6;
BA_ "SignalType" SG_ 1906 DTCIUnused6_772 "BLN";
BA_ "VNSigAllNodes" SG_ 1906 DTCIUnused6_772 1;
BA_ "SignalLongName" SG_ 1906 DTCIUnused5_772 "Diagnostic Trouble Code Information Extended 772 : Unused 5";
BA_ "PacketOrder" SG_ 1906 DTCIUnused5_772 5;
BA_ "SignalType" SG_ 1906 DTCIUnused5_772 "BLN";
BA_ "VNSigAllNodes" SG_ 1906 DTCIUnused5_772 1;
BA_ "SignalLongName" SG_ 1906 DTCIUnused4_772 "Diagnostic Trouble Code Information Extended 772 : Unused 4";
BA_ "PacketOrder" SG_ 1906 DTCIUnused4_772 4;
BA_ "SignalType" SG_ 1906 DTCIUnused4_772 "BLN";
BA_ "VNSigAllNodes" SG_ 1906 DTCIUnused4_772 1;
BA_ "SignalLongName" SG_ 1906 DTCIUnused3_772 "Diagnostic Trouble Code Information Extended 772 : Unused 3";
BA_ "PacketOrder" SG_ 1906 DTCIUnused3_772 3;
BA_ "SignalType" SG_ 1906 DTCIUnused3_772 "BLN";
BA_ "VNSigAllNodes" SG_ 1906 DTCIUnused3_772 1;
BA_ "SignalLongName" SG_ 1906 DTCIUnused2_772 "Diagnostic Trouble Code Information Extended 772 : Unused 2";
BA_ "PacketOrder" SG_ 1906 DTCIUnused2_772 2;
BA_ "SignalType" SG_ 1906 DTCIUnused2_772 "BLN";
BA_ "VNSigAllNodes" SG_ 1906 DTCIUnused2_772 1;
BA_ "SignalLongName" SG_ 1906 DTCIUnused1_772 "Diagnostic Trouble Code Information Extended 772 : Unused 1";
BA_ "PacketOrder" SG_ 1906 DTCIUnused1_772 1;
BA_ "SignalType" SG_ 1906 DTCIUnused1_772 "BLN";
BA_ "VNSigAllNodes" SG_ 1906 DTCIUnused1_772 1;
BA_ "SignalLongName" SG_ 1001 DistRollCntAvgDrvnSrc "Distance Rolling Count Average Driven Source";
BA_ "SignalType" SG_ 1001 DistRollCntAvgDrvnSrc "ENM";
BA_ "VNSigAllNodes" SG_ 1001 DistRollCntAvgDrvnSrc 1;
BA_ "SignalLongName" SG_ 1001 VehSpdAvgDrvnSrc "Vehicle Speed Average Driven Source";
BA_ "SignalType" SG_ 1001 VehSpdAvgDrvnSrc "ENM";
BA_ "VNSigAllNodes" SG_ 1001 VehSpdAvgDrvnSrc 1;
BA_ "SignalLongName" SG_ 1001 DstRolCntAvgNonDrvnV "Distance Rolling Count Average Non Driven Validity";
BA_ "SignalType" SG_ 1001 DstRolCntAvgNonDrvnV "ENM";
BA_ "VNSigAllNodes" SG_ 1001 DstRolCntAvgNonDrvnV 1;
BA_ "SignalLongName" SG_ 1001 DstRolCntAvNDrRstOc "Distance Rolling Count Average Non Driven Reset Occurred";
BA_ "SignalType" SG_ 1001 DstRolCntAvNDrRstOc "BLN";
BA_ "VNSigAllNodes" SG_ 1001 DstRolCntAvNDrRstOc 1;
BA_ "SignalLongName" SG_ 1001 DstRolCntAvgNonDrvn "Distance Rolling Count Average Non Driven";
BA_ "SignalType" SG_ 1001 DstRolCntAvgNonDrvn "UNM";
BA_ "VNSigAllNodes" SG_ 1001 DstRolCntAvgNonDrvn 1;
BA_ "SignalLongName" SG_ 1001 DistRollCntAvgDrvnV "Distance Rolling Count Average Driven Validity";
BA_ "SignalType" SG_ 1001 DistRollCntAvgDrvnV "ENM";
BA_ "VNSigAllNodes" SG_ 1001 DistRollCntAvgDrvnV 1;
BA_ "SignalLongName" SG_ 1001 DstRolCntAvgDrnRstOc "Distance Rolling Count Average Driven Reset Occurred";
BA_ "SignalType" SG_ 1001 DstRolCntAvgDrnRstOc "BLN";
BA_ "VNSigAllNodes" SG_ 1001 DstRolCntAvgDrnRstOc 1;
BA_ "SignalLongName" SG_ 1001 DistRollCntAvgDrvn "Distance Rolling Count Average Driven";
BA_ "SignalType" SG_ 1001 DistRollCntAvgDrvn "UNM";
BA_ "VNSigAllNodes" SG_ 1001 DistRollCntAvgDrvn 1;
BA_ "SignalLongName" SG_ 1001 VehSpdAvgNDrvnV "Vehicle Speed Average Non Driven Validity";
BA_ "SignalType" SG_ 1001 VehSpdAvgNDrvnV "ENM";
BA_ "VNSigAllNodes" SG_ 1001 VehSpdAvgNDrvnV 1;
BA_ "SignalLongName" SG_ 1001 VehSpdAvgNDrvn "Vehicle Speed Average Non Driven";
BA_ "SignalType" SG_ 1001 VehSpdAvgNDrvn "UNM";
BA_ "VNSigAllNodes" SG_ 1001 VehSpdAvgNDrvn 1;
BA_ "GenSigSendOnInit" SG_ 1001 VehSpdAvgNDrvn 1;
BA_ "SignalLongName" SG_ 1001 VehSpdAvgDrvnV "Vehicle Speed Average Driven Validity";
BA_ "SignalType" SG_ 1001 VehSpdAvgDrvnV "ENM";
BA_ "VNSigAllNodes" SG_ 1001 VehSpdAvgDrvnV 1;
BA_ "SignalLongName" SG_ 1001 VehSpdAvgDrvn "Vehicle Speed Average Driven";
BA_ "SignalType" SG_ 1001 VehSpdAvgDrvn "UNM";
BA_ "VNSigAllNodes" SG_ 1001 VehSpdAvgDrvn 1;
BA_ "SignalLongName" SG_ 961 PTImmblzerInfo "Powertrain Immobilizer Information";
BA_ "SignalType" SG_ 961 PTImmblzerInfo "UNM";
BA_ "VNSigAllNodes" SG_ 961 PTImmblzerInfo 1;
BA_ "SignalLongName" SG_ 1019 FuelAlchlCompAdptnPrg "Fuel Alcohol Composition Adaptation in Progress";
BA_ "SignalType" SG_ 1019 FuelAlchlCompAdptnPrg "BLN";
BA_ "VNSigAllNodes" SG_ 1019 FuelAlchlCompAdptnPrg 1;
BA_ "SignalLongName" SG_ 1019 FuelLvlEmnsRelStat "Fuel Level Emissions Related Status";
BA_ "SignalType" SG_ 1019 FuelLvlEmnsRelStat "ENM";
BA_ "VNSigAllNodes" SG_ 1019 FuelLvlEmnsRelStat 1;
BA_ "SignalLongName" SG_ 1019 EmnsRelFuelLvlLw "Emissions Related Fuel Level Low";
BA_ "SignalType" SG_ 1019 EmnsRelFuelLvlLw "BLN";
BA_ "VNSigAllNodes" SG_ 1019 EmnsRelFuelLvlLw 1;
BA_ "SignalLongName" SG_ 1019 EngFuelCntlState "Engine Fuel Control State";
BA_ "SignalType" SG_ 1019 EngFuelCntlState "ENM";
BA_ "VNSigAllNodes" SG_ 1019 EngFuelCntlState 1;
BA_ "SignalLongName" SG_ 1019 FuelAlcoholCompV "Fuel Alcohol Composition Validity";
BA_ "SignalType" SG_ 1019 FuelAlcoholCompV "ENM";
BA_ "VNSigAllNodes" SG_ 1019 FuelAlcoholCompV 1;
BA_ "SignalLongName" SG_ 1019 FuelAlcoholComp "Fuel Alcohol Composition";
BA_ "SignalType" SG_ 1019 FuelAlcoholComp "UNM";
BA_ "VNSigAllNodes" SG_ 1019 FuelAlcoholComp 1;
BA_ "SignalLongName" SG_ 493 EngRunng "Engine Running";
BA_ "SignalType" SG_ 493 EngRunng "BLN";
BA_ "VNSigAllNodes" SG_ 493 EngRunng 1;
BA_ "SignalLongName" SG_ 493 FlPmpEDscOtptCmdSta "Fuel Pump Enabled Discrete Output Commanded Status";
BA_ "SignalType" SG_ 493 FlPmpEDscOtptCmdSta "ENM";
BA_ "VNSigAllNodes" SG_ 493 FlPmpEDscOtptCmdSta 1;
BA_ "SignalLongName" SG_ 493 CmmndAirFuelRatio "Commanded Air Fuel Ratio";
BA_ "SignalType" SG_ 493 CmmndAirFuelRatio "UNM";
BA_ "VNSigAllNodes" SG_ 493 CmmndAirFuelRatio 1;
BA_ "SignalLongName" SG_ 493 AdvFuelFlowEst "Advanced Fuel Flow Estimate";
BA_ "SignalType" SG_ 493 AdvFuelFlowEst "UNM";
BA_ "VNSigAllNodes" SG_ 493 AdvFuelFlowEst 1;
BA_ "SignalLongName" SG_ 493 InstFuelFlowEst "Instantaneous Fuel Flow Estimate";
BA_ "SignalType" SG_ 493 InstFuelFlowEst "UNM";
BA_ "VNSigAllNodes" SG_ 493 InstFuelFlowEst 1;
BA_ "SignalLongName" SG_ 493 FuelDelPressRqd "Fuel Delivery Pressure Requested";
BA_ "SignalType" SG_ 493 FuelDelPressRqd "UNM";
BA_ "VNSigAllNodes" SG_ 493 FuelDelPressRqd 1;
BA_ "SignalLongName" SG_ 493 FuelCntlSysFltPrsnt "Fuel Control System Fault Present";
BA_ "SignalType" SG_ 493 FuelCntlSysFltPrsnt "BLN";
BA_ "VNSigAllNodes" SG_ 493 FuelCntlSysFltPrsnt 1;
BA_ "SignalLongName" SG_ 401 EngTrqTrnRqTmpFld "Engine Torque Transmission Request Temporarily Failed";
BA_ "SignalType" SG_ 401 EngTrqTrnRqTmpFld "BLN";
BA_ "VNSigAllNodes" SG_ 401 EngTrqTrnRqTmpFld 1;
BA_ "SignalLongName" SG_ 401 EngTrqTrnRqLmtd "Engine Torque Transmission Request Limited";
BA_ "SignalType" SG_ 401 EngTrqTrnRqLmtd "BLN";
BA_ "VNSigAllNodes" SG_ 401 EngTrqTrnRqLmtd 1;
BA_ "SignalLongName" SG_ 401 TrnsEngSpdReqFld "Transmission Engine Speed Request Failed";
BA_ "SignalType" SG_ 401 TrnsEngSpdReqFld "BLN";
BA_ "VNSigAllNodes" SG_ 401 TrnsEngSpdReqFld 1;
BA_ "SignalLongName" SG_ 401 ThrtCommndPos "Throttle Commanded Position";
BA_ "SignalType" SG_ 401 ThrtCommndPos "UNM";
BA_ "VNSigAllNodes" SG_ 401 ThrtCommndPos 1;
BA_ "SignalLongName" SG_ 401 EngTrqTnsRqFld "Engine Torque Transmission Request Failed";
BA_ "SignalType" SG_ 401 EngTrqTnsRqFld "BLN";
BA_ "VNSigAllNodes" SG_ 401 EngTrqTnsRqFld 1;
BA_ "SignalLongName" SG_ 401 EngTrqRdnFld "Engine Torque Reduction Failed";
BA_ "SignalType" SG_ 401 EngTrqRdnFld "BLN";
BA_ "VNSigAllNodes" SG_ 401 EngTrqRdnFld 1;
BA_ "SignalLongName" SG_ 401 EngNTrnsRegStdyStTqV "Engine Non-Transmission Regulated Steady State Torque Validity";
BA_ "SignalType" SG_ 401 EngNTrnsRegStdyStTqV "ENM";
BA_ "VNSigAllNodes" SG_ 401 EngNTrnsRegStdyStTqV 1;
BA_ "SignalLongName" SG_ 401 EngNTrnsRegStdyStTq "Engine Non-Transmission Regulated Steady State Torque";
BA_ "SignalType" SG_ 401 EngNTrnsRegStdyStTq "UNM";
BA_ "VNSigAllNodes" SG_ 401 EngNTrnsRegStdyStTq 1;
BA_ "SignalLongName" SG_ 401 EngAirflwStdyStTorqV "Engine Airflow Steady State Torque Validity";
BA_ "SignalType" SG_ 401 EngAirflwStdyStTorqV "ENM";
BA_ "VNSigAllNodes" SG_ 401 EngAirflwStdyStTorqV 1;
BA_ "SignalLongName" SG_ 401 EngAirflwStdyStTorq "Engine Airflow Steady State Torque";
BA_ "SignalType" SG_ 401 EngAirflwStdyStTorq "UNM";
BA_ "VNSigAllNodes" SG_ 401 EngAirflwStdyStTorq 1;
BA_ "SignalLongName" SG_ 401 AccKdwnAtv "Accelerator Kick Down Detected";
BA_ "SignalType" SG_ 401 AccKdwnAtv "BLN";
BA_ "VNSigAllNodes" SG_ 401 AccKdwnAtv 1;
BA_ "SignalLongName" SG_ 401 AccPosV "Accelerator Effective Position Validity";
BA_ "SignalType" SG_ 401 AccPosV "ENM";
BA_ "VNSigAllNodes" SG_ 401 AccPosV 1;
BA_ "SignalLongName" SG_ 401 AccPos "Accelerator Effective Position";
BA_ "SignalType" SG_ 401 AccPos "UNM";
BA_ "VNSigAllNodes" SG_ 401 AccPos 1;
BA_ "SignalLongName" SG_ 401 EngActStdyStTorqV "Engine Actual Steady State Torque Validity";
BA_ "SignalType" SG_ 401 EngActStdyStTorqV "ENM";
BA_ "VNSigAllNodes" SG_ 401 EngActStdyStTorqV 1;
BA_ "SignalLongName" SG_ 401 EngActStdyStTorq "Engine Actual Steady State Torque";
BA_ "SignalType" SG_ 401 EngActStdyStTorq "UNM";
BA_ "VNSigAllNodes" SG_ 401 EngActStdyStTorq 1;
BA_ "SignalLongName" SG_ 707 CSTATRS_ReqStat "Chassis System Total Axle Torque Request Status : Request Status";
BA_ "PacketOrder" SG_ 707 CSTATRS_ReqStat 2;
BA_ "SignalType" SG_ 707 CSTATRS_ReqStat "ENM";
BA_ "VNSigAllNodes" SG_ 707 CSTATRS_ReqStat 1;
BA_ "SignalLongName" SG_ 707 CSTATRS_LmtgStat "Chassis System Total Axle Torque Request Status : Limiting Status";
BA_ "PacketOrder" SG_ 707 CSTATRS_LmtgStat 1;
BA_ "SignalType" SG_ 707 CSTATRS_LmtgStat "ENM";
BA_ "VNSigAllNodes" SG_ 707 CSTATRS_LmtgStat 1;
BA_ "SignalLongName" SG_ 707 EngManfldAbsPrsV "Engine Manifold Absolute Pressure Validity";
BA_ "SignalType" SG_ 707 EngManfldAbsPrsV "ENM";
BA_ "VNSigAllNodes" SG_ 707 EngManfldAbsPrsV 1;
BA_ "SignalLongName" SG_ 707 EngManfldAbsPrs "Engine Manifold Absolute Pressure";
BA_ "SignalType" SG_ 707 EngManfldAbsPrs "UNM";
BA_ "VNSigAllNodes" SG_ 707 EngManfldAbsPrs 1;
BA_ "SignalLongName" SG_ 707 EngTrqMinExtRngV "Engine Torque Minimum Extended Range Validity";
BA_ "SignalType" SG_ 707 EngTrqMinExtRngV "ENM";
BA_ "VNSigAllNodes" SG_ 707 EngTrqMinExtRngV 1;
BA_ "GenSigStartValue" SG_ 707 EngTrqMinExtRng 1696;
BA_ "SignalLongName" SG_ 707 EngTrqMinExtRng "Engine Torque Minimum Extended Range";
BA_ "SignalType" SG_ 707 EngTrqMinExtRng "UNM";
BA_ "VNSigAllNodes" SG_ 707 EngTrqMinExtRng 1;
BA_ "SignalLongName" SG_ 707 EngTrqMaxExtRngV "Engine Torque Maximum Extended Range Validity";
BA_ "SignalType" SG_ 707 EngTrqMaxExtRngV "ENM";
BA_ "VNSigAllNodes" SG_ 707 EngTrqMaxExtRngV 1;
BA_ "GenSigStartValue" SG_ 707 EngTrqMaxExtRng 1696;
BA_ "SignalLongName" SG_ 707 EngTrqMaxExtRng "Engine Torque Maximum Extended Range";
BA_ "SignalType" SG_ 707 EngTrqMaxExtRng "UNM";
BA_ "VNSigAllNodes" SG_ 707 EngTrqMaxExtRng 1;
BA_ "SignalLongName" SG_ 1265 PTSysHzrdLghtReq "Powertrain System Hazard Lights Request";
BA_ "SignalType" SG_ 1265 PTSysHzrdLghtReq "BLN";
BA_ "VNSigAllNodes" SG_ 1265 PTSysHzrdLghtReq 1;
BA_ "SignalLongName" SG_ 1265 EngOffTmPT "Engine Off Time Powertrain";
BA_ "SignalType" SG_ 1265 EngOffTmPT "UNM";
BA_ "VNSigAllNodes" SG_ 1265 EngOffTmPT 1;
BA_ "SignalLongName" SG_ 1265 EngOffTmPTV "Engine Off Time Powertrain Validity";
BA_ "SignalType" SG_ 1265 EngOffTmPTV "ENM";
BA_ "VNSigAllNodes" SG_ 1265 EngOffTmPTV 1;
BA_ "SignalLongName" SG_ 1265 EngOffTmPTM "Engine Off Time Powertrain Mask";
BA_ "SignalType" SG_ 1265 EngOffTmPTM "ENM";
BA_ "VNSigAllNodes" SG_ 1265 EngOffTmPTM 1;
BA_ "SignalLongName" SG_ 1265 WhlDistPrRevNDrvn "Wheel Distance Per Revolution Non Driven";
BA_ "SignalType" SG_ 1265 WhlDistPrRevNDrvn "UNM";
BA_ "VNSigAllNodes" SG_ 1265 WhlDistPrRevNDrvn 1;
BA_ "SignalLongName" SG_ 1265 WhlDistPrRevDrvn "Wheel Distance Per Revolution Driven";
BA_ "SignalType" SG_ 1265 WhlDistPrRevDrvn "UNM";
BA_ "VNSigAllNodes" SG_ 1265 WhlDistPrRevDrvn 1;
BA_ "SignalLongName" SG_ 1265 DrvlnFnlAxleRatio "Driveline Final Axle Ratio";
BA_ "SignalType" SG_ 1265 DrvlnFnlAxleRatio "UNM";
BA_ "VNSigAllNodes" SG_ 1265 DrvlnFnlAxleRatio 1;
BA_ "SignalLongName" SG_ 417 EngCrsCntrlMode "Engine Cruise Control Mode";
BA_ "SignalType" SG_ 417 EngCrsCntrlMode "ENM";
BA_ "VNSigAllNodes" SG_ 417 EngCrsCntrlMode 1;
BA_ "SignalLongName" SG_ 417 EngPstOxgSnsDgAstRq "Engine Post Oxygen Sensor Diagnostic Assistance Requested";
BA_ "SignalType" SG_ 417 EngPstOxgSnsDgAstRq "BLN";
BA_ "VNSigAllNodes" SG_ 417 EngPstOxgSnsDgAstRq 1;
BA_ "SignalLongName" SG_ 417 CrsCtrlCnstSpdAct "Cruise Control Constant Speed Active";
BA_ "SignalType" SG_ 417 CrsCtrlCnstSpdAct "BLN";
BA_ "VNSigAllNodes" SG_ 417 CrsCtrlCnstSpdAct 1;
BA_ "SignalLongName" SG_ 417 WrmUpShftPtrnRq "Warm Up Shift Pattern Request";
BA_ "SignalType" SG_ 417 WrmUpShftPtrnRq "ENM";
BA_ "VNSigAllNodes" SG_ 417 WrmUpShftPtrnRq 1;
BA_ "SignalLongName" SG_ 417 EngIdlSpdRdcdRng "Engine Idle Speed Reduced Range";
BA_ "SignalType" SG_ 417 EngIdlSpdRdcdRng "UNM";
BA_ "VNSigAllNodes" SG_ 417 EngIdlSpdRdcdRng 1;
BA_ "SignalLongName" SG_ 417 EngAlwCltAdp "Engine Allowed Clutch Adaptation";
BA_ "SignalType" SG_ 417 EngAlwCltAdp "BLN";
BA_ "VNSigAllNodes" SG_ 417 EngAlwCltAdp 1;
BA_ "SignalLongName" SG_ 417 BsTrgtEngIdlSpd "Base Target Engine Idle Speed";
BA_ "SignalType" SG_ 417 BsTrgtEngIdlSpd "UNM";
BA_ "VNSigAllNodes" SG_ 417 BsTrgtEngIdlSpd 1;
BA_ "SignalLongName" SG_ 417 AccPdlPosPcntFullRngV "Accelerator Pedal Position Percent Full Range  Validity";
BA_ "SignalType" SG_ 417 AccPdlPosPcntFullRngV "ENM";
BA_ "VNSigAllNodes" SG_ 417 AccPdlPosPcntFullRngV 1;
BA_ "SignalLongName" SG_ 417 AccPdlPosPcntFullRng "Accelerator Pedal Position Percent Full Range";
BA_ "SignalType" SG_ 417 AccPdlPosPcntFullRng "UNM";
BA_ "VNSigAllNodes" SG_ 417 AccPdlPosPcntFullRng 1;
BA_ "SignalLongName" SG_ 417 DslPrtFltrIdlRgtnMdReq "Diesel Particulate Filter Idle Regeneration Mode Request";
BA_ "SignalType" SG_ 417 DslPrtFltrIdlRgtnMdReq "BLN";
BA_ "VNSigAllNodes" SG_ 417 DslPrtFltrIdlRgtnMdReq 1;
BA_ "SignalLongName" SG_ 417 DslPartFltrClngAlgActM "Diesel Particle Filter Cleaning Algorithm Active Mask";
BA_ "SignalType" SG_ 417 DslPartFltrClngAlgActM "ENM";
BA_ "VNSigAllNodes" SG_ 417 DslPartFltrClngAlgActM 1;
BA_ "SignalLongName" SG_ 417 DslPartFltrClngAlgAct "Diesel Particle Filter Cleaning Algorithm Active";
BA_ "SignalType" SG_ 417 DslPartFltrClngAlgAct "BLN";
BA_ "VNSigAllNodes" SG_ 417 DslPartFltrClngAlgAct 1;
BA_ "SignalLongName" SG_ 417 EngCylDeactMd "Engine Cylinder Deactivation Mode";
BA_ "SignalType" SG_ 417 EngCylDeactMd "ENM";
BA_ "VNSigAllNodes" SG_ 417 EngCylDeactMd 1;
BA_ "SignalLongName" SG_ 417 ACCmCltEngd "Air Conditioning Compressor Clutch Engaged";
BA_ "SignalType" SG_ 417 ACCmCltEngd "BLN";
BA_ "VNSigAllNodes" SG_ 417 ACCmCltEngd 1;
BA_ "SignalLongName" SG_ 417 ParkNeutralSwStatV "Park Neutral Switch Status Validity";
BA_ "SignalType" SG_ 417 ParkNeutralSwStatV "ENM";
BA_ "VNSigAllNodes" SG_ 417 ParkNeutralSwStatV 1;
BA_ "SignalLongName" SG_ 417 ParkNeutralSwStat "Park Neutral Switch Status";
BA_ "SignalType" SG_ 417 ParkNeutralSwStat "ENM";
BA_ "VNSigAllNodes" SG_ 417 ParkNeutralSwStat 1;
BA_ "SignalLongName" SG_ 417 EngColdHiIdleActive "Engine Cold High Idle Active";
BA_ "SignalType" SG_ 417 EngColdHiIdleActive "BLN";
BA_ "VNSigAllNodes" SG_ 417 EngColdHiIdleActive 1;
BA_ "SignalLongName" SG_ 417 EngCyDactTqSmtAct "Engine Cylinder Deactivation Torque Smoothing Active";
BA_ "SignalType" SG_ 417 EngCyDactTqSmtAct "BLN";
BA_ "VNSigAllNodes" SG_ 417 EngCyDactTqSmtAct 1;
BA_ "SignalLongName" SG_ 417 EngBrkStat "Engine Brake Status";
BA_ "SignalType" SG_ 417 EngBrkStat "ENM";
BA_ "VNSigAllNodes" SG_ 417 EngBrkStat 1;
BA_ "SignalLongName" SG_ 417 TracCntlSysPwrtrnInhbt "Traction Control System Powertrain Inhibit";
BA_ "SignalType" SG_ 417 TracCntlSysPwrtrnInhbt "BLN";
BA_ "VNSigAllNodes" SG_ 417 TracCntlSysPwrtrnInhbt 1;
BA_ "SignalLongName" SG_ 417 EngMtlProtAtv "Engine Metal Protection Active";
BA_ "SignalType" SG_ 417 EngMtlProtAtv "BLN";
BA_ "VNSigAllNodes" SG_ 417 EngMtlProtAtv 1;
BA_ "SignalLongName" SG_ 417 EngDgTrqCnvClUnlkRqd "Engine Diagnostic Torque Converter Clutch Unlock Requested";
BA_ "SignalType" SG_ 417 EngDgTrqCnvClUnlkRqd "BLN";
BA_ "VNSigAllNodes" SG_ 417 EngDgTrqCnvClUnlkRqd 1;
BA_ "SignalLongName" SG_ 417 EngCyldrDeactReqd "Engine Cylinder Deactivation Requested";
BA_ "SignalType" SG_ 417 EngCyldrDeactReqd "BLN";
BA_ "VNSigAllNodes" SG_ 417 EngCyldrDeactReqd 1;
BA_ "SignalLongName" SG_ 417 ETGRReqdGear "Engine Transmission Gear Request : Requested Gear";
BA_ "PacketOrder" SG_ 417 ETGRReqdGear 2;
BA_ "SignalType" SG_ 417 ETGRReqdGear "ENM";
BA_ "VNSigAllNodes" SG_ 417 ETGRReqdGear 1;
BA_ "SignalLongName" SG_ 417 ETGRReqType "Engine Transmission Gear Request : Request Type";
BA_ "PacketOrder" SG_ 417 ETGRReqType 1;
BA_ "SignalType" SG_ 417 ETGRReqType "ENM";
BA_ "VNSigAllNodes" SG_ 417 ETGRReqType 1;
BA_ "SignalLongName" SG_ 1233 a_12VBatSysUnstab "12 Volt Battery System Unstable";
BA_ "SignalType" SG_ 1233 a_12VBatSysUnstab "BLN";
BA_ "VNSigAllNodes" SG_ 1233 a_12VBatSysUnstab 1;
BA_ "GenSigSendType" SG_ 1233 a_12VBatSysUnstab 10;
BA_ "SignalLongName" SG_ 1233 EngShtdwnAct "Engine Shutdown Active";
BA_ "SignalType" SG_ 1233 EngShtdwnAct "BLN";
BA_ "VNSigAllNodes" SG_ 1233 EngShtdwnAct 1;
BA_ "SignalLongName" SG_ 1233 EngShtdwnPndgIO "Engine Shutdown Pending Indication On";
BA_ "SignalType" SG_ 1233 EngShtdwnPndgIO "BLN";
BA_ "VNSigAllNodes" SG_ 1233 EngShtdwnPndgIO 1;
BA_ "SignalLongName" SG_ 1233 FuelFltChgNwIO "Fuel Filter Change Now Indication On";
BA_ "SignalType" SG_ 1233 FuelFltChgNwIO "BLN";
BA_ "VNSigAllNodes" SG_ 1233 FuelFltChgNwIO 1;
BA_ "SignalLongName" SG_ 1233 PTExPrtclFltrWrn2IO "Powertrain Exhaust Particle Filter Warning 2 Indication On";
BA_ "SignalType" SG_ 1233 PTExPrtclFltrWrn2IO "BLN";
BA_ "VNSigAllNodes" SG_ 1233 PTExPrtclFltrWrn2IO 1;
BA_ "SignalLongName" SG_ 1233 PTHiElecLdReqd "Powertrain High Electrical Load Requested";
BA_ "SignalType" SG_ 1233 PTHiElecLdReqd "BLN";
BA_ "VNSigAllNodes" SG_ 1233 PTHiElecLdReqd 1;
BA_ "SignalLongName" SG_ 1233 PTExPrtclFltrWrnIO "Powertrain Exhaust Particle Filter Warning Indication On";
BA_ "SignalType" SG_ 1233 PTExPrtclFltrWrnIO "BLN";
BA_ "VNSigAllNodes" SG_ 1233 PTExPrtclFltrWrnIO 1;
BA_ "SignalLongName" SG_ 1233 AirCndOffIO "Air Conditioning Off Indication On";
BA_ "SignalType" SG_ 1233 AirCndOffIO "BLN";
BA_ "VNSigAllNodes" SG_ 1233 AirCndOffIO 1;
BA_ "SignalLongName" SG_ 1233 DslGlwPlgIO "Diesel Glow Plug Indication On";
BA_ "SignalType" SG_ 1233 DslGlwPlgIO "BLN";
BA_ "VNSigAllNodes" SG_ 1233 DslGlwPlgIO 1;
BA_ "SignalLongName" SG_ 1233 RdcdPwrIO "Reduced Power Indication On";
BA_ "SignalType" SG_ 1233 RdcdPwrIO "BLN";
BA_ "VNSigAllNodes" SG_ 1233 RdcdPwrIO 1;
BA_ "SignalLongName" SG_ 1233 FuelTotCap "Fuel Total Capacity";
BA_ "SignalType" SG_ 1233 FuelTotCap "UNM";
BA_ "VNSigAllNodes" SG_ 1233 FuelTotCap 1;
BA_ "GenSigSendOnInit" SG_ 1233 FuelTotCap 1;
BA_ "SignalLongName" SG_ 1233 FlLvlPctV "Fuel Level Percent Validity";
BA_ "SignalType" SG_ 1233 FlLvlPctV "ENM";
BA_ "VNSigAllNodes" SG_ 1233 FlLvlPctV 1;
BA_ "GenSigSendOnInit" SG_ 1233 FlLvlPctV 1;
BA_ "SignalLongName" SG_ 1233 FlLvlPct "Fuel Level Percent";
BA_ "SignalType" SG_ 1233 FlLvlPct "UNM";
BA_ "VNSigAllNodes" SG_ 1233 FlLvlPct 1;
BA_ "GenSigDeltaValue" SG_ 1233 FlLvlPct 2;
BA_ "GenSigSendOnInit" SG_ 1233 FlLvlPct 1;
BA_ "SignalLongName" SG_ 1233 EngWtrInFlIO "Engine Water In Fuel Indication On";
BA_ "SignalType" SG_ 1233 EngWtrInFlIO "BLN";
BA_ "VNSigAllNodes" SG_ 1233 EngWtrInFlIO 1;
BA_ "SignalLongName" SG_ 1233 EngOilTmpV "Engine Oil Temperature Validity";
BA_ "SignalType" SG_ 1233 EngOilTmpV "ENM";
BA_ "VNSigAllNodes" SG_ 1233 EngOilTmpV 1;
BA_ "SignalLongName" SG_ 1233 EngOilTmp "Engine Oil Temperature";
BA_ "SignalType" SG_ 1233 EngOilTmp "UNM";
BA_ "VNSigAllNodes" SG_ 1233 EngOilTmp 1;
BA_ "SignalLongName" SG_ 1233 EngOilPrsV "Engine Oil Pressure Validity";
BA_ "SignalType" SG_ 1233 EngOilPrsV "ENM";
BA_ "VNSigAllNodes" SG_ 1233 EngOilPrsV 1;
BA_ "SignalLongName" SG_ 1233 EngOilPrsLwIO "Engine Oil Pressure Low Indication On";
BA_ "SignalType" SG_ 1233 EngOilPrsLwIO "BLN";
BA_ "VNSigAllNodes" SG_ 1233 EngOilPrsLwIO 1;
BA_ "SignalLongName" SG_ 1233 EngOilPrs "Engine Oil Pressure";
BA_ "SignalType" SG_ 1233 EngOilPrs "UNM";
BA_ "VNSigAllNodes" SG_ 1233 EngOilPrs 1;
BA_ "SignalLongName" SG_ 1233 EngOilLvlLwIO "Engine Oil Level Low Indication On";
BA_ "SignalType" SG_ 1233 EngOilLvlLwIO "BLN";
BA_ "VNSigAllNodes" SG_ 1233 EngOilLvlLwIO 1;
BA_ "SignalLongName" SG_ 1233 EngOilChngIO "Engine Oil Change Indication On";
BA_ "SignalType" SG_ 1233 EngOilChngIO "BLN";
BA_ "VNSigAllNodes" SG_ 1233 EngOilChngIO 1;
BA_ "SignalLongName" SG_ 1233 EngHt_StpEngIO "Engine Hot / Stop Engine Indication On";
BA_ "SignalType" SG_ 1233 EngHt_StpEngIO "BLN";
BA_ "VNSigAllNodes" SG_ 1233 EngHt_StpEngIO 1;
BA_ "SignalLongName" SG_ 1233 EngHotFuelEnrchmntIO "Engine Hot Fuel Enrichment Indication On";
BA_ "SignalType" SG_ 1233 EngHotFuelEnrchmntIO "BLN";
BA_ "VNSigAllNodes" SG_ 1233 EngHotFuelEnrchmntIO 1;
BA_ "SignalLongName" SG_ 1233 CkFlFilrCapIO "Check Fuel Filler Cap Indication On";
BA_ "SignalType" SG_ 1233 CkFlFilrCapIO "BLN";
BA_ "VNSigAllNodes" SG_ 1233 CkFlFilrCapIO 1;
BA_ "SignalLongName" SG_ 1217 LDMinEngCltTmpRchd "Legislated Diagnostics Minimum Engine Coolant Temperature Reached";
BA_ "SignalType" SG_ 1217 LDMinEngCltTmpRchd "BLN";
BA_ "VNSigAllNodes" SG_ 1217 LDMinEngCltTmpRchd 1;
BA_ "SignalLongName" SG_ 1217 LegPstDTCClrDrvCyCm "Legislated Post DTC Clear Drive Cycle Complete";
BA_ "SignalType" SG_ 1217 LegPstDTCClrDrvCyCm "BLN";
BA_ "VNSigAllNodes" SG_ 1217 LegPstDTCClrDrvCyCm 1;
BA_ "SignalLongName" SG_ 1217 LegDiagColdStCndMet "Legislated Diagnostics Cold Start Conditions Met";
BA_ "SignalType" SG_ 1217 LegDiagColdStCndMet "BLN";
BA_ "VNSigAllNodes" SG_ 1217 LegDiagColdStCndMet 1;
BA_ "SignalLongName" SG_ 1217 LegDiagColdStCndFltPr "Legislated Diagnostics Cold Start Conditions Fault Present";
BA_ "SignalType" SG_ 1217 LegDiagColdStCndFltPr "BLN";
BA_ "VNSigAllNodes" SG_ 1217 LegDiagColdStCndFltPr 1;
BA_ "SignalLongName" SG_ 1217 EngEconMdCmnd "Engine Economy Mode Commanded";
BA_ "SignalType" SG_ 1217 EngEconMdCmnd "BLN";
BA_ "VNSigAllNodes" SG_ 1217 EngEconMdCmnd 1;
BA_ "SignalLongName" SG_ 1217 DslExhFldRmngDstHRsV "Diesel Exhaust Fluid Remaining Distance High Resolution Validity";
BA_ "SignalType" SG_ 1217 DslExhFldRmngDstHRsV "ENM";
BA_ "VNSigAllNodes" SG_ 1217 DslExhFldRmngDstHRsV 1;
BA_ "SignalLongName" SG_ 1217 DslExhFldRmngDstHRs "Diesel Exhaust Fluid Remaining Distance High Resolution";
BA_ "SignalType" SG_ 1217 DslExhFldRmngDstHRs "UNM";
BA_ "VNSigAllNodes" SG_ 1217 DslExhFldRmngDstHRs 1;
BA_ "SignalLongName" SG_ 1217 EngOilHotIO "Engine Oil Hot Indication On";
BA_ "SignalType" SG_ 1217 EngOilHotIO "BLN";
BA_ "VNSigAllNodes" SG_ 1217 EngOilHotIO 1;
BA_ "SignalLongName" SG_ 1217 OAT_PT_EstV "Outside Air Temperature Powertrain Estimated Validity";
BA_ "SignalType" SG_ 1217 OAT_PT_EstV "ENM";
BA_ "VNSigAllNodes" SG_ 1217 OAT_PT_EstV 1;
BA_ "SignalLongName" SG_ 1217 LegDiagStndCndMet "Legislated Diagnostics Standard Conditions Met";
BA_ "SignalType" SG_ 1217 LegDiagStndCndMet "BLN";
BA_ "VNSigAllNodes" SG_ 1217 LegDiagStndCndMet 1;
BA_ "SignalLongName" SG_ 1217 LegDiagStndCndFltPr "Legislated Diagnostics Standard Conditions Fault Present";
BA_ "SignalType" SG_ 1217 LegDiagStndCndFltPr "BLN";
BA_ "VNSigAllNodes" SG_ 1217 LegDiagStndCndFltPr 1;
BA_ "SignalLongName" SG_ 1217 OAT_PT_EstM "Outside Air Temperature Powertrain Estimated Mask";
BA_ "SignalType" SG_ 1217 OAT_PT_EstM "ENM";
BA_ "VNSigAllNodes" SG_ 1217 OAT_PT_EstM 1;
BA_ "SignalLongName" SG_ 1217 OAT_PT_Est "Outside Air Temperature Powertrain Estimated";
BA_ "SignalType" SG_ 1217 OAT_PT_Est "UNM";
BA_ "VNSigAllNodes" SG_ 1217 OAT_PT_Est 1;
BA_ "SignalLongName" SG_ 1217 EngWrmUpAch "Engine Warm Up Cycle Achieved";
BA_ "SignalType" SG_ 1217 EngWrmUpAch "BLN";
BA_ "VNSigAllNodes" SG_ 1217 EngWrmUpAch 1;
BA_ "SignalLongName" SG_ 1217 EngIntAirTmpV "Engine Intake Air Temperature Validity";
BA_ "SignalType" SG_ 1217 EngIntAirTmpV "ENM";
BA_ "VNSigAllNodes" SG_ 1217 EngIntAirTmpV 1;
BA_ "SignalLongName" SG_ 1217 EngIntAirTmp "Engine Intake Air Temperature";
BA_ "SignalType" SG_ 1217 EngIntAirTmp "UNM";
BA_ "VNSigAllNodes" SG_ 1217 EngIntAirTmp 1;
BA_ "SignalLongName" SG_ 1217 EngCltTmpV "Engine Coolant Temperature Validity";
BA_ "SignalType" SG_ 1217 EngCltTmpV "ENM";
BA_ "VNSigAllNodes" SG_ 1217 EngCltTmpV 1;
BA_ "GenSigSendOnInit" SG_ 1217 EngCltTmpV 1;
BA_ "SignalLongName" SG_ 1217 EngCltTmp "Engine Coolant Temperature";
BA_ "SignalType" SG_ 1217 EngCltTmp "UNM";
BA_ "VNSigAllNodes" SG_ 1217 EngCltTmp 1;
BA_ "GenSigSendOnInit" SG_ 1217 EngCltTmp 1;
BA_ "SignalLongName" SG_ 1217 BarPrsAbsV "Barometric Pressure Absolute Validity";
BA_ "SignalType" SG_ 1217 BarPrsAbsV "ENM";
BA_ "VNSigAllNodes" SG_ 1217 BarPrsAbsV 1;
BA_ "SignalLongName" SG_ 1217 BarPrsAbs "Barometric Pressure Absolute";
BA_ "SignalType" SG_ 1217 BarPrsAbs "UNM";
BA_ "VNSigAllNodes" SG_ 1217 BarPrsAbs 1;
BA_ "SignalLongName" SG_ 665 EngFuelCntlState_299 "Engine Fuel Control State";
BA_ "SignalType" SG_ 665 EngFuelCntlState_299 "ENM";
BA_ "VNSigAllNodes" SG_ 665 EngFuelCntlState_299 1;
BA_ "SignalLongName" SG_ 665 TotAltFClsLpCBn2LwRes "Total Alternative Fuel Closed Loop Correction Bank 2 Low Resolution";
BA_ "SignalType" SG_ 665 TotAltFClsLpCBn2LwRes "SNM";
BA_ "VNSigAllNodes" SG_ 665 TotAltFClsLpCBn2LwRes 1;
BA_ "SignalLongName" SG_ 665 TotAltFClsLpCBn1LwRes "Total Alternative Fuel Closed Loop Correction Bank 1 Low Resolution";
BA_ "SignalType" SG_ 665 TotAltFClsLpCBn1LwRes "SNM";
BA_ "VNSigAllNodes" SG_ 665 TotAltFClsLpCBn1LwRes 1;
BA_ "SignalLongName" SG_ 665 RelBsAltFuelMassLwRes "Relative Base Alternative Fuel Mass Low Resolution";
BA_ "SignalType" SG_ 665 RelBsAltFuelMassLwRes "UNM";
BA_ "VNSigAllNodes" SG_ 665 RelBsAltFuelMassLwRes 1;
BA_ "SignalLongName" SG_ 665 RdGasFuelDsblAct "Redundant Gaseous Fuel Disable Active";
BA_ "SignalType" SG_ 665 RdGasFuelDsblAct "BLN";
BA_ "VNSigAllNodes" SG_ 665 RdGasFuelDsblAct 1;
BA_ "SignalLongName" SG_ 665 RdDistFuelMdCmd "Redundant Distributed Fuel Mode Command";
BA_ "SignalType" SG_ 665 RdDistFuelMdCmd "ENM";
BA_ "VNSigAllNodes" SG_ 665 RdDistFuelMdCmd 1;
BA_ "SignalLongName" SG_ 665 PetrolFuelSysReqAval "Petrol Fuel System Request Availability";
BA_ "SignalType" SG_ 665 PetrolFuelSysReqAval "ENM";
BA_ "VNSigAllNodes" SG_ 665 PetrolFuelSysReqAval 1;
BA_ "SignalLongName" SG_ 665 AltFuelSysReqAlwd "Alternative Fuel System Request Allowed";
BA_ "SignalType" SG_ 665 AltFuelSysReqAlwd "BLN";
BA_ "VNSigAllNodes" SG_ 665 AltFuelSysReqAlwd 1;
BA_ "SignalLongName" SG_ 665 AltFuelInjHCmdLwRes "Alternative Fuel Injector H Command Low Resolution";
BA_ "SignalType" SG_ 665 AltFuelInjHCmdLwRes "ENM";
BA_ "VNSigAllNodes" SG_ 665 AltFuelInjHCmdLwRes 1;
BA_ "SignalLongName" SG_ 665 AltFuelInjGCmdLwRes "Alternative Fuel Injector G Command Low Resolution";
BA_ "SignalType" SG_ 665 AltFuelInjGCmdLwRes "ENM";
BA_ "VNSigAllNodes" SG_ 665 AltFuelInjGCmdLwRes 1;
BA_ "SignalLongName" SG_ 665 AltFuelInjFCmdLwRes "Alternative Fuel Injector F Command Low Resolution";
BA_ "SignalType" SG_ 665 AltFuelInjFCmdLwRes "ENM";
BA_ "VNSigAllNodes" SG_ 665 AltFuelInjFCmdLwRes 1;
BA_ "SignalLongName" SG_ 665 AltFuelInjECmdLwRes "Alternative Fuel Injector E Command Low Resolution";
BA_ "SignalType" SG_ 665 AltFuelInjECmdLwRes "ENM";
BA_ "VNSigAllNodes" SG_ 665 AltFuelInjECmdLwRes 1;
BA_ "SignalLongName" SG_ 665 AltFuelInjDCmdLwRes "Alternative Fuel Injector D Command Low Resolution";
BA_ "SignalType" SG_ 665 AltFuelInjDCmdLwRes "ENM";
BA_ "VNSigAllNodes" SG_ 665 AltFuelInjDCmdLwRes 1;
BA_ "SignalLongName" SG_ 665 AltFuelInjCCmdLwRes "Alternative Fuel Injector C Command Low Resolution";
BA_ "SignalType" SG_ 665 AltFuelInjCCmdLwRes "ENM";
BA_ "VNSigAllNodes" SG_ 665 AltFuelInjCCmdLwRes 1;
BA_ "SignalLongName" SG_ 665 AltFuelInjBCmdLwRes "Alternative Fuel Injector B Command Low Resolution";
BA_ "SignalType" SG_ 665 AltFuelInjBCmdLwRes "ENM";
BA_ "VNSigAllNodes" SG_ 665 AltFuelInjBCmdLwRes 1;
BA_ "SignalLongName" SG_ 665 AltFuelInjACmdLwRes "Alternative Fuel Injector A Command Low Resolution";
BA_ "SignalType" SG_ 665 AltFuelInjACmdLwRes "ENM";
BA_ "VNSigAllNodes" SG_ 665 AltFuelInjACmdLwRes 1;
BA_ "SignalLongName" SG_ 985 ManTransIndReq "Manual Transmission Indication Request";
BA_ "SignalType" SG_ 985 ManTransIndReq "ENM";
BA_ "VNSigAllNodes" SG_ 985 ManTransIndReq 1;
BA_ "GenSigSendType" SG_ 985 ManTransIndReq 10;
BA_ "SignalLongName" SG_ 985 DrvEffInd "Drive Efficiency Indication";
BA_ "SignalType" SG_ 985 DrvEffInd "SNM";
BA_ "VNSigAllNodes" SG_ 985 DrvEffInd 1;
BA_ "SignalLongName" SG_ 985 EngIntkArBstPrExtRng "Engine Intake Air Boost Pressure Extended Range";
BA_ "SignalType" SG_ 985 EngIntkArBstPrExtRng "UNM";
BA_ "VNSigAllNodes" SG_ 985 EngIntkArBstPrExtRng 1;
BA_ "SignalLongName" SG_ 985 EngIntkArBstPrExtRngV "Engine Intake Air Boost Pressure Extended Range Validity";
BA_ "SignalType" SG_ 985 EngIntkArBstPrExtRngV "ENM";
BA_ "VNSigAllNodes" SG_ 985 EngIntkArBstPrExtRngV 1;
BA_ "SignalLongName" SG_ 985 EDADS_RcmndtFwdGr "ECO Drive Assist Display Status : Recommended Forward Gear";
BA_ "PacketOrder" SG_ 985 EDADS_RcmndtFwdGr 4;
BA_ "SignalType" SG_ 985 EDADS_RcmndtFwdGr "ENM";
BA_ "VNSigAllNodes" SG_ 985 EDADS_RcmndtFwdGr 1;
BA_ "GenSigSendType" SG_ 985 EDADS_RcmndtFwdGr 10;
BA_ "SignalLongName" SG_ 985 EDADS_CrntFwdMsdG "ECO Drive Assist Display Status : Current Forward Measured Gear";
BA_ "PacketOrder" SG_ 985 EDADS_CrntFwdMsdG 3;
BA_ "SignalType" SG_ 985 EDADS_CrntFwdMsdG "ENM";
BA_ "VNSigAllNodes" SG_ 985 EDADS_CrntFwdMsdG 1;
BA_ "GenSigSendType" SG_ 985 EDADS_CrntFwdMsdG 10;
BA_ "SignalLongName" SG_ 985 EDADS_ShftIndStat "ECO Drive Assist Display Status : Shift Indication Status";
BA_ "PacketOrder" SG_ 985 EDADS_ShftIndStat 2;
BA_ "SignalType" SG_ 985 EDADS_ShftIndStat "ENM";
BA_ "VNSigAllNodes" SG_ 985 EDADS_ShftIndStat 1;
BA_ "GenSigSendType" SG_ 985 EDADS_ShftIndStat 10;
BA_ "SignalLongName" SG_ 985 EDADS_EcoDrvShftIO "ECO Drive Assist Display Status : ECO Drive Assist Shift Indication On";
BA_ "PacketOrder" SG_ 985 EDADS_EcoDrvShftIO 1;
BA_ "SignalType" SG_ 985 EDADS_EcoDrvShftIO "BLN";
BA_ "VNSigAllNodes" SG_ 985 EDADS_EcoDrvShftIO 1;
BA_ "GenSigSendType" SG_ 985 EDADS_EcoDrvShftIO 10;
BA_ "SignalLongName" SG_ 1017 ACRfHiSdFldPrsV "Air Conditioning Refrigerant High Side Fluid Pressure Validity";
BA_ "SignalType" SG_ 1017 ACRfHiSdFldPrsV "ENM";
BA_ "VNSigAllNodes" SG_ 1017 ACRfHiSdFldPrsV 1;
BA_ "SignalLongName" SG_ 1017 ACRfHiSdFldPrs "Air Conditioning Refrigerant High Side Fluid Pressure";
BA_ "SignalType" SG_ 1017 ACRfHiSdFldPrs "UNM";
BA_ "VNSigAllNodes" SG_ 1017 ACRfHiSdFldPrs 1;
BA_ "SignalLongName" SG_ 1017 GenStptDtCycPtOvrAct "Generator Setpoint Duty Cycle Powertrain Override Active";
BA_ "SignalType" SG_ 1017 GenStptDtCycPtOvrAct "BLN";
BA_ "VNSigAllNodes" SG_ 1017 GenStptDtCycPtOvrAct 1;
BA_ "SignalLongName" SG_ 1017 VehTopSpdLmtMdAct "Vehicle Top Speed Limit Mode Active";
BA_ "SignalType" SG_ 1017 VehTopSpdLmtMdAct "BLN";
BA_ "VNSigAllNodes" SG_ 1017 VehTopSpdLmtMdAct 1;
BA_ "SignalLongName" SG_ 1017 VehTopSpdLmtArbVal "Vehicle Top Speed Limit Arbitrated Value";
BA_ "SignalType" SG_ 1017 VehTopSpdLmtArbVal "UNM";
BA_ "VNSigAllNodes" SG_ 1017 VehTopSpdLmtArbVal 1;
BA_ "SignalLongName" SG_ 1017 GenFldDutCycV "Generator Field Duty Cycle Validity";
BA_ "SignalType" SG_ 1017 GenFldDutCycV "ENM";
BA_ "VNSigAllNodes" SG_ 1017 GenFldDutCycV 1;
BA_ "SignalLongName" SG_ 1017 GenFldDutCyc "Generator Field Duty Cycle";
BA_ "SignalType" SG_ 1017 GenFldDutCyc "UNM";
BA_ "VNSigAllNodes" SG_ 1017 GenFldDutCyc 1;
BA_ "SignalLongName" SG_ 1017 GenFld "Generator Failed";
BA_ "SignalType" SG_ 1017 GenFld "BLN";
BA_ "VNSigAllNodes" SG_ 1017 GenFld 1;
BA_ "SignalLongName" SG_ 1017 FlInjRlCtRstOcc "Fuel Injected Rolling Count Reset Occurred";
BA_ "SignalType" SG_ 1017 FlInjRlCtRstOcc "BLN";
BA_ "VNSigAllNodes" SG_ 1017 FlInjRlCtRstOcc 1;
BA_ "SignalLongName" SG_ 1017 FlInjRlCt "Fuel Injected Rolling Count";
BA_ "SignalType" SG_ 1017 FlInjRlCt "UNM";
BA_ "VNSigAllNodes" SG_ 1017 FlInjRlCt 1;
BA_ "SignalLongName" SG_ 1017 EngSpdLmtnMdAct "Engine Speed Limitation Mode Active";
BA_ "SignalType" SG_ 1017 EngSpdLmtnMdAct "BLN";
BA_ "VNSigAllNodes" SG_ 1017 EngSpdLmtnMdAct 1;
BA_ "SignalLongName" SG_ 1017 EngOilRmnLf "Engine Oil Remaining Life";
BA_ "SignalType" SG_ 1017 EngOilRmnLf "UNM";
BA_ "VNSigAllNodes" SG_ 1017 EngOilRmnLf 1;
BA_ "SignalLongName" SG_ 1017 EngCoolFanSpd "Engine Cooling Fan Speed";
BA_ "SignalType" SG_ 1017 EngCoolFanSpd "UNM";
BA_ "VNSigAllNodes" SG_ 1017 EngCoolFanSpd 1;
BA_ "SignalLongName" SG_ 977 AutoMdSpdLmtStat "Auto Mode Speed Limit Status";
BA_ "SignalType" SG_ 977 AutoMdSpdLmtStat "ENM";
BA_ "VNSigAllNodes" SG_ 977 AutoMdSpdLmtStat 1;
BA_ "SignalLongName" SG_ 977 FuelFltLifRstPerf "Fuel Filter Life Reset Performed";
BA_ "SignalType" SG_ 977 FuelFltLifRstPerf "BLN";
BA_ "VNSigAllNodes" SG_ 977 FuelFltLifRstPerf 1;
BA_ "SignalLongName" SG_ 977 SpdLmtrSpdWrngAct "Speed Limiter/Speed Warning Active";
BA_ "SignalType" SG_ 977 SpdLmtrSpdWrngAct "BLN";
BA_ "VNSigAllNodes" SG_ 977 SpdLmtrSpdWrngAct 1;
BA_ "SignalLongName" SG_ 977 CrsCntlDrSelSpdAct "Cruise Control Driver Selected Speed Active";
BA_ "SignalType" SG_ 977 CrsCntlDrSelSpdAct "BLN";
BA_ "VNSigAllNodes" SG_ 977 CrsCntlDrSelSpdAct 1;
BA_ "SignalLongName" SG_ 977 ACCmpNrmLdGrdAld "Air Conditioning Compressor Normalized Load Gradient Allowed";
BA_ "SignalType" SG_ 977 ACCmpNrmLdGrdAld "UNM";
BA_ "VNSigAllNodes" SG_ 977 ACCmpNrmLdGrdAld 1;
BA_ "SignalLongName" SG_ 977 ACCompCmnd "Air Conditioning Compressor Command";
BA_ "SignalType" SG_ 977 ACCompCmnd "ENM";
BA_ "VNSigAllNodes" SG_ 977 ACCompCmnd 1;
BA_ "SignalLongName" SG_ 977 EngBstPrsIndV "Engine Boost Pressure Indication Validity";
BA_ "SignalType" SG_ 977 EngBstPrsIndV "ENM";
BA_ "VNSigAllNodes" SG_ 977 EngBstPrsIndV 1;
BA_ "SignalLongName" SG_ 977 EngBstPrsInd "Engine Boost Pressure Indication";
BA_ "SignalType" SG_ 977 EngBstPrsInd "UNM";
BA_ "VNSigAllNodes" SG_ 977 EngBstPrsInd 1;
BA_ "SignalLongName" SG_ 977 ThrPosV "Throttle Position Validity";
BA_ "SignalType" SG_ 977 ThrPosV "ENM";
BA_ "VNSigAllNodes" SG_ 977 ThrPosV 1;
BA_ "SignalLongName" SG_ 977 ThrPos "Throttle Position";
BA_ "SignalType" SG_ 977 ThrPos "UNM";
BA_ "VNSigAllNodes" SG_ 977 ThrPos 1;
BA_ "SignalLongName" SG_ 977 InstFuelConsmpRate "Instantaneous Fuel Consumption Rate";
BA_ "SignalType" SG_ 977 InstFuelConsmpRate "UNM";
BA_ "VNSigAllNodes" SG_ 977 InstFuelConsmpRate 1;
BA_ "SignalLongName" SG_ 977 EngOilStrvtnIO "Engine Oil Starvation Indication On";
BA_ "SignalType" SG_ 977 EngOilStrvtnIO "BLN";
BA_ "VNSigAllNodes" SG_ 977 EngOilStrvtnIO 1;
BA_ "SignalLongName" SG_ 977 EngNEmsnsRelMalfAct "Engine Non Emissions Related Malfunction Active";
BA_ "SignalType" SG_ 977 EngNEmsnsRelMalfAct "BLN";
BA_ "VNSigAllNodes" SG_ 977 EngNEmsnsRelMalfAct 1;
BA_ "SignalLongName" SG_ 977 EngEmsRelMalfIndReq "Engine Emissions Related Malfunction Indication Request";
BA_ "SignalType" SG_ 977 EngEmsRelMalfIndReq "ENM";
BA_ "VNSigAllNodes" SG_ 977 EngEmsRelMalfIndReq 1;
BA_ "SignalLongName" SG_ 977 EngCstFlCutAct "Engine Coast Fuel Cut Off Active";
BA_ "SignalType" SG_ 977 EngCstFlCutAct "BLN";
BA_ "VNSigAllNodes" SG_ 977 EngCstFlCutAct 1;
BA_ "SignalLongName" SG_ 977 CrsSpdLmtrDrvSelSpd "Cruise and Speed Limiter Driver Selected Speed";
BA_ "SignalType" SG_ 977 CrsSpdLmtrDrvSelSpd "UNM";
BA_ "VNSigAllNodes" SG_ 977 CrsSpdLmtrDrvSelSpd 1;
BA_ "SignalLongName" SG_ 201 Eng12vStrtrMtrCmmdOn "Engine 12 Volt Starter Motor Commanded On";
BA_ "SignalType" SG_ 201 Eng12vStrtrMtrCmmdOn "BLN";
BA_ "VNSigAllNodes" SG_ 201 Eng12vStrtrMtrCmmdOn 1;
BA_ "SignalLongName" SG_ 201 EngCntrlRunCrnkTrmSt "Engine Controller Run Crank Terminal Status";
BA_ "SignalType" SG_ 201 EngCntrlRunCrnkTrmSt "ENM";
BA_ "VNSigAllNodes" SG_ 201 EngCntrlRunCrnkTrmSt 1;
BA_ "SignalLongName" SG_ 201 EngAirIntBstPrV "Engine Intake Air Boost Pressure Validity";
BA_ "SignalType" SG_ 201 EngAirIntBstPrV "ENM";
BA_ "VNSigAllNodes" SG_ 201 EngAirIntBstPrV 1;
BA_ "SignalLongName" SG_ 201 EngAirIntBstPr "Engine Intake Air Boost Pressure";
BA_ "SignalType" SG_ 201 EngAirIntBstPr "SNM";
BA_ "VNSigAllNodes" SG_ 201 EngAirIntBstPr 1;
BA_ "SignalLongName" SG_ 201 SpdLmtrSpdWrngEnbld "Speed Limiter/Speed Warning Enabled";
BA_ "SignalType" SG_ 201 SpdLmtrSpdWrngEnbld "BLN";
BA_ "VNSigAllNodes" SG_ 201 SpdLmtrSpdWrngEnbld 1;
BA_ "SignalLongName" SG_ 201 EngCylDactEvntPndg "Engine Cylinder Deactivation Event Pending";
BA_ "SignalType" SG_ 201 EngCylDactEvntPndg "BLN";
BA_ "VNSigAllNodes" SG_ 201 EngCylDactEvntPndg 1;
BA_ "SignalLongName" SG_ 201 EngCylDeactMd "Engine Cylinder Deactivation Mode";
BA_ "SignalType" SG_ 201 EngCylDeactMd "ENM";
BA_ "VNSigAllNodes" SG_ 201 EngCylDeactMd 1;
BA_ "SignalLongName" SG_ 201 RmVhStrtEngRng "Remote Vehicle Start Engine Running";
BA_ "SignalType" SG_ 201 RmVhStrtEngRng "BLN";
BA_ "VNSigAllNodes" SG_ 201 RmVhStrtEngRng 1;
BA_ "SignalLongName" SG_ 201 PFEngSpdCmndSpcd "Platform Engine Speed Command Superceded";
BA_ "SignalType" SG_ 201 PFEngSpdCmndSpcd "BLN";
BA_ "VNSigAllNodes" SG_ 201 PFEngSpdCmndSpcd 1;
BA_ "SignalLongName" SG_ 201 DrThrtlOvrrdDetProtVal "Driver Throttle Override Detected Protection Value";
BA_ "SignalType" SG_ 201 DrThrtlOvrrdDetProtVal "UNM";
BA_ "VNSigAllNodes" SG_ 201 DrThrtlOvrrdDetProtVal 1;
BA_ "SignalLongName" SG_ 201 DrThrtlOvrdDetAlvRlCnt "Driver Throttle Override Detection Alive Rolling Count";
BA_ "SignalType" SG_ 201 DrThrtlOvrdDetAlvRlCnt "UNM";
BA_ "VNSigAllNodes" SG_ 201 DrThrtlOvrdDetAlvRlCnt 1;
BA_ "SignalLongName" SG_ 201 PltfrmEngSpdCmdInhtRq "Platform Engine Speed Command Inhibit Request";
BA_ "SignalType" SG_ 201 PltfrmEngSpdCmdInhtRq "ENM";
BA_ "VNSigAllNodes" SG_ 201 PltfrmEngSpdCmdInhtRq 1;
BA_ "SignalLongName" SG_ 201 PT_BrkPedDscrtInpStatV "Powertrain Brake Pedal Discrete Input Status Validity";
BA_ "SignalType" SG_ 201 PT_BrkPedDscrtInpStatV "ENM";
BA_ "VNSigAllNodes" SG_ 201 PT_BrkPedDscrtInpStatV 1;
BA_ "SignalLongName" SG_ 201 PT_BrkPedDscrtInpStat "Powertrain Brake Pedal Discrete Input Status";
BA_ "SignalType" SG_ 201 PT_BrkPedDscrtInpStat "ENM";
BA_ "VNSigAllNodes" SG_ 201 PT_BrkPedDscrtInpStat 1;
BA_ "SignalLongName" SG_ 201 AccActPos "Accelerator Actual Position";
BA_ "SignalType" SG_ 201 AccActPos "UNM";
BA_ "VNSigAllNodes" SG_ 201 AccActPos 1;
BA_ "SignalLongName" SG_ 201 CrsCntEnbld "Cruise Control Enabled";
BA_ "SignalType" SG_ 201 CrsCntEnbld "BLN";
BA_ "VNSigAllNodes" SG_ 201 CrsCntEnbld 1;
BA_ "GenSigSendOnInit" SG_ 201 CrsCntEnbld 1;
BA_ "SignalLongName" SG_ 201 CrsCntAtv "Cruise Control Active";
BA_ "SignalType" SG_ 201 CrsCntAtv "BLN";
BA_ "VNSigAllNodes" SG_ 201 CrsCntAtv 1;
BA_ "GenSigSendType" SG_ 201 CrsCntAtv 10;
BA_ "GenSigSendOnInit" SG_ 201 CrsCntAtv 2;
BA_ "SignalLongName" SG_ 201 DrvThrottlOvrrdDet "Driver Throttle Override Detected";
BA_ "SignalType" SG_ 201 DrvThrottlOvrrdDet "BLN";
BA_ "VNSigAllNodes" SG_ 201 DrvThrottlOvrrdDet 1;
BA_ "SignalLongName" SG_ 201 PT_CrnkAct "Powertrain Crank Active";
BA_ "SignalType" SG_ 201 PT_CrnkAct "BLN";
BA_ "VNSigAllNodes" SG_ 201 PT_CrnkAct 1;
BA_ "SignalLongName" SG_ 201 PTRunAbrt "Powertrain Run Aborted";
BA_ "SignalType" SG_ 201 PTRunAbrt "BLN";
BA_ "VNSigAllNodes" SG_ 201 PTRunAbrt 1;
BA_ "SignalLongName" SG_ 201 PTO_PT_RunAbrtd "Power Take Off Powertrain Run Aborted";
BA_ "SignalType" SG_ 201 PTO_PT_RunAbrtd "BLN";
BA_ "VNSigAllNodes" SG_ 201 PTO_PT_RunAbrtd 1;
BA_ "SignalLongName" SG_ 201 PTCrnkAbrted "Powertrain Crank Aborted";
BA_ "SignalType" SG_ 201 PTCrnkAbrted "BLN";
BA_ "VNSigAllNodes" SG_ 201 PTCrnkAbrted 1;
BA_ "SignalLongName" SG_ 201 EngSpdStat "Engine Speed Status";
BA_ "SignalType" SG_ 201 EngSpdStat "ENM";
BA_ "VNSigAllNodes" SG_ 201 EngSpdStat 1;
BA_ "SignalLongName" SG_ 201 EngSpd "Engine Speed";
BA_ "SignalType" SG_ 201 EngSpd "UNM";
BA_ "VNSigAllNodes" SG_ 201 EngSpd 1;
BA_ "SignalLongName" SG_ 201 EngRunAtv "Engine Run Active";
BA_ "SignalType" SG_ 201 EngRunAtv "BLN";
BA_ "VNSigAllNodes" SG_ 201 EngRunAtv 1;
BA_ "SignalLongName" SG_ 201 EngIdlAtv "Engine Idle Active";
BA_ "SignalType" SG_ 201 EngIdlAtv "BLN";
BA_ "VNSigAllNodes" SG_ 201 EngIdlAtv 1;
BA_ "SignalLongName" SG_ 201 AccActPosV "Accelerator Actual Position Validity";
BA_ "SignalType" SG_ 201 AccActPosV "ENM";
BA_ "VNSigAllNodes" SG_ 201 AccActPosV 1;
BA_ "SignalLongName" SG_ 501 TmpDrvrShftCtlAct "Temporary Driver Shift Control Active";
BA_ "SignalType" SG_ 501 TmpDrvrShftCtlAct "BLN";
BA_ "VNSigAllNodes" SG_ 501 TmpDrvrShftCtlAct 1;
BA_ "SignalLongName" SG_ 501 EngRecDwnshftIO "Engine Recommended Downshift Indication On";
BA_ "SignalType" SG_ 501 EngRecDwnshftIO "BLN";
BA_ "VNSigAllNodes" SG_ 501 EngRecDwnshftIO 1;
BA_ "SignalLongName" SG_ 501 TrnsPattSelEcnMdOCm "Transmission Pattern Selection Economy Mode Override Commanded";
BA_ "SignalType" SG_ 501 TrnsPattSelEcnMdOCm "BLN";
BA_ "VNSigAllNodes" SG_ 501 TrnsPattSelEcnMdOCm 1;
BA_ "SignalLongName" SG_ 501 CltStartSwAtvV "Clutch Start Switch Active Validity";
BA_ "SignalType" SG_ 501 CltStartSwAtvV "ENM";
BA_ "VNSigAllNodes" SG_ 501 CltStartSwAtvV 1;
BA_ "GenSigStartValue" SG_ 501 CltStartSwAtv 1;
BA_ "SignalLongName" SG_ 501 CltStartSwAtv "Clutch Start Switch Active";
BA_ "SignalType" SG_ 501 CltStartSwAtv "BLN";
BA_ "VNSigAllNodes" SG_ 501 CltStartSwAtv 1;
BA_ "SignalLongName" SG_ 501 CltchPdlActPosV "Clutch Pedal Actual Position Validity";
BA_ "SignalType" SG_ 501 CltchPdlActPosV "ENM";
BA_ "VNSigAllNodes" SG_ 501 CltchPdlActPosV 1;
BA_ "SignalLongName" SG_ 501 CltchPdlActPos "Clutch Pedal Actual Position";
BA_ "SignalType" SG_ 501 CltchPdlActPos "UNM";
BA_ "VNSigAllNodes" SG_ 501 CltchPdlActPos 1;
BA_ "SignalLongName" SG_ 501 TrnsEngdStateV "Transmission Engaged State Validity";
BA_ "SignalType" SG_ 501 TrnsEngdStateV "ENM";
BA_ "VNSigAllNodes" SG_ 501 TrnsEngdStateV 1;
BA_ "SignalLongName" SG_ 501 TrnsEngdState "Transmission Engaged State";
BA_ "SignalType" SG_ 501 TrnsEngdState "ENM";
BA_ "VNSigAllNodes" SG_ 501 TrnsEngdState 1;
BA_ "SignalLongName" SG_ 501 TrnsShftLvrLckRqd "Transmission Shift Lever Lock Requested";
BA_ "SignalType" SG_ 501 TrnsShftLvrLckRqd "BLN";
BA_ "VNSigAllNodes" SG_ 501 TrnsShftLvrLckRqd 1;
BA_ "SignalLongName" SG_ 501 TransTUDMdStat "Transmission Tap Up/Tap Down Mode Status";
BA_ "SignalType" SG_ 501 TransTUDMdStat "ENM";
BA_ "VNSigAllNodes" SG_ 501 TransTUDMdStat 1;
BA_ "SignalLongName" SG_ 501 TrnCrpMdAtv "Transmission Creep Mode Active";
BA_ "SignalType" SG_ 501 TrnCrpMdAtv "BLN";
BA_ "VNSigAllNodes" SG_ 501 TrnCrpMdAtv 1;
BA_ "SignalLongName" SG_ 501 TrnsSkpShftIO "Transmission Skip Shift Indication On";
BA_ "SignalType" SG_ 501 TrnsSkpShftIO "BLN";
BA_ "VNSigAllNodes" SG_ 501 TrnsSkpShftIO 1;
BA_ "SignalLongName" SG_ 501 TrnsSftMdStat "Transmission Shift Mode Status";
BA_ "SignalType" SG_ 501 TrnsSftMdStat "ENM";
BA_ "VNSigAllNodes" SG_ 501 TrnsSftMdStat 1;
BA_ "SignalLongName" SG_ 501 TrnsRngInhbtStat "Transmission Range Inhibit Status";
BA_ "SignalType" SG_ 501 TrnsRngInhbtStat "ENM";
BA_ "VNSigAllNodes" SG_ 501 TrnsRngInhbtStat 1;
BA_ "SignalLongName" SG_ 501 TopTrvlCltchSwActV "Top of Travel Clutch Switch Active Validity";
BA_ "SignalType" SG_ 501 TopTrvlCltchSwActV "ENM";
BA_ "VNSigAllNodes" SG_ 501 TopTrvlCltchSwActV 1;
BA_ "SignalLongName" SG_ 501 TopTrvlCltchSwAct "Top of Travel Clutch Switch Active";
BA_ "SignalType" SG_ 501 TopTrvlCltchSwAct "BLN";
BA_ "VNSigAllNodes" SG_ 501 TopTrvlCltchSwAct 1;
BA_ "SignalLongName" SG_ 501 EngRecmndUpshftIO "Engine Recommended Upshift Indication On";
BA_ "SignalType" SG_ 501 EngRecmndUpshftIO "BLN";
BA_ "VNSigAllNodes" SG_ 501 EngRecmndUpshftIO 1;
BA_ "SignalLongName" SG_ 501 DrvtShftCntrlTrgtGear "Driver Shift Control Target Gear";
BA_ "SignalType" SG_ 501 DrvtShftCntrlTrgtGear "ENM";
BA_ "VNSigAllNodes" SG_ 501 DrvtShftCntrlTrgtGear 1;
BA_ "SignalLongName" SG_ 501 DrShftCntrlReqDndIO "Driver Shift Control Request Denied Indication On";
BA_ "SignalType" SG_ 501 DrShftCntrlReqDndIO "BLN";
BA_ "VNSigAllNodes" SG_ 501 DrShftCntrlReqDndIO 1;
BA_ "SignalLongName" SG_ 501 TrnShftPtrnActStat "Transmission Shift Pattern Active Status";
BA_ "SignalType" SG_ 501 TrnShftPtrnActStat "ENM";
BA_ "VNSigAllNodes" SG_ 501 TrnShftPtrnActStat 1;
BA_ "SignalLongName" SG_ 501 TrnsFldPrsPrsnt "Transmission Fluid Pressure Present";
BA_ "SignalType" SG_ 501 TrnsFldPrsPrsnt "BLN";
BA_ "VNSigAllNodes" SG_ 501 TrnsFldPrsPrsnt 1;
BA_ "SignalLongName" SG_ 501 TrnsShftLvrPos "Transmission Shift Lever Position";
BA_ "SignalType" SG_ 501 TrnsShftLvrPos "ENM";
BA_ "VNSigAllNodes" SG_ 501 TrnsShftLvrPos 1;
BA_ "SignalLongName" SG_ 501 TrnsShftLvrPosV "Transmission Shift Lever Position Validity";
BA_ "SignalType" SG_ 501 TrnsShftLvrPosV "ENM";
BA_ "VNSigAllNodes" SG_ 501 TrnsShftLvrPosV 1;
BA_ "GenSigStartValue" SG_ 501 TrnsTrqCnvCltCmndMd 7;
BA_ "SignalLongName" SG_ 501 TrnsTrqCnvCltCmndMd "Transmission Torque Converter Clutch Commanded Mode";
BA_ "SignalType" SG_ 501 TrnsTrqCnvCltCmndMd "ENM";
BA_ "VNSigAllNodes" SG_ 501 TrnsTrqCnvCltCmndMd 1;
BA_ "GenSigStartValue" SG_ 501 AutoTransComndGear 15;
BA_ "SignalLongName" SG_ 501 AutoTransComndGear "Automatic Transmission Commanded Gear";
BA_ "SignalType" SG_ 501 AutoTransComndGear "ENM";
BA_ "VNSigAllNodes" SG_ 501 AutoTransComndGear 1;
BA_ "SignalLongName" SG_ 501 AutoTransGrSftDirect "Automatic Transmission Gear Shift Direction";
BA_ "SignalType" SG_ 501 AutoTransGrSftDirect "ENM";
BA_ "VNSigAllNodes" SG_ 501 AutoTransGrSftDirect 1;
BA_ "GenSigStartValue" SG_ 501 TransEstGear 15;
BA_ "SignalLongName" SG_ 501 TransEstGear "Transmission Estimated Gear";
BA_ "SignalType" SG_ 501 TransEstGear "ENM";
BA_ "VNSigAllNodes" SG_ 501 TransEstGear 1;
BA_ "SignalLongName" SG_ 501 TransEstGearV "Transmission Estimated Gear Validity";
BA_ "SignalType" SG_ 501 TransEstGearV "ENM";
BA_ "VNSigAllNodes" SG_ 501 TransEstGearV 1;
BA_ "SignalLongName" SG_ 1225 TCTPIR_TnsEsClCDwT "Transmission Clutch Thermal Protection Indication Request : Transmission Estimated Clutch Cool-down Temperature Target Display";
BA_ "PacketOrder" SG_ 1225 TCTPIR_TnsEsClCDwT 3;
BA_ "SignalType" SG_ 1225 TCTPIR_TnsEsClCDwT "UNM";
BA_ "VNSigAllNodes" SG_ 1225 TCTPIR_TnsEsClCDwT 1;
BA_ "SignalLongName" SG_ 1225 TCTPIR_TnsEsClTmpD "Transmission Clutch Thermal Protection Indication Request : Transmission Estimated Clutch Temperature Display";
BA_ "PacketOrder" SG_ 1225 TCTPIR_TnsEsClTmpD 2;
BA_ "SignalType" SG_ 1225 TCTPIR_TnsEsClTmpD "UNM";
BA_ "VNSigAllNodes" SG_ 1225 TCTPIR_TnsEsClTmpD 1;
BA_ "SignalLongName" SG_ 1225 TCTPIR_DrvNotfn "Transmission Clutch Thermal Protection Indication Request : Driver Notification";
BA_ "PacketOrder" SG_ 1225 TCTPIR_DrvNotfn 1;
BA_ "SignalType" SG_ 1225 TCTPIR_DrvNotfn "ENM";
BA_ "VNSigAllNodes" SG_ 1225 TCTPIR_DrvNotfn 1;
BA_ "SignalLongName" SG_ 1225 GrdBrkgAct "Grade Braking Active";
BA_ "SignalType" SG_ 1225 GrdBrkgAct "BLN";
BA_ "VNSigAllNodes" SG_ 1225 GrdBrkgAct 1;
BA_ "SignalLongName" SG_ 1225 RrPTCoolFanRatFltStat "Rear Powertrain Cooling Fan Rationality Fault Status";
BA_ "SignalType" SG_ 1225 RrPTCoolFanRatFltStat "ENM";
BA_ "VNSigAllNodes" SG_ 1225 RrPTCoolFanRatFltStat 1;
BA_ "SignalLongName" SG_ 1225 TrnsThrmlMngmntStat "Transmission Thermal Management Status";
BA_ "SignalType" SG_ 1225 TrnsThrmlMngmntStat "ENM";
BA_ "VNSigAllNodes" SG_ 1225 TrnsThrmlMngmntStat 1;
BA_ "SignalLongName" SG_ 1225 TrnsNEmsRltMalfActv "Transmission Non Emissions Related Malfunction Active";
BA_ "SignalType" SG_ 1225 TrnsNEmsRltMalfActv "BLN";
BA_ "VNSigAllNodes" SG_ 1225 TrnsNEmsRltMalfActv 1;
BA_ "SignalLongName" SG_ 1225 TransOilTempSensPres "Transmission Oil Temperature Sensor Present";
BA_ "SignalType" SG_ 1225 TransOilTempSensPres "BLN";
BA_ "VNSigAllNodes" SG_ 1225 TransOilTempSensPres 1;
BA_ "SignalLongName" SG_ 1225 TrnEmsMlfAtv "Transmission Emissions Related Malfunction Active";
BA_ "SignalType" SG_ 1225 TrnEmsMlfAtv "BLN";
BA_ "VNSigAllNodes" SG_ 1225 TrnEmsMlfAtv 1;
BA_ "SignalLongName" SG_ 1225 TrnOilTmp "Transmission Oil Temperature";
BA_ "SignalType" SG_ 1225 TrnOilTmp "UNM";
BA_ "VNSigAllNodes" SG_ 1225 TrnOilTmp 1;
BA_ "SignalLongName" SG_ 1225 TrnOilTmpV "Transmission Oil Temperature Validity";
BA_ "SignalType" SG_ 1225 TrnOilTmpV "ENM";
BA_ "VNSigAllNodes" SG_ 1225 TrnOilTmpV 1;
BA_ "SignalLongName" SG_ 1225 TERDTC_SysDes "Transmission Emissions Related DTC : System Designator";
BA_ "PacketOrder" SG_ 1225 TERDTC_SysDes 1;
BA_ "SignalType" SG_ 1225 TERDTC_SysDes "ENM";
BA_ "VNSigAllNodes" SG_ 1225 TERDTC_SysDes 1;
BA_ "SignalLongName" SG_ 1225 TERDTC_CdNum "Transmission Emissions Related DTC : Code Number";
BA_ "PacketOrder" SG_ 1225 TERDTC_CdNum 2;
BA_ "SignalType" SG_ 1225 TERDTC_CdNum "UNM";
BA_ "VNSigAllNodes" SG_ 1225 TERDTC_CdNum 1;
BA_ "SignalLongName" SG_ 249 TrnsRqHSABrkPrDcyRt "Transmission Requested Hill Start Assist Brake Pressure Decay Rate";
BA_ "SignalType" SG_ 249 TrnsRqHSABrkPrDcyRt "ENM";
BA_ "VNSigAllNodes" SG_ 249 TrnsRqHSABrkPrDcyRt 1;
BA_ "SignalLongName" SG_ 249 TrnsDrvlneTqShpDisRq "Transmission Driveline Torque Shaping Disable Requested";
BA_ "SignalType" SG_ 249 TrnsDrvlneTqShpDisRq "BLN";
BA_ "VNSigAllNodes" SG_ 249 TrnsDrvlneTqShpDisRq 1;
BA_ "SignalLongName" SG_ 249 TnCCVehSpShftEvTh "Transmission Cruise Control Vehicle Speed Shift Event Threshold";
BA_ "SignalType" SG_ 249 TnCCVehSpShftEvTh "UNM";
BA_ "VNSigAllNodes" SG_ 249 TnCCVehSpShftEvTh 1;
BA_ "SignalLongName" SG_ 249 TrnsOtptRotRC "Transmission Output Rotations Rolling Count";
BA_ "SignalType" SG_ 249 TrnsOtptRotRC "UNM";
BA_ "VNSigAllNodes" SG_ 249 TrnsOtptRotRC 1;
BA_ "SignalLongName" SG_ 249 TrnsOtptRotRCRstOcc "Transmission Output Rotations Rolling Count Reset Occurred";
BA_ "SignalType" SG_ 249 TrnsOtptRotRCRstOcc "BLN";
BA_ "VNSigAllNodes" SG_ 249 TrnsOtptRotRCRstOcc 1;
BA_ "SignalLongName" SG_ 249 TrnsOtptRotRCV "Transmission Output Rotations Rolling Count Validity";
BA_ "SignalType" SG_ 249 TrnsOtptRotRCV "ENM";
BA_ "VNSigAllNodes" SG_ 249 TrnsOtptRotRCV 1;
BA_ "SignalLongName" SG_ 249 TrnsOtptShftAngVelSnrPr "Transmission Output Shaft Angular Velocity Sensor Present";
BA_ "SignalType" SG_ 249 TrnsOtptShftAngVelSnrPr "BLN";
BA_ "VNSigAllNodes" SG_ 249 TrnsOtptShftAngVelSnrPr 1;
BA_ "SignalLongName" SG_ 249 TrnsOutShftAngVel "Transmission Output Shaft Angular Velocity";
BA_ "SignalType" SG_ 249 TrnsOutShftAngVel "UNM";
BA_ "VNSigAllNodes" SG_ 249 TrnsOutShftAngVel 1;
BA_ "SignalLongName" SG_ 249 TrnsOutShftAngVelV "Transmission Output Shaft Angular Velocity Validity";
BA_ "SignalType" SG_ 249 TrnsOutShftAngVelV "ENM";
BA_ "VNSigAllNodes" SG_ 249 TrnsOutShftAngVelV 1;
BA_ "SignalLongName" SG_ 249 TrnsOvrallEstTorqRatio "Transmission Overall Estimated Torque Ratio";
BA_ "SignalType" SG_ 249 TrnsOvrallEstTorqRatio "SNM";
BA_ "VNSigAllNodes" SG_ 249 TrnsOvrallEstTorqRatio 1;
BA_ "SignalLongName" SG_ 249 TrnsOvrallEstTorqRatioV "Transmission Overall Estimated Torque Ratio Validity";
BA_ "SignalType" SG_ 249 TrnsOvrallEstTorqRatioV "ENM";
BA_ "VNSigAllNodes" SG_ 249 TrnsOvrallEstTorqRatioV 1;
BA_ "SignalLongName" SG_ 2024 DgnInf "Diagnostic Information";
BA_ "SignalType" SG_ 2024 DgnInf "UNM";
BA_ "VNSigAllNodes" SG_ 2024 DgnInf 1;
BA_ "VNSigSLHSSharedDiagnostic" SG_ 2024 DgnInf 1;
BA_ "SignalLongName" SG_ 1512 DgnInf "Diagnostic Information";
BA_ "SignalType" SG_ 1512 DgnInf "UNM";
BA_ "VNSigAllNodes" SG_ 1512 DgnInf 1;
BA_ "VNSigSLHSSharedDiagnostic" SG_ 1512 DgnInf 1;
BA_REL_ "GenSigTimeoutTime" BU_SG_REL_ BCM_HS SG_ 463 FourWhlDrvIndReq 250;
BA_REL_ "GenSigTimeoutMsg" BU_SG_REL_ BCM_HS SG_ 463 FourWhlDrvIndReq 463;
BA_REL_ "GenSigSuprvResp" BU_SG_REL_ BCM_HS SG_ 463 FourWhlDrvIndReq 1;
BA_REL_ "GenSigTimeoutTime" BU_SG_REL_ BCM_HS SG_ 463 TrnsfrCsRngShfSpdLmt 250;
BA_REL_ "GenSigTimeoutMsg" BU_SG_REL_ BCM_HS SG_ 463 TrnsfrCsRngShfSpdLmt 463;
BA_REL_ "GenSigSuprvResp" BU_SG_REL_ BCM_HS SG_ 463 TrnsfrCsRngShfSpdLmt 1;
BA_REL_ "GenSigTimeoutTime" BU_SG_REL_ BCM_HS SG_ 463 SecAxlNonEmMalfIO 250;
BA_REL_ "GenSigTimeoutMsg" BU_SG_REL_ BCM_HS SG_ 463 SecAxlNonEmMalfIO 463;
BA_REL_ "GenSigSuprvResp" BU_SG_REL_ BCM_HS SG_ 463 SecAxlNonEmMalfIO 1;
BA_REL_ "GenSigTimeoutTime" BU_SG_REL_ BCM_HS SG_ 463 SecAxlOperMod 250;
BA_REL_ "GenSigTimeoutMsg" BU_SG_REL_ BCM_HS SG_ 463 SecAxlOperMod 463;
BA_REL_ "GenSigSuprvResp" BU_SG_REL_ BCM_HS SG_ 463 SecAxlOperMod 1;
BA_REL_ "GenSigTimeoutTime" BU_SG_REL_ BCM_HS SG_ 1011 BatVltHiRes 625;
BA_REL_ "GenSigTimeoutMsg" BU_SG_REL_ BCM_HS SG_ 1011 BatVltHiRes 1011;
BA_REL_ "GenSigSuprvResp" BU_SG_REL_ BCM_HS SG_ 1011 BatVltHiRes 1;
BA_REL_ "GenSigTimeoutTime" BU_SG_REL_ BCM_HS SG_ 1011 BatCrntExtRng 625;
BA_REL_ "GenSigTimeoutMsg" BU_SG_REL_ BCM_HS SG_ 1011 BatCrntExtRng 1011;
BA_REL_ "GenSigSuprvResp" BU_SG_REL_ BCM_HS SG_ 1011 BatCrntExtRng 1;
BA_REL_ "GenSigTimeoutTime" BU_SG_REL_ BCM_HS SG_ 1011 BatSnsrlntFlt 625;
BA_REL_ "GenSigTimeoutMsg" BU_SG_REL_ BCM_HS SG_ 1011 BatSnsrlntFlt 1011;
BA_REL_ "GenSigSuprvResp" BU_SG_REL_ BCM_HS SG_ 1011 BatSnsrlntFlt 1;
BA_REL_ "GenSigTimeoutTime" BU_SG_REL_ BCM_HS SG_ 490 SrvcFlSysPrkInOpnArIO 250;
BA_REL_ "GenSigTimeoutMsg" BU_SG_REL_ BCM_HS SG_ 490 SrvcFlSysPrkInOpnArIO 490;
BA_REL_ "GenSigSuprvResp" BU_SG_REL_ BCM_HS SG_ 490 SrvcFlSysPrkInOpnArIO 1;
BA_REL_ "GenSigTimeoutTime" BU_SG_REL_ BCM_HS SG_ 490 FuelSysNEmsRltMalfAct 250;
BA_REL_ "GenSigTimeoutMsg" BU_SG_REL_ BCM_HS SG_ 490 FuelSysNEmsRltMalfAct 490;
BA_REL_ "GenSigSuprvResp" BU_SG_REL_ BCM_HS SG_ 490 FuelSysNEmsRltMalfAct 1;
BA_REL_ "GenSigTimeoutTime" BU_SG_REL_ BCM_HS SG_ 490 InActFuelMdFuelLvlIO 250;
BA_REL_ "GenSigTimeoutMsg" BU_SG_REL_ BCM_HS SG_ 490 InActFuelMdFuelLvlIO 490;
BA_REL_ "GenSigSuprvResp" BU_SG_REL_ BCM_HS SG_ 490 InActFuelMdFuelLvlIO 1;
BA_REL_ "GenSigTimeoutTime" BU_SG_REL_ CGM_HS SG_ 1267 VehMassNom 2500;
BA_REL_ "GenSigTimeoutMsg" BU_SG_REL_ CGM_HS SG_ 1267 VehMassNom 1267;
BA_REL_ "GenSigSuprvResp" BU_SG_REL_ CGM_HS SG_ 1267 VehMassNom 1;
BA_REL_ "GenSigTimeoutTime" BU_SG_REL_ CGM_HS SG_ 453 DrvIntndAxlTrqMin 250;
BA_REL_ "GenSigTimeoutMsg" BU_SG_REL_ CGM_HS SG_ 453 DrvIntndAxlTrqMin 453;
BA_REL_ "GenSigSuprvResp" BU_SG_REL_ CGM_HS SG_ 453 DrvIntndAxlTrqMin 1;
BA_REL_ "GenSigTimeoutTime" BU_SG_REL_ CGM_HS SG_ 453 DrvIntndAxlTrqMax 250;
BA_REL_ "GenSigTimeoutMsg" BU_SG_REL_ CGM_HS SG_ 453 DrvIntndAxlTrqMax 453;
BA_REL_ "GenSigSuprvResp" BU_SG_REL_ CGM_HS SG_ 453 DrvIntndAxlTrqMax 1;
BA_REL_ "GenSigTimeoutTime" BU_SG_REL_ CGM_HS SG_ 453 DrvIntndAxlTrq 250;
BA_REL_ "GenSigTimeoutMsg" BU_SG_REL_ CGM_HS SG_ 453 DrvIntndAxlTrq 453;
BA_REL_ "GenSigSuprvResp" BU_SG_REL_ CGM_HS SG_ 453 DrvIntndAxlTrq 1;
BA_REL_ "GenSigTimeoutTime" BU_SG_REL_ EBCM_OBD_HS SG_ 452 AutBrkAccActPsStRC 250;
BA_REL_ "GenSigTimeoutMsg" BU_SG_REL_ EBCM_OBD_HS SG_ 452 AutBrkAccActPsStRC 452;
BA_REL_ "GenSigSuprvResp" BU_SG_REL_ EBCM_OBD_HS SG_ 452 AutBrkAccActPsStRC 1;
BA_REL_ "GenSigTimeoutTime" BU_SG_REL_ EPB_HS SG_ 452 AutBrkAccActPsStRC 250;
BA_REL_ "GenSigTimeoutMsg" BU_SG_REL_ EPB_HS SG_ 452 AutBrkAccActPsStRC 452;
BA_REL_ "GenSigSuprvResp" BU_SG_REL_ EPB_HS SG_ 452 AutBrkAccActPsStRC 1;
BA_REL_ "GenSigTimeoutTime" BU_SG_REL_ EBCM_HS SG_ 452 AutBrkAccActPsStRC 250;
BA_REL_ "GenSigTimeoutMsg" BU_SG_REL_ EBCM_HS SG_ 452 AutBrkAccActPsStRC 452;
BA_REL_ "GenSigSuprvResp" BU_SG_REL_ EBCM_HS SG_ 452 AutBrkAccActPsStRC 1;
BA_REL_ "GenSigTimeoutTime" BU_SG_REL_ EBCM_OBD_HS SG_ 452 AutBrkAccActPsStPVal 250;
BA_REL_ "GenSigTimeoutMsg" BU_SG_REL_ EBCM_OBD_HS SG_ 452 AutBrkAccActPsStPVal 452;
BA_REL_ "GenSigSuprvResp" BU_SG_REL_ EBCM_OBD_HS SG_ 452 AutBrkAccActPsStPVal 1;
BA_REL_ "GenSigTimeoutTime" BU_SG_REL_ EPB_HS SG_ 452 AutBrkAccActPsStPVal 250;
BA_REL_ "GenSigTimeoutMsg" BU_SG_REL_ EPB_HS SG_ 452 AutBrkAccActPsStPVal 452;
BA_REL_ "GenSigSuprvResp" BU_SG_REL_ EPB_HS SG_ 452 AutBrkAccActPsStPVal 1;
BA_REL_ "GenSigTimeoutTime" BU_SG_REL_ EBCM_HS SG_ 452 AutBrkAccActPsStPVal 250;
BA_REL_ "GenSigTimeoutMsg" BU_SG_REL_ EBCM_HS SG_ 452 AutBrkAccActPsStPVal 452;
BA_REL_ "GenSigSuprvResp" BU_SG_REL_ EBCM_HS SG_ 452 AutBrkAccActPsStPVal 1;
BA_REL_ "GenSigTimeoutTime" BU_SG_REL_ EBCM_OBD_HS SG_ 452 ABAAPS_AccPos 250;
BA_REL_ "GenSigTimeoutMsg" BU_SG_REL_ EBCM_OBD_HS SG_ 452 ABAAPS_AccPos 452;
BA_REL_ "GenSigSuprvResp" BU_SG_REL_ EBCM_OBD_HS SG_ 452 ABAAPS_AccPos 1;
BA_REL_ "GenSigTimeoutTime" BU_SG_REL_ EPB_HS SG_ 452 ABAAPS_AccPos 250;
BA_REL_ "GenSigTimeoutMsg" BU_SG_REL_ EPB_HS SG_ 452 ABAAPS_AccPos 452;
BA_REL_ "GenSigSuprvResp" BU_SG_REL_ EPB_HS SG_ 452 ABAAPS_AccPos 1;
BA_REL_ "GenSigTimeoutTime" BU_SG_REL_ EBCM_HS SG_ 452 ABAAPS_AccPos 250;
BA_REL_ "GenSigTimeoutMsg" BU_SG_REL_ EBCM_HS SG_ 452 ABAAPS_AccPos 452;
BA_REL_ "GenSigSuprvResp" BU_SG_REL_ EBCM_HS SG_ 452 ABAAPS_AccPos 1;
BA_REL_ "GenSigTimeoutTime" BU_SG_REL_ EBCM_OBD_HS SG_ 452 ABAAPS_AccPosV 250;
BA_REL_ "GenSigTimeoutMsg" BU_SG_REL_ EBCM_OBD_HS SG_ 452 ABAAPS_AccPosV 452;
BA_REL_ "GenSigSuprvResp" BU_SG_REL_ EBCM_OBD_HS SG_ 452 ABAAPS_AccPosV 1;
BA_REL_ "GenSigTimeoutTime" BU_SG_REL_ EPB_HS SG_ 452 ABAAPS_AccPosV 250;
BA_REL_ "GenSigTimeoutMsg" BU_SG_REL_ EPB_HS SG_ 452 ABAAPS_AccPosV 452;
BA_REL_ "GenSigSuprvResp" BU_SG_REL_ EPB_HS SG_ 452 ABAAPS_AccPosV 1;
BA_REL_ "GenSigTimeoutTime" BU_SG_REL_ EBCM_HS SG_ 452 ABAAPS_AccPosV 250;
BA_REL_ "GenSigTimeoutMsg" BU_SG_REL_ EBCM_HS SG_ 452 ABAAPS_AccPosV 452;
BA_REL_ "GenSigSuprvResp" BU_SG_REL_ EBCM_HS SG_ 452 ABAAPS_AccPosV 1;
BA_REL_ "GenSigTimeoutTime" BU_SG_REL_ TCM_HS SG_ 190 EngSpdMaxCapRdcdRng 250;
BA_REL_ "GenSigTimeoutMsg" BU_SG_REL_ TCM_HS SG_ 190 EngSpdMaxCapRdcdRng 190;
BA_REL_ "GenSigSuprvResp" BU_SG_REL_ TCM_HS SG_ 190 EngSpdMaxCapRdcdRng 1;
BA_REL_ "GenSigTimeoutTime" BU_SG_REL_ ICCM_OBD_HS SG_ 190 PTSnsdBrkPdlInfPVal 250;
BA_REL_ "GenSigTimeoutMsg" BU_SG_REL_ ICCM_OBD_HS SG_ 190 PTSnsdBrkPdlInfPVal 190;
BA_REL_ "GenSigSuprvResp" BU_SG_REL_ ICCM_OBD_HS SG_ 190 PTSnsdBrkPdlInfPVal 1;
BA_REL_ "GenSigTimeoutTime" BU_SG_REL_ ICCM_HS SG_ 190 PTSnsdBrkPdlInfPVal 250;
BA_REL_ "GenSigTimeoutMsg" BU_SG_REL_ ICCM_HS SG_ 190 PTSnsdBrkPdlInfPVal 190;
BA_REL_ "GenSigSuprvResp" BU_SG_REL_ ICCM_HS SG_ 190 PTSnsdBrkPdlInfPVal 1;
BA_REL_ "GenSigTimeoutTime" BU_SG_REL_ TCM_HS SG_ 190 TrnsAuxPmpAct 250;
BA_REL_ "GenSigTimeoutMsg" BU_SG_REL_ TCM_HS SG_ 190 TrnsAuxPmpAct 190;
BA_REL_ "GenSigSuprvResp" BU_SG_REL_ TCM_HS SG_ 190 TrnsAuxPmpAct 1;
BA_REL_ "GenSigTimeoutTime" BU_SG_REL_ BCP_HS SG_ 190 AccPos 250;
BA_REL_ "GenSigTimeoutMsg" BU_SG_REL_ BCP_HS SG_ 190 AccPos 190;
BA_REL_ "GenSigSuprvResp" BU_SG_REL_ BCP_HS SG_ 190 AccPos 1;
BA_REL_ "GenSigTimeoutTime" BU_SG_REL_ TCCM_HS SG_ 190 AccPos 250;
BA_REL_ "GenSigTimeoutMsg" BU_SG_REL_ TCCM_HS SG_ 190 AccPos 190;
BA_REL_ "GenSigSuprvResp" BU_SG_REL_ TCCM_HS SG_ 190 AccPos 1;
BA_REL_ "GenSigTimeoutTime" BU_SG_REL_ TCM_HS SG_ 190 AccPos 250;
BA_REL_ "GenSigTimeoutMsg" BU_SG_REL_ TCM_HS SG_ 190 AccPos 190;
BA_REL_ "GenSigSuprvResp" BU_SG_REL_ TCM_HS SG_ 190 AccPos 1;
BA_REL_ "GenSigTimeoutTime" BU_SG_REL_ ICCM_OBD_HS SG_ 190 PTSnsdBrkPdlInfARC 250;
BA_REL_ "GenSigTimeoutMsg" BU_SG_REL_ ICCM_OBD_HS SG_ 190 PTSnsdBrkPdlInfARC 190;
BA_REL_ "GenSigSuprvResp" BU_SG_REL_ ICCM_OBD_HS SG_ 190 PTSnsdBrkPdlInfARC 1;
BA_REL_ "GenSigTimeoutTime" BU_SG_REL_ ICCM_HS SG_ 190 PTSnsdBrkPdlInfARC 250;
BA_REL_ "GenSigTimeoutMsg" BU_SG_REL_ ICCM_HS SG_ 190 PTSnsdBrkPdlInfARC 190;
BA_REL_ "GenSigSuprvResp" BU_SG_REL_ ICCM_HS SG_ 190 PTSnsdBrkPdlInfARC 1;
BA_REL_ "GenSigTimeoutTime" BU_SG_REL_ ICCM_OBD_HS SG_ 190 PSBPI_PTSnBrkPdlPsV 250;
BA_REL_ "GenSigTimeoutMsg" BU_SG_REL_ ICCM_OBD_HS SG_ 190 PSBPI_PTSnBrkPdlPsV 190;
BA_REL_ "GenSigSuprvResp" BU_SG_REL_ ICCM_OBD_HS SG_ 190 PSBPI_PTSnBrkPdlPsV 1;
BA_REL_ "GenSigTimeoutTime" BU_SG_REL_ EBCM_OBD_HS SG_ 190 PSBPI_PTSnBrkPdlPsV 250;
BA_REL_ "GenSigTimeoutMsg" BU_SG_REL_ EBCM_OBD_HS SG_ 190 PSBPI_PTSnBrkPdlPsV 190;
BA_REL_ "GenSigSuprvResp" BU_SG_REL_ EBCM_OBD_HS SG_ 190 PSBPI_PTSnBrkPdlPsV 1;
BA_REL_ "GenSigTimeoutTime" BU_SG_REL_ ICCM_HS SG_ 190 PSBPI_PTSnBrkPdlPsV 250;
BA_REL_ "GenSigTimeoutMsg" BU_SG_REL_ ICCM_HS SG_ 190 PSBPI_PTSnBrkPdlPsV 190;
BA_REL_ "GenSigSuprvResp" BU_SG_REL_ ICCM_HS SG_ 190 PSBPI_PTSnBrkPdlPsV 1;
BA_REL_ "GenSigTimeoutTime" BU_SG_REL_ EBCM_HS SG_ 190 PSBPI_PTSnBrkPdlPsV 250;
BA_REL_ "GenSigTimeoutMsg" BU_SG_REL_ EBCM_HS SG_ 190 PSBPI_PTSnBrkPdlPsV 190;
BA_REL_ "GenSigSuprvResp" BU_SG_REL_ EBCM_HS SG_ 190 PSBPI_PTSnBrkPdlPsV 1;
BA_REL_ "GenSigTimeoutTime" BU_SG_REL_ ICCM_OBD_HS SG_ 190 PSBPI_PTSnBrkPdlPs 250;
BA_REL_ "GenSigTimeoutMsg" BU_SG_REL_ ICCM_OBD_HS SG_ 190 PSBPI_PTSnBrkPdlPs 190;
BA_REL_ "GenSigSuprvResp" BU_SG_REL_ ICCM_OBD_HS SG_ 190 PSBPI_PTSnBrkPdlPs 1;
BA_REL_ "GenSigTimeoutTime" BU_SG_REL_ EBCM_OBD_HS SG_ 190 PSBPI_PTSnBrkPdlPs 250;
BA_REL_ "GenSigTimeoutMsg" BU_SG_REL_ EBCM_OBD_HS SG_ 190 PSBPI_PTSnBrkPdlPs 190;
BA_REL_ "GenSigSuprvResp" BU_SG_REL_ EBCM_OBD_HS SG_ 190 PSBPI_PTSnBrkPdlPs 1;
BA_REL_ "GenSigTimeoutTime" BU_SG_REL_ ICCM_HS SG_ 190 PSBPI_PTSnBrkPdlPs 250;
BA_REL_ "GenSigTimeoutMsg" BU_SG_REL_ ICCM_HS SG_ 190 PSBPI_PTSnBrkPdlPs 190;
BA_REL_ "GenSigSuprvResp" BU_SG_REL_ ICCM_HS SG_ 190 PSBPI_PTSnBrkPdlPs 1;
BA_REL_ "GenSigTimeoutTime" BU_SG_REL_ EBCM_HS SG_ 190 PSBPI_PTSnBrkPdlPs 250;
BA_REL_ "GenSigTimeoutMsg" BU_SG_REL_ EBCM_HS SG_ 190 PSBPI_PTSnBrkPdlPs 190;
BA_REL_ "GenSigSuprvResp" BU_SG_REL_ EBCM_HS SG_ 190 PSBPI_PTSnBrkPdlPs 1;
BA_REL_ "GenSigTimeoutTime" BU_SG_REL_ EBCM_OBD_HS SG_ 451 HillDscntCtrlSwStatPVal 250;
BA_REL_ "GenSigTimeoutMsg" BU_SG_REL_ EBCM_OBD_HS SG_ 451 HillDscntCtrlSwStatPVal 451;
BA_REL_ "GenSigSuprvResp" BU_SG_REL_ EBCM_OBD_HS SG_ 451 HillDscntCtrlSwStatPVal 1;
BA_REL_ "GenSigTimeoutTime" BU_SG_REL_ EBCM_HS SG_ 451 HillDscntCtrlSwStatPVal 250;
BA_REL_ "GenSigTimeoutMsg" BU_SG_REL_ EBCM_HS SG_ 451 HillDscntCtrlSwStatPVal 451;
BA_REL_ "GenSigSuprvResp" BU_SG_REL_ EBCM_HS SG_ 451 HillDscntCtrlSwStatPVal 1;
BA_REL_ "GenSigTimeoutTime" BU_SG_REL_ EBCM_OBD_HS SG_ 451 HillDscntCtrlSwStatARC 250;
BA_REL_ "GenSigTimeoutMsg" BU_SG_REL_ EBCM_OBD_HS SG_ 451 HillDscntCtrlSwStatARC 451;
BA_REL_ "GenSigSuprvResp" BU_SG_REL_ EBCM_OBD_HS SG_ 451 HillDscntCtrlSwStatARC 1;
BA_REL_ "GenSigTimeoutTime" BU_SG_REL_ EBCM_HS SG_ 451 HillDscntCtrlSwStatARC 250;
BA_REL_ "GenSigTimeoutMsg" BU_SG_REL_ EBCM_HS SG_ 451 HillDscntCtrlSwStatARC 451;
BA_REL_ "GenSigSuprvResp" BU_SG_REL_ EBCM_HS SG_ 451 HillDscntCtrlSwStatARC 1;
BA_REL_ "GenSigTimeoutTime" BU_SG_REL_ EBCM_OBD_HS SG_ 451 HillDscntCtrlSwStat 250;
BA_REL_ "GenSigTimeoutMsg" BU_SG_REL_ EBCM_OBD_HS SG_ 451 HillDscntCtrlSwStat 451;
BA_REL_ "GenSigSuprvResp" BU_SG_REL_ EBCM_OBD_HS SG_ 451 HillDscntCtrlSwStat 1;
BA_REL_ "GenSigTimeoutTime" BU_SG_REL_ EBCM_HS SG_ 451 HillDscntCtrlSwStat 250;
BA_REL_ "GenSigTimeoutMsg" BU_SG_REL_ EBCM_HS SG_ 451 HillDscntCtrlSwStat 451;
BA_REL_ "GenSigSuprvResp" BU_SG_REL_ EBCM_HS SG_ 451 HillDscntCtrlSwStat 1;
BA_REL_ "GenSigTimeoutTime" BU_SG_REL_ BCM_HS SG_ 451 GlwPlgCrnkDelAct 250;
BA_REL_ "GenSigTimeoutMsg" BU_SG_REL_ BCM_HS SG_ 451 GlwPlgCrnkDelAct 451;
BA_REL_ "GenSigSuprvResp" BU_SG_REL_ BCM_HS SG_ 451 GlwPlgCrnkDelAct 1;
BA_REL_ "GenSigTimeoutTime" BU_SG_REL_ ICCM_OBD_HS SG_ 451 AccPos 250;
BA_REL_ "GenSigTimeoutMsg" BU_SG_REL_ ICCM_OBD_HS SG_ 451 AccPos 451;
BA_REL_ "GenSigSuprvResp" BU_SG_REL_ ICCM_OBD_HS SG_ 451 AccPos 1;
BA_REL_ "GenSigTimeoutTime" BU_SG_REL_ ICCM_HS SG_ 451 AccPos 250;
BA_REL_ "GenSigTimeoutMsg" BU_SG_REL_ ICCM_HS SG_ 451 AccPos 451;
BA_REL_ "GenSigSuprvResp" BU_SG_REL_ ICCM_HS SG_ 451 AccPos 1;
BA_REL_ "GenSigTimeoutTime" BU_SG_REL_ TCCM_HS SG_ 451 AccPos 250;
BA_REL_ "GenSigTimeoutMsg" BU_SG_REL_ TCCM_HS SG_ 451 AccPos 451;
BA_REL_ "GenSigSuprvResp" BU_SG_REL_ TCCM_HS SG_ 451 AccPos 1;
BA_REL_ "GenSigTimeoutTime" BU_SG_REL_ BCM_HS SG_ 451 EngTrqDrRqdExtRng 250;
BA_REL_ "GenSigTimeoutMsg" BU_SG_REL_ BCM_HS SG_ 451 EngTrqDrRqdExtRng 451;
BA_REL_ "GenSigSuprvResp" BU_SG_REL_ BCM_HS SG_ 451 EngTrqDrRqdExtRng 1;
BA_REL_ "GenSigTimeoutTime" BU_SG_REL_ ICCM_OBD_HS SG_ 451 EngTrqActExtRng 250;
BA_REL_ "GenSigTimeoutMsg" BU_SG_REL_ ICCM_OBD_HS SG_ 451 EngTrqActExtRng 451;
BA_REL_ "GenSigSuprvResp" BU_SG_REL_ ICCM_OBD_HS SG_ 451 EngTrqActExtRng 1;
BA_REL_ "GenSigTimeoutTime" BU_SG_REL_ EBCM_OBD_HS SG_ 451 EngTrqActExtRng 63;
BA_REL_ "GenSigTimeoutMsg" BU_SG_REL_ EBCM_OBD_HS SG_ 451 EngTrqActExtRng 451;
BA_REL_ "GenSigSuprvResp" BU_SG_REL_ EBCM_OBD_HS SG_ 451 EngTrqActExtRng 1;
BA_REL_ "GenSigTimeoutTime" BU_SG_REL_ ICCM_HS SG_ 451 EngTrqActExtRng 250;
BA_REL_ "GenSigTimeoutMsg" BU_SG_REL_ ICCM_HS SG_ 451 EngTrqActExtRng 451;
BA_REL_ "GenSigSuprvResp" BU_SG_REL_ ICCM_HS SG_ 451 EngTrqActExtRng 1;
BA_REL_ "GenSigTimeoutTime" BU_SG_REL_ EPB_HS SG_ 451 EngTrqActExtRng 250;
BA_REL_ "GenSigTimeoutMsg" BU_SG_REL_ EPB_HS SG_ 451 EngTrqActExtRng 451;
BA_REL_ "GenSigSuprvResp" BU_SG_REL_ EPB_HS SG_ 451 EngTrqActExtRng 1;
BA_REL_ "GenSigTimeoutTime" BU_SG_REL_ EBCM_HS SG_ 451 EngTrqActExtRng 63;
BA_REL_ "GenSigTimeoutMsg" BU_SG_REL_ EBCM_HS SG_ 451 EngTrqActExtRng 451;
BA_REL_ "GenSigSuprvResp" BU_SG_REL_ EBCM_HS SG_ 451 EngTrqActExtRng 1;
BA_REL_ "GenSigTimeoutTime" BU_SG_REL_ BCM_HS SG_ 451 EngTrqActExtRng 250;
BA_REL_ "GenSigTimeoutMsg" BU_SG_REL_ BCM_HS SG_ 451 EngTrqActExtRng 451;
BA_REL_ "GenSigVBitResp" BU_SG_REL_ BCM_HS SG_ 451 EngTrqActExtRng 1;
BA_REL_ "GenSigSuprvResp" BU_SG_REL_ BCM_HS SG_ 451 EngTrqActExtRng 1;
BA_REL_ "GenSigTimeoutTime" BU_SG_REL_ EBCM_OBD_HS SG_ 1001 DistRollCntAvgDrvnSrc 250;
BA_REL_ "GenSigTimeoutMsg" BU_SG_REL_ EBCM_OBD_HS SG_ 1001 DistRollCntAvgDrvnSrc 1001;
BA_REL_ "GenSigSuprvResp" BU_SG_REL_ EBCM_OBD_HS SG_ 1001 DistRollCntAvgDrvnSrc 1;
BA_REL_ "GenSigTimeoutTime" BU_SG_REL_ BCP_HS SG_ 1001 DistRollCntAvgDrvnSrc 250;
BA_REL_ "GenSigTimeoutMsg" BU_SG_REL_ BCP_HS SG_ 1001 DistRollCntAvgDrvnSrc 1001;
BA_REL_ "GenSigSuprvResp" BU_SG_REL_ BCP_HS SG_ 1001 DistRollCntAvgDrvnSrc 1;
BA_REL_ "GenSigTimeoutTime" BU_SG_REL_ EBCM_HS SG_ 1001 DistRollCntAvgDrvnSrc 250;
BA_REL_ "GenSigTimeoutMsg" BU_SG_REL_ EBCM_HS SG_ 1001 DistRollCntAvgDrvnSrc 1001;
BA_REL_ "GenSigSuprvResp" BU_SG_REL_ EBCM_HS SG_ 1001 DistRollCntAvgDrvnSrc 1;
BA_REL_ "GenSigTimeoutTime" BU_SG_REL_ EBCM_OBD_HS SG_ 1001 VehSpdAvgDrvnSrc 250;
BA_REL_ "GenSigTimeoutMsg" BU_SG_REL_ EBCM_OBD_HS SG_ 1001 VehSpdAvgDrvnSrc 1001;
BA_REL_ "GenSigSuprvResp" BU_SG_REL_ EBCM_OBD_HS SG_ 1001 VehSpdAvgDrvnSrc 1;
BA_REL_ "GenSigTimeoutTime" BU_SG_REL_ EBCM_HS SG_ 1001 VehSpdAvgDrvnSrc 250;
BA_REL_ "GenSigTimeoutMsg" BU_SG_REL_ EBCM_HS SG_ 1001 VehSpdAvgDrvnSrc 1001;
BA_REL_ "GenSigSuprvResp" BU_SG_REL_ EBCM_HS SG_ 1001 VehSpdAvgDrvnSrc 1;
BA_REL_ "GenSigTimeoutTime" BU_SG_REL_ EBCM_OBD_HS SG_ 1001 DstRolCntAvNDrRstOc 250;
BA_REL_ "GenSigTimeoutMsg" BU_SG_REL_ EBCM_OBD_HS SG_ 1001 DstRolCntAvNDrRstOc 1001;
BA_REL_ "GenSigSuprvResp" BU_SG_REL_ EBCM_OBD_HS SG_ 1001 DstRolCntAvNDrRstOc 1;
BA_REL_ "GenSigTimeoutTime" BU_SG_REL_ EBCM_HS SG_ 1001 DstRolCntAvNDrRstOc 250;
BA_REL_ "GenSigTimeoutMsg" BU_SG_REL_ EBCM_HS SG_ 1001 DstRolCntAvNDrRstOc 1001;
BA_REL_ "GenSigSuprvResp" BU_SG_REL_ EBCM_HS SG_ 1001 DstRolCntAvNDrRstOc 1;
BA_REL_ "GenSigTimeoutTime" BU_SG_REL_ EBCM_OBD_HS SG_ 1001 DstRolCntAvgNonDrvn 250;
BA_REL_ "GenSigTimeoutMsg" BU_SG_REL_ EBCM_OBD_HS SG_ 1001 DstRolCntAvgNonDrvn 1001;
BA_REL_ "GenSigSuprvResp" BU_SG_REL_ EBCM_OBD_HS SG_ 1001 DstRolCntAvgNonDrvn 1;
BA_REL_ "GenSigTimeoutTime" BU_SG_REL_ EBCM_HS SG_ 1001 DstRolCntAvgNonDrvn 250;
BA_REL_ "GenSigTimeoutMsg" BU_SG_REL_ EBCM_HS SG_ 1001 DstRolCntAvgNonDrvn 1001;
BA_REL_ "GenSigSuprvResp" BU_SG_REL_ EBCM_HS SG_ 1001 DstRolCntAvgNonDrvn 1;
BA_REL_ "GenSigTimeoutTime" BU_SG_REL_ BCM_HS SG_ 1001 DstRolCntAvgNonDrvn 250;
BA_REL_ "GenSigTimeoutMsg" BU_SG_REL_ BCM_HS SG_ 1001 DstRolCntAvgNonDrvn 1001;
BA_REL_ "GenSigVBitResp" BU_SG_REL_ BCM_HS SG_ 1001 DstRolCntAvgNonDrvn 1;
BA_REL_ "GenSigSuprvResp" BU_SG_REL_ BCM_HS SG_ 1001 DstRolCntAvgNonDrvn 1;
BA_REL_ "GenSigTimeoutTime" BU_SG_REL_ EBCM_OBD_HS SG_ 1001 DstRolCntAvgDrnRstOc 250;
BA_REL_ "GenSigTimeoutMsg" BU_SG_REL_ EBCM_OBD_HS SG_ 1001 DstRolCntAvgDrnRstOc 1001;
BA_REL_ "GenSigSuprvResp" BU_SG_REL_ EBCM_OBD_HS SG_ 1001 DstRolCntAvgDrnRstOc 1;
BA_REL_ "GenSigTimeoutTime" BU_SG_REL_ BCP_HS SG_ 1001 DstRolCntAvgDrnRstOc 250;
BA_REL_ "GenSigTimeoutMsg" BU_SG_REL_ BCP_HS SG_ 1001 DstRolCntAvgDrnRstOc 1001;
BA_REL_ "GenSigSuprvResp" BU_SG_REL_ BCP_HS SG_ 1001 DstRolCntAvgDrnRstOc 1;
BA_REL_ "GenSigTimeoutTime" BU_SG_REL_ EBCM_HS SG_ 1001 DstRolCntAvgDrnRstOc 250;
BA_REL_ "GenSigTimeoutMsg" BU_SG_REL_ EBCM_HS SG_ 1001 DstRolCntAvgDrnRstOc 1001;
BA_REL_ "GenSigSuprvResp" BU_SG_REL_ EBCM_HS SG_ 1001 DstRolCntAvgDrnRstOc 1;
BA_REL_ "GenSigVBitResp" BU_SG_REL_ ICCM_OBD_HS SG_ 1001 DistRollCntAvgDrvn 1;
BA_REL_ "GenSigTimeoutTime" BU_SG_REL_ EBCM_OBD_HS SG_ 1001 DistRollCntAvgDrvn 250;
BA_REL_ "GenSigTimeoutMsg" BU_SG_REL_ EBCM_OBD_HS SG_ 1001 DistRollCntAvgDrvn 1001;
BA_REL_ "GenSigSuprvResp" BU_SG_REL_ EBCM_OBD_HS SG_ 1001 DistRollCntAvgDrvn 1;
BA_REL_ "GenSigVBitResp" BU_SG_REL_ ICCM_HS SG_ 1001 DistRollCntAvgDrvn 1;
BA_REL_ "GenSigTimeoutTime" BU_SG_REL_ BCP_HS SG_ 1001 DistRollCntAvgDrvn 250;
BA_REL_ "GenSigTimeoutMsg" BU_SG_REL_ BCP_HS SG_ 1001 DistRollCntAvgDrvn 1001;
BA_REL_ "GenSigSuprvResp" BU_SG_REL_ BCP_HS SG_ 1001 DistRollCntAvgDrvn 1;
BA_REL_ "GenSigTimeoutTime" BU_SG_REL_ EBCM_HS SG_ 1001 DistRollCntAvgDrvn 250;
BA_REL_ "GenSigTimeoutMsg" BU_SG_REL_ EBCM_HS SG_ 1001 DistRollCntAvgDrvn 1001;
BA_REL_ "GenSigSuprvResp" BU_SG_REL_ EBCM_HS SG_ 1001 DistRollCntAvgDrvn 1;
BA_REL_ "GenSigTimeoutTime" BU_SG_REL_ BCM_HS SG_ 1001 DistRollCntAvgDrvn 250;
BA_REL_ "GenSigTimeoutMsg" BU_SG_REL_ BCM_HS SG_ 1001 DistRollCntAvgDrvn 1001;
BA_REL_ "GenSigVBitResp" BU_SG_REL_ BCM_HS SG_ 1001 DistRollCntAvgDrvn 1;
BA_REL_ "GenSigSuprvResp" BU_SG_REL_ BCM_HS SG_ 1001 DistRollCntAvgDrvn 1;
BA_REL_ "GenSigTimeoutTime" BU_SG_REL_ HMIM_HS SG_ 1001 VehSpdAvgNDrvn 250;
BA_REL_ "GenSigTimeoutMsg" BU_SG_REL_ HMIM_HS SG_ 1001 VehSpdAvgNDrvn 1001;
BA_REL_ "GenSigSuprvResp" BU_SG_REL_ HMIM_HS SG_ 1001 VehSpdAvgNDrvn 1;
BA_REL_ "GenSigTimeoutTime" BU_SG_REL_ EPB_HS SG_ 1001 VehSpdAvgNDrvn 250;
BA_REL_ "GenSigTimeoutMsg" BU_SG_REL_ EPB_HS SG_ 1001 VehSpdAvgNDrvn 1001;
BA_REL_ "GenSigSuprvResp" BU_SG_REL_ EPB_HS SG_ 1001 VehSpdAvgNDrvn 1;
BA_REL_ "GenSigTimeoutTime" BU_SG_REL_ TCCM_HS SG_ 1001 VehSpdAvgNDrvn 250;
BA_REL_ "GenSigTimeoutMsg" BU_SG_REL_ TCCM_HS SG_ 1001 VehSpdAvgNDrvn 1001;
BA_REL_ "GenSigSuprvResp" BU_SG_REL_ TCCM_HS SG_ 1001 VehSpdAvgNDrvn 1;
BA_REL_ "GenSigTimeoutTime" BU_SG_REL_ BCM_HS SG_ 1001 VehSpdAvgNDrvn 250;
BA_REL_ "GenSigTimeoutMsg" BU_SG_REL_ BCM_HS SG_ 1001 VehSpdAvgNDrvn 1001;
BA_REL_ "GenSigVBitResp" BU_SG_REL_ BCM_HS SG_ 1001 VehSpdAvgNDrvn 1;
BA_REL_ "GenSigSuprvResp" BU_SG_REL_ BCM_HS SG_ 1001 VehSpdAvgNDrvn 1;
BA_REL_ "GenSigTimeoutTime" BU_SG_REL_ ICCM_OBD_HS SG_ 1001 VehSpdAvgDrvn 250;
BA_REL_ "GenSigTimeoutMsg" BU_SG_REL_ ICCM_OBD_HS SG_ 1001 VehSpdAvgDrvn 1001;
BA_REL_ "GenSigVBitResp" BU_SG_REL_ ICCM_OBD_HS SG_ 1001 VehSpdAvgDrvn 1;
BA_REL_ "GenSigSuprvResp" BU_SG_REL_ ICCM_OBD_HS SG_ 1001 VehSpdAvgDrvn 1;
BA_REL_ "GenSigTimeoutTime" BU_SG_REL_ EBCM_OBD_HS SG_ 1001 VehSpdAvgDrvn 250;
BA_REL_ "GenSigTimeoutMsg" BU_SG_REL_ EBCM_OBD_HS SG_ 1001 VehSpdAvgDrvn 1001;
BA_REL_ "GenSigSuprvResp" BU_SG_REL_ EBCM_OBD_HS SG_ 1001 VehSpdAvgDrvn 1;
BA_REL_ "GenSigTimeoutTime" BU_SG_REL_ ICCM_HS SG_ 1001 VehSpdAvgDrvn 250;
BA_REL_ "GenSigTimeoutMsg" BU_SG_REL_ ICCM_HS SG_ 1001 VehSpdAvgDrvn 1001;
BA_REL_ "GenSigVBitResp" BU_SG_REL_ ICCM_HS SG_ 1001 VehSpdAvgDrvn 1;
BA_REL_ "GenSigSuprvResp" BU_SG_REL_ ICCM_HS SG_ 1001 VehSpdAvgDrvn 1;
BA_REL_ "GenSigTimeoutTime" BU_SG_REL_ EPS_HS SG_ 1001 VehSpdAvgDrvn 250;
BA_REL_ "GenSigTimeoutMsg" BU_SG_REL_ EPS_HS SG_ 1001 VehSpdAvgDrvn 1001;
BA_REL_ "GenSigSuprvResp" BU_SG_REL_ EPS_HS SG_ 1001 VehSpdAvgDrvn 1;
BA_REL_ "GenSigTimeoutTime" BU_SG_REL_ EPB_HS SG_ 1001 VehSpdAvgDrvn 250;
BA_REL_ "GenSigTimeoutMsg" BU_SG_REL_ EPB_HS SG_ 1001 VehSpdAvgDrvn 1001;
BA_REL_ "GenSigSuprvResp" BU_SG_REL_ EPB_HS SG_ 1001 VehSpdAvgDrvn 1;
BA_REL_ "GenSigTimeoutTime" BU_SG_REL_ TCCM_HS SG_ 1001 VehSpdAvgDrvn 250;
BA_REL_ "GenSigTimeoutMsg" BU_SG_REL_ TCCM_HS SG_ 1001 VehSpdAvgDrvn 1001;
BA_REL_ "GenSigSuprvResp" BU_SG_REL_ TCCM_HS SG_ 1001 VehSpdAvgDrvn 1;
BA_REL_ "GenSigTimeoutTime" BU_SG_REL_ EBCM_HS SG_ 1001 VehSpdAvgDrvn 250;
BA_REL_ "GenSigTimeoutMsg" BU_SG_REL_ EBCM_HS SG_ 1001 VehSpdAvgDrvn 1001;
BA_REL_ "GenSigSuprvResp" BU_SG_REL_ EBCM_HS SG_ 1001 VehSpdAvgDrvn 1;
BA_REL_ "GenSigTimeoutTime" BU_SG_REL_ BCM_HS SG_ 1001 VehSpdAvgDrvn 250;
BA_REL_ "GenSigTimeoutMsg" BU_SG_REL_ BCM_HS SG_ 1001 VehSpdAvgDrvn 1001;
BA_REL_ "GenSigVBitResp" BU_SG_REL_ BCM_HS SG_ 1001 VehSpdAvgDrvn 1;
BA_REL_ "GenSigSuprvResp" BU_SG_REL_ BCM_HS SG_ 1001 VehSpdAvgDrvn 1;
BA_REL_ "GenSigVBitResp" BU_SG_REL_ ICCM_OBD_HS SG_ 1019 FuelAlcoholComp 1;
BA_REL_ "GenSigVBitResp" BU_SG_REL_ ICCM_HS SG_ 1019 FuelAlcoholComp 1;
BA_REL_ "GenSigTimeoutTime" BU_SG_REL_ ICCM_OBD_HS SG_ 493 EngRunng 250;
BA_REL_ "GenSigTimeoutMsg" BU_SG_REL_ ICCM_OBD_HS SG_ 493 EngRunng 493;
BA_REL_ "GenSigSuprvResp" BU_SG_REL_ ICCM_OBD_HS SG_ 493 EngRunng 1;
BA_REL_ "GenSigTimeoutTime" BU_SG_REL_ ICCM_HS SG_ 493 EngRunng 250;
BA_REL_ "GenSigTimeoutMsg" BU_SG_REL_ ICCM_HS SG_ 493 EngRunng 493;
BA_REL_ "GenSigSuprvResp" BU_SG_REL_ ICCM_HS SG_ 493 EngRunng 1;
BA_REL_ "GenSigTimeoutTime" BU_SG_REL_ ICCM_OBD_HS SG_ 493 FlPmpEDscOtptCmdSta 250;
BA_REL_ "GenSigTimeoutMsg" BU_SG_REL_ ICCM_OBD_HS SG_ 493 FlPmpEDscOtptCmdSta 493;
BA_REL_ "GenSigSuprvResp" BU_SG_REL_ ICCM_OBD_HS SG_ 493 FlPmpEDscOtptCmdSta 1;
BA_REL_ "GenSigTimeoutTime" BU_SG_REL_ ICCM_HS SG_ 493 FlPmpEDscOtptCmdSta 250;
BA_REL_ "GenSigTimeoutMsg" BU_SG_REL_ ICCM_HS SG_ 493 FlPmpEDscOtptCmdSta 493;
BA_REL_ "GenSigSuprvResp" BU_SG_REL_ ICCM_HS SG_ 493 FlPmpEDscOtptCmdSta 1;
BA_REL_ "GenSigTimeoutTime" BU_SG_REL_ ICCM_OBD_HS SG_ 493 CmmndAirFuelRatio 250;
BA_REL_ "GenSigTimeoutMsg" BU_SG_REL_ ICCM_OBD_HS SG_ 493 CmmndAirFuelRatio 493;
BA_REL_ "GenSigSuprvResp" BU_SG_REL_ ICCM_OBD_HS SG_ 493 CmmndAirFuelRatio 1;
BA_REL_ "GenSigTimeoutTime" BU_SG_REL_ ICCM_HS SG_ 493 CmmndAirFuelRatio 250;
BA_REL_ "GenSigTimeoutMsg" BU_SG_REL_ ICCM_HS SG_ 493 CmmndAirFuelRatio 493;
BA_REL_ "GenSigSuprvResp" BU_SG_REL_ ICCM_HS SG_ 493 CmmndAirFuelRatio 1;
BA_REL_ "GenSigTimeoutTime" BU_SG_REL_ ICCM_OBD_HS SG_ 493 AdvFuelFlowEst 250;
BA_REL_ "GenSigTimeoutMsg" BU_SG_REL_ ICCM_OBD_HS SG_ 493 AdvFuelFlowEst 493;
BA_REL_ "GenSigSuprvResp" BU_SG_REL_ ICCM_OBD_HS SG_ 493 AdvFuelFlowEst 1;
BA_REL_ "GenSigTimeoutTime" BU_SG_REL_ ICCM_HS SG_ 493 AdvFuelFlowEst 250;
BA_REL_ "GenSigTimeoutMsg" BU_SG_REL_ ICCM_HS SG_ 493 AdvFuelFlowEst 493;
BA_REL_ "GenSigSuprvResp" BU_SG_REL_ ICCM_HS SG_ 493 AdvFuelFlowEst 1;
BA_REL_ "GenSigTimeoutTime" BU_SG_REL_ ICCM_OBD_HS SG_ 493 InstFuelFlowEst 250;
BA_REL_ "GenSigTimeoutMsg" BU_SG_REL_ ICCM_OBD_HS SG_ 493 InstFuelFlowEst 493;
BA_REL_ "GenSigSuprvResp" BU_SG_REL_ ICCM_OBD_HS SG_ 493 InstFuelFlowEst 1;
BA_REL_ "GenSigTimeoutTime" BU_SG_REL_ ICCM_HS SG_ 493 InstFuelFlowEst 250;
BA_REL_ "GenSigTimeoutMsg" BU_SG_REL_ ICCM_HS SG_ 493 InstFuelFlowEst 493;
BA_REL_ "GenSigSuprvResp" BU_SG_REL_ ICCM_HS SG_ 493 InstFuelFlowEst 1;
BA_REL_ "GenSigTimeoutTime" BU_SG_REL_ ICCM_OBD_HS SG_ 493 FuelDelPressRqd 250;
BA_REL_ "GenSigTimeoutMsg" BU_SG_REL_ ICCM_OBD_HS SG_ 493 FuelDelPressRqd 493;
BA_REL_ "GenSigSuprvResp" BU_SG_REL_ ICCM_OBD_HS SG_ 493 FuelDelPressRqd 1;
BA_REL_ "GenSigTimeoutTime" BU_SG_REL_ ICCM_HS SG_ 493 FuelDelPressRqd 250;
BA_REL_ "GenSigTimeoutMsg" BU_SG_REL_ ICCM_HS SG_ 493 FuelDelPressRqd 493;
BA_REL_ "GenSigSuprvResp" BU_SG_REL_ ICCM_HS SG_ 493 FuelDelPressRqd 1;
BA_REL_ "GenSigTimeoutTime" BU_SG_REL_ ICCM_OBD_HS SG_ 493 FuelCntlSysFltPrsnt 250;
BA_REL_ "GenSigTimeoutMsg" BU_SG_REL_ ICCM_OBD_HS SG_ 493 FuelCntlSysFltPrsnt 493;
BA_REL_ "GenSigSuprvResp" BU_SG_REL_ ICCM_OBD_HS SG_ 493 FuelCntlSysFltPrsnt 1;
BA_REL_ "GenSigTimeoutTime" BU_SG_REL_ ICCM_HS SG_ 493 FuelCntlSysFltPrsnt 250;
BA_REL_ "GenSigTimeoutMsg" BU_SG_REL_ ICCM_HS SG_ 493 FuelCntlSysFltPrsnt 493;
BA_REL_ "GenSigSuprvResp" BU_SG_REL_ ICCM_HS SG_ 493 FuelCntlSysFltPrsnt 1;
BA_REL_ "GenSigTimeoutTime" BU_SG_REL_ TCM_HS SG_ 401 TrnsEngSpdReqFld 31;
BA_REL_ "GenSigTimeoutMsg" BU_SG_REL_ TCM_HS SG_ 401 TrnsEngSpdReqFld 401;
BA_REL_ "GenSigSuprvResp" BU_SG_REL_ TCM_HS SG_ 401 TrnsEngSpdReqFld 1;
BA_REL_ "GenSigTimeoutTime" BU_SG_REL_ TCCM_HS SG_ 401 ThrtCommndPos 250;
BA_REL_ "GenSigTimeoutMsg" BU_SG_REL_ TCCM_HS SG_ 401 ThrtCommndPos 401;
BA_REL_ "GenSigSuprvResp" BU_SG_REL_ TCCM_HS SG_ 401 ThrtCommndPos 1;
BA_REL_ "GenSigTimeoutTime" BU_SG_REL_ TCM_HS SG_ 401 EngTrqTnsRqFld 31;
BA_REL_ "GenSigTimeoutMsg" BU_SG_REL_ TCM_HS SG_ 401 EngTrqTnsRqFld 401;
BA_REL_ "GenSigSuprvResp" BU_SG_REL_ TCM_HS SG_ 401 EngTrqTnsRqFld 1;
BA_REL_ "GenSigTimeoutTime" BU_SG_REL_ TCCM_HS SG_ 707 EngTrqMaxExtRng 250;
BA_REL_ "GenSigTimeoutMsg" BU_SG_REL_ TCCM_HS SG_ 707 EngTrqMaxExtRng 707;
BA_REL_ "GenSigSuprvResp" BU_SG_REL_ TCCM_HS SG_ 707 EngTrqMaxExtRng 1;
BA_REL_ "GenSigTimeoutTime" BU_SG_REL_ BCM_HS SG_ 1265 PTSysHzrdLghtReq 2500;
BA_REL_ "GenSigTimeoutMsg" BU_SG_REL_ BCM_HS SG_ 1265 PTSysHzrdLghtReq 1265;
BA_REL_ "GenSigSuprvResp" BU_SG_REL_ BCM_HS SG_ 1265 PTSysHzrdLghtReq 1;
BA_REL_ "GenSigTimeoutTime" BU_SG_REL_ EPS_HS SG_ 1265 WhlDistPrRevNDrvn 2500;
BA_REL_ "GenSigTimeoutMsg" BU_SG_REL_ EPS_HS SG_ 1265 WhlDistPrRevNDrvn 1265;
BA_REL_ "GenSigSuprvResp" BU_SG_REL_ EPS_HS SG_ 1265 WhlDistPrRevNDrvn 1;
BA_REL_ "GenSigTimeoutTime" BU_SG_REL_ TCCM_HS SG_ 1265 WhlDistPrRevNDrvn 2500;
BA_REL_ "GenSigTimeoutMsg" BU_SG_REL_ TCCM_HS SG_ 1265 WhlDistPrRevNDrvn 1265;
BA_REL_ "GenSigSuprvResp" BU_SG_REL_ TCCM_HS SG_ 1265 WhlDistPrRevNDrvn 1;
BA_REL_ "GenSigTimeoutTime" BU_SG_REL_ TCM_HS SG_ 1265 WhlDistPrRevNDrvn 2500;
BA_REL_ "GenSigTimeoutMsg" BU_SG_REL_ TCM_HS SG_ 1265 WhlDistPrRevNDrvn 1265;
BA_REL_ "GenSigSuprvResp" BU_SG_REL_ TCM_HS SG_ 1265 WhlDistPrRevNDrvn 1;
BA_REL_ "GenSigTimeoutTime" BU_SG_REL_ EPS_HS SG_ 1265 WhlDistPrRevDrvn 2500;
BA_REL_ "GenSigTimeoutMsg" BU_SG_REL_ EPS_HS SG_ 1265 WhlDistPrRevDrvn 1265;
BA_REL_ "GenSigSuprvResp" BU_SG_REL_ EPS_HS SG_ 1265 WhlDistPrRevDrvn 1;
BA_REL_ "GenSigTimeoutTime" BU_SG_REL_ TCCM_HS SG_ 1265 WhlDistPrRevDrvn 2500;
BA_REL_ "GenSigTimeoutMsg" BU_SG_REL_ TCCM_HS SG_ 1265 WhlDistPrRevDrvn 1265;
BA_REL_ "GenSigSuprvResp" BU_SG_REL_ TCCM_HS SG_ 1265 WhlDistPrRevDrvn 1;
BA_REL_ "GenSigTimeoutTime" BU_SG_REL_ BCM_HS SG_ 1265 WhlDistPrRevDrvn 2500;
BA_REL_ "GenSigTimeoutMsg" BU_SG_REL_ BCM_HS SG_ 1265 WhlDistPrRevDrvn 1265;
BA_REL_ "GenSigSuprvResp" BU_SG_REL_ BCM_HS SG_ 1265 WhlDistPrRevDrvn 1;
BA_REL_ "GenSigTimeoutTime" BU_SG_REL_ TCM_HS SG_ 1265 WhlDistPrRevDrvn 2500;
BA_REL_ "GenSigTimeoutMsg" BU_SG_REL_ TCM_HS SG_ 1265 WhlDistPrRevDrvn 1265;
BA_REL_ "GenSigSuprvResp" BU_SG_REL_ TCM_HS SG_ 1265 WhlDistPrRevDrvn 1;
BA_REL_ "GenSigTimeoutTime" BU_SG_REL_ TCCM_HS SG_ 1265 DrvlnFnlAxleRatio 2500;
BA_REL_ "GenSigTimeoutMsg" BU_SG_REL_ TCCM_HS SG_ 1265 DrvlnFnlAxleRatio 1265;
BA_REL_ "GenSigSuprvResp" BU_SG_REL_ TCCM_HS SG_ 1265 DrvlnFnlAxleRatio 1;
BA_REL_ "GenSigTimeoutTime" BU_SG_REL_ BCM_HS SG_ 1265 DrvlnFnlAxleRatio 2500;
BA_REL_ "GenSigTimeoutMsg" BU_SG_REL_ BCM_HS SG_ 1265 DrvlnFnlAxleRatio 1265;
BA_REL_ "GenSigSuprvResp" BU_SG_REL_ BCM_HS SG_ 1265 DrvlnFnlAxleRatio 1;
BA_REL_ "GenSigTimeoutTime" BU_SG_REL_ TCM_HS SG_ 1265 DrvlnFnlAxleRatio 2500;
BA_REL_ "GenSigTimeoutMsg" BU_SG_REL_ TCM_HS SG_ 1265 DrvlnFnlAxleRatio 1265;
BA_REL_ "GenSigSuprvResp" BU_SG_REL_ TCM_HS SG_ 1265 DrvlnFnlAxleRatio 1;
BA_REL_ "GenSigTimeoutTime" BU_SG_REL_ TCM_HS SG_ 417 TracCntlSysPwrtrnInhbt 62;
BA_REL_ "GenSigTimeoutMsg" BU_SG_REL_ TCM_HS SG_ 417 TracCntlSysPwrtrnInhbt 417;
BA_REL_ "GenSigSuprvResp" BU_SG_REL_ TCM_HS SG_ 417 TracCntlSysPwrtrnInhbt 1;
BA_REL_ "GenSigTimeoutTime" BU_SG_REL_ TCM_HS SG_ 417 EngMtlProtAtv 62;
BA_REL_ "GenSigTimeoutMsg" BU_SG_REL_ TCM_HS SG_ 417 EngMtlProtAtv 417;
BA_REL_ "GenSigSuprvResp" BU_SG_REL_ TCM_HS SG_ 417 EngMtlProtAtv 1;
BA_REL_ "GenSigTimeoutTime" BU_SG_REL_ TCM_HS SG_ 417 EngDgTrqCnvClUnlkRqd 62;
BA_REL_ "GenSigTimeoutMsg" BU_SG_REL_ TCM_HS SG_ 417 EngDgTrqCnvClUnlkRqd 417;
BA_REL_ "GenSigSuprvResp" BU_SG_REL_ TCM_HS SG_ 417 EngDgTrqCnvClUnlkRqd 1;
BA_REL_ "GenSigTimeoutTime" BU_SG_REL_ TCM_HS SG_ 417 EngCyldrDeactReqd 62;
BA_REL_ "GenSigTimeoutMsg" BU_SG_REL_ TCM_HS SG_ 417 EngCyldrDeactReqd 417;
BA_REL_ "GenSigSuprvResp" BU_SG_REL_ TCM_HS SG_ 417 EngCyldrDeactReqd 1;
BA_REL_ "GenSigTimeoutTime" BU_SG_REL_ TCM_HS SG_ 417 ETGRReqdGear 62;
BA_REL_ "GenSigTimeoutMsg" BU_SG_REL_ TCM_HS SG_ 417 ETGRReqdGear 417;
BA_REL_ "GenSigSuprvResp" BU_SG_REL_ TCM_HS SG_ 417 ETGRReqdGear 1;
BA_REL_ "GenSigTimeoutTime" BU_SG_REL_ TCM_HS SG_ 417 ETGRReqType 62;
BA_REL_ "GenSigTimeoutMsg" BU_SG_REL_ TCM_HS SG_ 417 ETGRReqType 417;
BA_REL_ "GenSigSuprvResp" BU_SG_REL_ TCM_HS SG_ 417 ETGRReqType 1;
BA_REL_ "GenSigTimeoutTime" BU_SG_REL_ BCM_HS SG_ 1233 FlLvlPct 1250;
BA_REL_ "GenSigTimeoutMsg" BU_SG_REL_ BCM_HS SG_ 1233 FlLvlPct 1233;
BA_REL_ "GenSigVBitResp" BU_SG_REL_ BCM_HS SG_ 1233 FlLvlPct 1;
BA_REL_ "GenSigSuprvResp" BU_SG_REL_ BCM_HS SG_ 1233 FlLvlPct 1;
BA_REL_ "GenSigTimeoutTime" BU_SG_REL_ EPS_HS SG_ 1233 EngOilTmp 1250;
BA_REL_ "GenSigTimeoutMsg" BU_SG_REL_ EPS_HS SG_ 1233 EngOilTmp 1233;
BA_REL_ "GenSigSuprvResp" BU_SG_REL_ EPS_HS SG_ 1233 EngOilTmp 1;
BA_REL_ "GenSigTimeoutTime" BU_SG_REL_ BCM_HS SG_ 1233 EngOilTmp 1250;
BA_REL_ "GenSigTimeoutMsg" BU_SG_REL_ BCM_HS SG_ 1233 EngOilTmp 1233;
BA_REL_ "GenSigVBitResp" BU_SG_REL_ BCM_HS SG_ 1233 EngOilTmp 1;
BA_REL_ "GenSigSuprvResp" BU_SG_REL_ BCM_HS SG_ 1233 EngOilTmp 1;
BA_REL_ "GenSigTimeoutTime" BU_SG_REL_ BCM_HS SG_ 1233 EngOilPrs 1250;
BA_REL_ "GenSigTimeoutMsg" BU_SG_REL_ BCM_HS SG_ 1233 EngOilPrs 1233;
BA_REL_ "GenSigVBitResp" BU_SG_REL_ BCM_HS SG_ 1233 EngOilPrs 1;
BA_REL_ "GenSigSuprvResp" BU_SG_REL_ BCM_HS SG_ 1233 EngOilPrs 1;
BA_REL_ "GenSigTimeoutTime" BU_SG_REL_ TCCM_HS SG_ 1217 LDMinEngCltTmpRchd 1250;
BA_REL_ "GenSigTimeoutMsg" BU_SG_REL_ TCCM_HS SG_ 1217 LDMinEngCltTmpRchd 1217;
BA_REL_ "GenSigSuprvResp" BU_SG_REL_ TCCM_HS SG_ 1217 LDMinEngCltTmpRchd 1;
BA_REL_ "GenSigTimeoutTime" BU_SG_REL_ TCM_HS SG_ 1217 LDMinEngCltTmpRchd 1250;
BA_REL_ "GenSigTimeoutMsg" BU_SG_REL_ TCM_HS SG_ 1217 LDMinEngCltTmpRchd 1217;
BA_REL_ "GenSigSuprvResp" BU_SG_REL_ TCM_HS SG_ 1217 LDMinEngCltTmpRchd 1;
BA_REL_ "GenSigTimeoutTime" BU_SG_REL_ BCM_HS SG_ 1217 OAT_PT_Est 1250;
BA_REL_ "GenSigTimeoutMsg" BU_SG_REL_ BCM_HS SG_ 1217 OAT_PT_Est 1217;
BA_REL_ "GenSigVBitResp" BU_SG_REL_ BCM_HS SG_ 1217 OAT_PT_Est 1;
BA_REL_ "GenSigSuprvResp" BU_SG_REL_ BCM_HS SG_ 1217 OAT_PT_Est 1;
BA_REL_ "GenSigTimeoutTime" BU_SG_REL_ TCM_HS SG_ 1217 OAT_PT_Est 1250;
BA_REL_ "GenSigTimeoutMsg" BU_SG_REL_ TCM_HS SG_ 1217 OAT_PT_Est 1217;
BA_REL_ "GenSigSuprvResp" BU_SG_REL_ TCM_HS SG_ 1217 OAT_PT_Est 1;
BA_REL_ "GenSigTimeoutTime" BU_SG_REL_ ICCM_OBD_HS SG_ 1217 EngIntAirTmp 1250;
BA_REL_ "GenSigTimeoutMsg" BU_SG_REL_ ICCM_OBD_HS SG_ 1217 EngIntAirTmp 1217;
BA_REL_ "GenSigSuprvResp" BU_SG_REL_ ICCM_OBD_HS SG_ 1217 EngIntAirTmp 1;
BA_REL_ "GenSigTimeoutTime" BU_SG_REL_ ICCM_HS SG_ 1217 EngIntAirTmp 1250;
BA_REL_ "GenSigTimeoutMsg" BU_SG_REL_ ICCM_HS SG_ 1217 EngIntAirTmp 1217;
BA_REL_ "GenSigSuprvResp" BU_SG_REL_ ICCM_HS SG_ 1217 EngIntAirTmp 1;
BA_REL_ "GenSigTimeoutTime" BU_SG_REL_ TCCM_HS SG_ 1217 EngIntAirTmp 1250;
BA_REL_ "GenSigTimeoutMsg" BU_SG_REL_ TCCM_HS SG_ 1217 EngIntAirTmp 1217;
BA_REL_ "GenSigSuprvResp" BU_SG_REL_ TCCM_HS SG_ 1217 EngIntAirTmp 1;
BA_REL_ "GenSigTimeoutTime" BU_SG_REL_ BCM_HS SG_ 1217 EngIntAirTmp 1250;
BA_REL_ "GenSigTimeoutMsg" BU_SG_REL_ BCM_HS SG_ 1217 EngIntAirTmp 1217;
BA_REL_ "GenSigVBitResp" BU_SG_REL_ BCM_HS SG_ 1217 EngIntAirTmp 1;
BA_REL_ "GenSigSuprvResp" BU_SG_REL_ BCM_HS SG_ 1217 EngIntAirTmp 1;
BA_REL_ "GenSigTimeoutTime" BU_SG_REL_ ICCM_OBD_HS SG_ 1217 EngCltTmp 1250;
BA_REL_ "GenSigTimeoutMsg" BU_SG_REL_ ICCM_OBD_HS SG_ 1217 EngCltTmp 1217;
BA_REL_ "GenSigSuprvResp" BU_SG_REL_ ICCM_OBD_HS SG_ 1217 EngCltTmp 1;
BA_REL_ "GenSigTimeoutTime" BU_SG_REL_ ICCM_HS SG_ 1217 EngCltTmp 1250;
BA_REL_ "GenSigTimeoutMsg" BU_SG_REL_ ICCM_HS SG_ 1217 EngCltTmp 1217;
BA_REL_ "GenSigSuprvResp" BU_SG_REL_ ICCM_HS SG_ 1217 EngCltTmp 1;
BA_REL_ "GenSigTimeoutTime" BU_SG_REL_ EPS_HS SG_ 1217 EngCltTmp 1250;
BA_REL_ "GenSigTimeoutMsg" BU_SG_REL_ EPS_HS SG_ 1217 EngCltTmp 1217;
BA_REL_ "GenSigSuprvResp" BU_SG_REL_ EPS_HS SG_ 1217 EngCltTmp 1;
BA_REL_ "GenSigTimeoutTime" BU_SG_REL_ BCM_HS SG_ 1217 EngCltTmp 1250;
BA_REL_ "GenSigTimeoutMsg" BU_SG_REL_ BCM_HS SG_ 1217 EngCltTmp 1217;
BA_REL_ "GenSigVBitResp" BU_SG_REL_ BCM_HS SG_ 1217 EngCltTmp 1;
BA_REL_ "GenSigSuprvResp" BU_SG_REL_ BCM_HS SG_ 1217 EngCltTmp 1;
BA_REL_ "GenSigVBitResp" BU_SG_REL_ ICCM_OBD_HS SG_ 1217 BarPrsAbs 1;
BA_REL_ "GenSigVBitResp" BU_SG_REL_ ICCM_HS SG_ 1217 BarPrsAbs 1;
BA_REL_ "GenSigTimeoutTime" BU_SG_REL_ BCM_HS SG_ 1217 BarPrsAbs 1250;
BA_REL_ "GenSigTimeoutMsg" BU_SG_REL_ BCM_HS SG_ 1217 BarPrsAbs 1217;
BA_REL_ "GenSigVBitResp" BU_SG_REL_ BCM_HS SG_ 1217 BarPrsAbs 1;
BA_REL_ "GenSigSuprvResp" BU_SG_REL_ BCM_HS SG_ 1217 BarPrsAbs 1;
BA_REL_ "GenSigTimeoutTime" BU_SG_REL_ BCM_HS SG_ 985 ManTransIndReq 250;
BA_REL_ "GenSigTimeoutMsg" BU_SG_REL_ BCM_HS SG_ 985 ManTransIndReq 985;
BA_REL_ "GenSigSuprvResp" BU_SG_REL_ BCM_HS SG_ 985 ManTransIndReq 1;
BA_REL_ "GenSigTimeoutTime" BU_SG_REL_ BCM_HS SG_ 985 DrvEffInd 250;
BA_REL_ "GenSigTimeoutMsg" BU_SG_REL_ BCM_HS SG_ 985 DrvEffInd 985;
BA_REL_ "GenSigSuprvResp" BU_SG_REL_ BCM_HS SG_ 985 DrvEffInd 1;
BA_REL_ "GenSigTimeoutTime" BU_SG_REL_ BCM_HS SG_ 985 EngIntkArBstPrExtRng 250;
BA_REL_ "GenSigTimeoutMsg" BU_SG_REL_ BCM_HS SG_ 985 EngIntkArBstPrExtRng 985;
BA_REL_ "GenSigSuprvResp" BU_SG_REL_ BCM_HS SG_ 985 EngIntkArBstPrExtRng 1;
BA_REL_ "GenSigTimeoutTime" BU_SG_REL_ BCM_HS SG_ 985 EDADS_RcmndtFwdGr 250;
BA_REL_ "GenSigTimeoutMsg" BU_SG_REL_ BCM_HS SG_ 985 EDADS_RcmndtFwdGr 985;
BA_REL_ "GenSigSuprvResp" BU_SG_REL_ BCM_HS SG_ 985 EDADS_RcmndtFwdGr 1;
BA_REL_ "GenSigTimeoutTime" BU_SG_REL_ BCM_HS SG_ 985 EDADS_CrntFwdMsdG 250;
BA_REL_ "GenSigTimeoutMsg" BU_SG_REL_ BCM_HS SG_ 985 EDADS_CrntFwdMsdG 985;
BA_REL_ "GenSigSuprvResp" BU_SG_REL_ BCM_HS SG_ 985 EDADS_CrntFwdMsdG 1;
BA_REL_ "GenSigTimeoutTime" BU_SG_REL_ BCM_HS SG_ 985 EDADS_ShftIndStat 250;
BA_REL_ "GenSigTimeoutMsg" BU_SG_REL_ BCM_HS SG_ 985 EDADS_ShftIndStat 985;
BA_REL_ "GenSigSuprvResp" BU_SG_REL_ BCM_HS SG_ 985 EDADS_ShftIndStat 1;
BA_REL_ "GenSigTimeoutTime" BU_SG_REL_ BCM_HS SG_ 985 EDADS_EcoDrvShftIO 250;
BA_REL_ "GenSigTimeoutMsg" BU_SG_REL_ BCM_HS SG_ 985 EDADS_EcoDrvShftIO 985;
BA_REL_ "GenSigSuprvResp" BU_SG_REL_ BCM_HS SG_ 985 EDADS_EcoDrvShftIO 1;
BA_REL_ "GenSigTimeoutTime" BU_SG_REL_ ICCM_OBD_HS SG_ 1017 ACRfHiSdFldPrs 625;
BA_REL_ "GenSigTimeoutMsg" BU_SG_REL_ ICCM_OBD_HS SG_ 1017 ACRfHiSdFldPrs 1017;
BA_REL_ "GenSigSuprvResp" BU_SG_REL_ ICCM_OBD_HS SG_ 1017 ACRfHiSdFldPrs 1;
BA_REL_ "GenSigTimeoutTime" BU_SG_REL_ ICCM_HS SG_ 1017 ACRfHiSdFldPrs 625;
BA_REL_ "GenSigTimeoutMsg" BU_SG_REL_ ICCM_HS SG_ 1017 ACRfHiSdFldPrs 1017;
BA_REL_ "GenSigSuprvResp" BU_SG_REL_ ICCM_HS SG_ 1017 ACRfHiSdFldPrs 1;
BA_REL_ "GenSigTimeoutTime" BU_SG_REL_ BCM_HS SG_ 1017 ACRfHiSdFldPrs 630;
BA_REL_ "GenSigTimeoutMsg" BU_SG_REL_ BCM_HS SG_ 1017 ACRfHiSdFldPrs 1017;
BA_REL_ "GenSigVBitResp" BU_SG_REL_ BCM_HS SG_ 1017 ACRfHiSdFldPrs 1;
BA_REL_ "GenSigSuprvResp" BU_SG_REL_ BCM_HS SG_ 1017 ACRfHiSdFldPrs 1;
BA_REL_ "GenSigTimeoutTime" BU_SG_REL_ BCM_HS SG_ 1017 GenFldDutCyc 630;
BA_REL_ "GenSigTimeoutMsg" BU_SG_REL_ BCM_HS SG_ 1017 GenFldDutCyc 1017;
BA_REL_ "GenSigVBitResp" BU_SG_REL_ BCM_HS SG_ 1017 GenFldDutCyc 1;
BA_REL_ "GenSigSuprvResp" BU_SG_REL_ BCM_HS SG_ 1017 GenFldDutCyc 1;
BA_REL_ "GenSigTimeoutTime" BU_SG_REL_ ICCM_OBD_HS SG_ 1017 EngCoolFanSpd 625;
BA_REL_ "GenSigTimeoutMsg" BU_SG_REL_ ICCM_OBD_HS SG_ 1017 EngCoolFanSpd 1017;
BA_REL_ "GenSigSuprvResp" BU_SG_REL_ ICCM_OBD_HS SG_ 1017 EngCoolFanSpd 1;
BA_REL_ "GenSigTimeoutTime" BU_SG_REL_ ICCM_HS SG_ 1017 EngCoolFanSpd 625;
BA_REL_ "GenSigTimeoutMsg" BU_SG_REL_ ICCM_HS SG_ 1017 EngCoolFanSpd 1017;
BA_REL_ "GenSigSuprvResp" BU_SG_REL_ ICCM_HS SG_ 1017 EngCoolFanSpd 1;
BA_REL_ "GenSigTimeoutTime" BU_SG_REL_ BCM_HS SG_ 977 AutoMdSpdLmtStat 250;
BA_REL_ "GenSigTimeoutMsg" BU_SG_REL_ BCM_HS SG_ 977 AutoMdSpdLmtStat 977;
BA_REL_ "GenSigSuprvResp" BU_SG_REL_ BCM_HS SG_ 977 AutoMdSpdLmtStat 1;
BA_REL_ "GenSigTimeoutTime" BU_SG_REL_ BCM_HS SG_ 977 SpdLmtrSpdWrngAct 250;
BA_REL_ "GenSigTimeoutMsg" BU_SG_REL_ BCM_HS SG_ 977 SpdLmtrSpdWrngAct 977;
BA_REL_ "GenSigSuprvResp" BU_SG_REL_ BCM_HS SG_ 977 SpdLmtrSpdWrngAct 1;
BA_REL_ "GenSigTimeoutTime" BU_SG_REL_ ICCM_OBD_HS SG_ 977 ACCompCmnd 250;
BA_REL_ "GenSigTimeoutMsg" BU_SG_REL_ ICCM_OBD_HS SG_ 977 ACCompCmnd 977;
BA_REL_ "GenSigSuprvResp" BU_SG_REL_ ICCM_OBD_HS SG_ 977 ACCompCmnd 1;
BA_REL_ "GenSigTimeoutTime" BU_SG_REL_ ICCM_HS SG_ 977 ACCompCmnd 250;
BA_REL_ "GenSigTimeoutMsg" BU_SG_REL_ ICCM_HS SG_ 977 ACCompCmnd 977;
BA_REL_ "GenSigSuprvResp" BU_SG_REL_ ICCM_HS SG_ 977 ACCompCmnd 1;
BA_REL_ "GenSigTimeoutTime" BU_SG_REL_ TCM_HS SG_ 977 ACCompCmnd 250;
BA_REL_ "GenSigTimeoutMsg" BU_SG_REL_ TCM_HS SG_ 977 ACCompCmnd 977;
BA_REL_ "GenSigSuprvResp" BU_SG_REL_ TCM_HS SG_ 977 ACCompCmnd 1;
BA_REL_ "GenSigTimeoutTime" BU_SG_REL_ BCM_HS SG_ 977 EngBstPrsInd 250;
BA_REL_ "GenSigTimeoutMsg" BU_SG_REL_ BCM_HS SG_ 977 EngBstPrsInd 977;
BA_REL_ "GenSigVBitResp" BU_SG_REL_ BCM_HS SG_ 977 EngBstPrsInd 1;
BA_REL_ "GenSigSuprvResp" BU_SG_REL_ BCM_HS SG_ 977 EngBstPrsInd 1;
BA_REL_ "GenSigTimeoutTime" BU_SG_REL_ BCM_HS SG_ 977 ThrPos 250;
BA_REL_ "GenSigTimeoutMsg" BU_SG_REL_ BCM_HS SG_ 977 ThrPos 977;
BA_REL_ "GenSigVBitResp" BU_SG_REL_ BCM_HS SG_ 977 ThrPos 1;
BA_REL_ "GenSigSuprvResp" BU_SG_REL_ BCM_HS SG_ 977 ThrPos 1;
BA_REL_ "GenSigRxStartValue" BU_SG_REL_ BCM_HS SG_ 977 EngEmsRelMalfIndReq "$0 - Continuous Indication";
BA_REL_ "GenSigTimeoutTime" BU_SG_REL_ TCM_HS SG_ 977 EngCstFlCutAct 250;
BA_REL_ "GenSigTimeoutMsg" BU_SG_REL_ TCM_HS SG_ 977 EngCstFlCutAct 977;
BA_REL_ "GenSigSuprvResp" BU_SG_REL_ TCM_HS SG_ 977 EngCstFlCutAct 1;
BA_REL_ "GenSigTimeoutTime" BU_SG_REL_ CGM_HS SG_ 201 Eng12vStrtrMtrCmmdOn 250;
BA_REL_ "GenSigTimeoutMsg" BU_SG_REL_ CGM_HS SG_ 201 Eng12vStrtrMtrCmmdOn 201;
BA_REL_ "GenSigSuprvResp" BU_SG_REL_ CGM_HS SG_ 201 Eng12vStrtrMtrCmmdOn 1;
BA_REL_ "GenSigTimeoutTime" BU_SG_REL_ ICCM_OBD_HS SG_ 201 Eng12vStrtrMtrCmmdOn 250;
BA_REL_ "GenSigTimeoutMsg" BU_SG_REL_ ICCM_OBD_HS SG_ 201 Eng12vStrtrMtrCmmdOn 201;
BA_REL_ "GenSigSuprvResp" BU_SG_REL_ ICCM_OBD_HS SG_ 201 Eng12vStrtrMtrCmmdOn 1;
BA_REL_ "GenSigTimeoutTime" BU_SG_REL_ ICCM_HS SG_ 201 Eng12vStrtrMtrCmmdOn 250;
BA_REL_ "GenSigTimeoutMsg" BU_SG_REL_ ICCM_HS SG_ 201 Eng12vStrtrMtrCmmdOn 201;
BA_REL_ "GenSigSuprvResp" BU_SG_REL_ ICCM_HS SG_ 201 Eng12vStrtrMtrCmmdOn 1;
BA_REL_ "GenSigTimeoutTime" BU_SG_REL_ EPS_HS SG_ 201 Eng12vStrtrMtrCmmdOn 250;
BA_REL_ "GenSigTimeoutMsg" BU_SG_REL_ EPS_HS SG_ 201 Eng12vStrtrMtrCmmdOn 201;
BA_REL_ "GenSigSuprvResp" BU_SG_REL_ EPS_HS SG_ 201 Eng12vStrtrMtrCmmdOn 1;
BA_REL_ "GenSigTimeoutTime" BU_SG_REL_ TCCM_HS SG_ 201 Eng12vStrtrMtrCmmdOn 31;
BA_REL_ "GenSigTimeoutMsg" BU_SG_REL_ TCCM_HS SG_ 201 Eng12vStrtrMtrCmmdOn 201;
BA_REL_ "GenSigSuprvResp" BU_SG_REL_ TCCM_HS SG_ 201 Eng12vStrtrMtrCmmdOn 1;
BA_REL_ "GenSigTimeoutTime" BU_SG_REL_ BCM_HS SG_ 201 Eng12vStrtrMtrCmmdOn 250;
BA_REL_ "GenSigTimeoutMsg" BU_SG_REL_ BCM_HS SG_ 201 Eng12vStrtrMtrCmmdOn 201;
BA_REL_ "GenSigSuprvResp" BU_SG_REL_ BCM_HS SG_ 201 Eng12vStrtrMtrCmmdOn 1;
BA_REL_ "GenSigTimeoutTime" BU_SG_REL_ ICCM_OBD_HS SG_ 201 EngCntrlRunCrnkTrmSt 250;
BA_REL_ "GenSigTimeoutMsg" BU_SG_REL_ ICCM_OBD_HS SG_ 201 EngCntrlRunCrnkTrmSt 201;
BA_REL_ "GenSigSuprvResp" BU_SG_REL_ ICCM_OBD_HS SG_ 201 EngCntrlRunCrnkTrmSt 1;
BA_REL_ "GenSigTimeoutTime" BU_SG_REL_ ICCM_HS SG_ 201 EngCntrlRunCrnkTrmSt 250;
BA_REL_ "GenSigTimeoutMsg" BU_SG_REL_ ICCM_HS SG_ 201 EngCntrlRunCrnkTrmSt 201;
BA_REL_ "GenSigSuprvResp" BU_SG_REL_ ICCM_HS SG_ 201 EngCntrlRunCrnkTrmSt 1;
BA_REL_ "GenSigTimeoutTime" BU_SG_REL_ EBCM_OBD_HS SG_ 201 EngAirIntBstPr 250;
BA_REL_ "GenSigTimeoutMsg" BU_SG_REL_ EBCM_OBD_HS SG_ 201 EngAirIntBstPr 201;
BA_REL_ "GenSigSuprvResp" BU_SG_REL_ EBCM_OBD_HS SG_ 201 EngAirIntBstPr 1;
BA_REL_ "GenSigTimeoutTime" BU_SG_REL_ EBCM_HS SG_ 201 EngAirIntBstPr 250;
BA_REL_ "GenSigTimeoutMsg" BU_SG_REL_ EBCM_HS SG_ 201 EngAirIntBstPr 201;
BA_REL_ "GenSigSuprvResp" BU_SG_REL_ EBCM_HS SG_ 201 EngAirIntBstPr 1;
BA_REL_ "GenSigTimeoutTime" BU_SG_REL_ CGM_HS SG_ 201 EngCylDactEvntPndg 250;
BA_REL_ "GenSigTimeoutMsg" BU_SG_REL_ CGM_HS SG_ 201 EngCylDactEvntPndg 201;
BA_REL_ "GenSigSuprvResp" BU_SG_REL_ CGM_HS SG_ 201 EngCylDactEvntPndg 1;
BA_REL_ "GenSigTimeoutTime" BU_SG_REL_ ICCM_OBD_HS SG_ 201 EngCylDactEvntPndg 250;
BA_REL_ "GenSigTimeoutMsg" BU_SG_REL_ ICCM_OBD_HS SG_ 201 EngCylDactEvntPndg 201;
BA_REL_ "GenSigSuprvResp" BU_SG_REL_ ICCM_OBD_HS SG_ 201 EngCylDactEvntPndg 1;
BA_REL_ "GenSigTimeoutTime" BU_SG_REL_ ICCM_HS SG_ 201 EngCylDactEvntPndg 250;
BA_REL_ "GenSigTimeoutMsg" BU_SG_REL_ ICCM_HS SG_ 201 EngCylDactEvntPndg 201;
BA_REL_ "GenSigSuprvResp" BU_SG_REL_ ICCM_HS SG_ 201 EngCylDactEvntPndg 1;
BA_REL_ "GenSigTimeoutTime" BU_SG_REL_ CGM_HS SG_ 201 EngCylDeactMd 250;
BA_REL_ "GenSigTimeoutMsg" BU_SG_REL_ CGM_HS SG_ 201 EngCylDeactMd 201;
BA_REL_ "GenSigSuprvResp" BU_SG_REL_ CGM_HS SG_ 201 EngCylDeactMd 1;
BA_REL_ "GenSigTimeoutTime" BU_SG_REL_ ICCM_OBD_HS SG_ 201 EngCylDeactMd 250;
BA_REL_ "GenSigTimeoutMsg" BU_SG_REL_ ICCM_OBD_HS SG_ 201 EngCylDeactMd 201;
BA_REL_ "GenSigSuprvResp" BU_SG_REL_ ICCM_OBD_HS SG_ 201 EngCylDeactMd 1;
BA_REL_ "GenSigTimeoutTime" BU_SG_REL_ ICCM_HS SG_ 201 EngCylDeactMd 250;
BA_REL_ "GenSigTimeoutMsg" BU_SG_REL_ ICCM_HS SG_ 201 EngCylDeactMd 201;
BA_REL_ "GenSigSuprvResp" BU_SG_REL_ ICCM_HS SG_ 201 EngCylDeactMd 1;
BA_REL_ "GenSigTimeoutTime" BU_SG_REL_ CGM_HS SG_ 201 RmVhStrtEngRng 250;
BA_REL_ "GenSigTimeoutMsg" BU_SG_REL_ CGM_HS SG_ 201 RmVhStrtEngRng 201;
BA_REL_ "GenSigSuprvResp" BU_SG_REL_ CGM_HS SG_ 201 RmVhStrtEngRng 1;
BA_REL_ "GenSigTimeoutTime" BU_SG_REL_ EBCM_OBD_HS SG_ 201 RmVhStrtEngRng 250;
BA_REL_ "GenSigTimeoutMsg" BU_SG_REL_ EBCM_OBD_HS SG_ 201 RmVhStrtEngRng 201;
BA_REL_ "GenSigSuprvResp" BU_SG_REL_ EBCM_OBD_HS SG_ 201 RmVhStrtEngRng 1;
BA_REL_ "GenSigTimeoutTime" BU_SG_REL_ EPB_HS SG_ 201 RmVhStrtEngRng 250;
BA_REL_ "GenSigTimeoutMsg" BU_SG_REL_ EPB_HS SG_ 201 RmVhStrtEngRng 201;
BA_REL_ "GenSigSuprvResp" BU_SG_REL_ EPB_HS SG_ 201 RmVhStrtEngRng 1;
BA_REL_ "GenSigTimeoutTime" BU_SG_REL_ EBCM_HS SG_ 201 RmVhStrtEngRng 250;
BA_REL_ "GenSigTimeoutMsg" BU_SG_REL_ EBCM_HS SG_ 201 RmVhStrtEngRng 201;
BA_REL_ "GenSigSuprvResp" BU_SG_REL_ EBCM_HS SG_ 201 RmVhStrtEngRng 1;
BA_REL_ "GenSigTimeoutTime" BU_SG_REL_ BCM_HS SG_ 201 RmVhStrtEngRng 50;
BA_REL_ "GenSigTimeoutMsg" BU_SG_REL_ BCM_HS SG_ 201 RmVhStrtEngRng 201;
BA_REL_ "GenSigSuprvResp" BU_SG_REL_ BCM_HS SG_ 201 RmVhStrtEngRng 2;
BA_REL_ "GenSigRxStartValue" BU_SG_REL_ BCM_HS SG_ 201 PltfrmEngSpdCmdInhtRq "$0-Allow Platform Engine Speed Control";
BA_REL_ "GenSigTimeoutTime" BU_SG_REL_ CGM_HS SG_ 201 PT_BrkPedDscrtInpStat 250;
BA_REL_ "GenSigTimeoutMsg" BU_SG_REL_ CGM_HS SG_ 201 PT_BrkPedDscrtInpStat 201;
BA_REL_ "GenSigSuprvResp" BU_SG_REL_ CGM_HS SG_ 201 PT_BrkPedDscrtInpStat 1;
BA_REL_ "GenSigTimeoutTime" BU_SG_REL_ TCM_HS SG_ 201 PT_BrkPedDscrtInpStat 250;
BA_REL_ "GenSigTimeoutMsg" BU_SG_REL_ TCM_HS SG_ 201 PT_BrkPedDscrtInpStat 201;
BA_REL_ "GenSigSuprvResp" BU_SG_REL_ TCM_HS SG_ 201 PT_BrkPedDscrtInpStat 1;
BA_REL_ "GenSigTimeoutTime" BU_SG_REL_ CGM_HS SG_ 201 AccActPos 250;
BA_REL_ "GenSigTimeoutMsg" BU_SG_REL_ CGM_HS SG_ 201 AccActPos 201;
BA_REL_ "GenSigSuprvResp" BU_SG_REL_ CGM_HS SG_ 201 AccActPos 1;
BA_REL_ "GenSigTimeoutTime" BU_SG_REL_ EPB_HS SG_ 201 AccActPos 250;
BA_REL_ "GenSigTimeoutMsg" BU_SG_REL_ EPB_HS SG_ 201 AccActPos 201;
BA_REL_ "GenSigSuprvResp" BU_SG_REL_ EPB_HS SG_ 201 AccActPos 1;
BA_REL_ "GenSigTimeoutTime" BU_SG_REL_ BCM_HS SG_ 201 AccActPos 50;
BA_REL_ "GenSigTimeoutMsg" BU_SG_REL_ BCM_HS SG_ 201 AccActPos 201;
BA_REL_ "GenSigVBitResp" BU_SG_REL_ BCM_HS SG_ 201 AccActPos 1;
BA_REL_ "GenSigSuprvResp" BU_SG_REL_ BCM_HS SG_ 201 AccActPos 1;
BA_REL_ "GenSigTimeoutTime" BU_SG_REL_ TCM_HS SG_ 201 AccActPos 250;
BA_REL_ "GenSigTimeoutMsg" BU_SG_REL_ TCM_HS SG_ 201 AccActPos 201;
BA_REL_ "GenSigSuprvResp" BU_SG_REL_ TCM_HS SG_ 201 AccActPos 1;
BA_REL_ "GenSigTimeoutTime" BU_SG_REL_ CGM_HS SG_ 201 CrsCntEnbld 250;
BA_REL_ "GenSigTimeoutMsg" BU_SG_REL_ CGM_HS SG_ 201 CrsCntEnbld 201;
BA_REL_ "GenSigSuprvResp" BU_SG_REL_ CGM_HS SG_ 201 CrsCntEnbld 1;
BA_REL_ "GenSigTimeoutTime" BU_SG_REL_ CGM_HS SG_ 201 CrsCntAtv 250;
BA_REL_ "GenSigTimeoutMsg" BU_SG_REL_ CGM_HS SG_ 201 CrsCntAtv 201;
BA_REL_ "GenSigSuprvResp" BU_SG_REL_ CGM_HS SG_ 201 CrsCntAtv 1;
BA_REL_ "GenSigTimeoutTime" BU_SG_REL_ TCM_HS SG_ 201 CrsCntAtv 31;
BA_REL_ "GenSigTimeoutMsg" BU_SG_REL_ TCM_HS SG_ 201 CrsCntAtv 201;
BA_REL_ "GenSigSuprvResp" BU_SG_REL_ TCM_HS SG_ 201 CrsCntAtv 1;
BA_REL_ "GenSigTimeoutTime" BU_SG_REL_ CGM_HS SG_ 201 DrvThrottlOvrrdDet 250;
BA_REL_ "GenSigTimeoutMsg" BU_SG_REL_ CGM_HS SG_ 201 DrvThrottlOvrrdDet 201;
BA_REL_ "GenSigSuprvResp" BU_SG_REL_ CGM_HS SG_ 201 DrvThrottlOvrrdDet 1;
BA_REL_ "GenSigTimeoutTime" BU_SG_REL_ EBCM_OBD_HS SG_ 201 PT_CrnkAct 250;
BA_REL_ "GenSigTimeoutMsg" BU_SG_REL_ EBCM_OBD_HS SG_ 201 PT_CrnkAct 201;
BA_REL_ "GenSigSuprvResp" BU_SG_REL_ EBCM_OBD_HS SG_ 201 PT_CrnkAct 1;
BA_REL_ "GenSigTimeoutTime" BU_SG_REL_ EPS_HS SG_ 201 PT_CrnkAct 250;
BA_REL_ "GenSigTimeoutMsg" BU_SG_REL_ EPS_HS SG_ 201 PT_CrnkAct 201;
BA_REL_ "GenSigSuprvResp" BU_SG_REL_ EPS_HS SG_ 201 PT_CrnkAct 1;
BA_REL_ "GenSigTimeoutTime" BU_SG_REL_ EBCM_HS SG_ 201 PT_CrnkAct 250;
BA_REL_ "GenSigTimeoutMsg" BU_SG_REL_ EBCM_HS SG_ 201 PT_CrnkAct 201;
BA_REL_ "GenSigSuprvResp" BU_SG_REL_ EBCM_HS SG_ 201 PT_CrnkAct 1;
BA_REL_ "GenSigTimeoutTime" BU_SG_REL_ BCM_HS SG_ 201 PTRunAbrt 50;
BA_REL_ "GenSigTimeoutMsg" BU_SG_REL_ BCM_HS SG_ 201 PTRunAbrt 201;
BA_REL_ "GenSigSuprvRespSubValue" BU_SG_REL_ BCM_HS SG_ 201 PTRunAbrt 1;
BA_REL_ "GenSigSuprvResp" BU_SG_REL_ BCM_HS SG_ 201 PTRunAbrt 2;
BA_REL_ "GenSigTimeoutTime" BU_SG_REL_ CGM_HS SG_ 201 EngSpdStat 250;
BA_REL_ "GenSigTimeoutMsg" BU_SG_REL_ CGM_HS SG_ 201 EngSpdStat 201;
BA_REL_ "GenSigSuprvResp" BU_SG_REL_ CGM_HS SG_ 201 EngSpdStat 1;
BA_REL_ "GenSigTimeoutTime" BU_SG_REL_ EPS_HS SG_ 201 EngSpdStat 250;
BA_REL_ "GenSigTimeoutMsg" BU_SG_REL_ EPS_HS SG_ 201 EngSpdStat 201;
BA_REL_ "GenSigSuprvResp" BU_SG_REL_ EPS_HS SG_ 201 EngSpdStat 1;
BA_REL_ "GenSigTimeoutTime" BU_SG_REL_ TCM_HS SG_ 201 EngSpdStat 250;
BA_REL_ "GenSigTimeoutMsg" BU_SG_REL_ TCM_HS SG_ 201 EngSpdStat 201;
BA_REL_ "GenSigSuprvResp" BU_SG_REL_ TCM_HS SG_ 201 EngSpdStat 1;
BA_REL_ "GenSigTimeoutTime" BU_SG_REL_ CGM_HS SG_ 201 EngSpd 250;
BA_REL_ "GenSigTimeoutMsg" BU_SG_REL_ CGM_HS SG_ 201 EngSpd 201;
BA_REL_ "GenSigSuprvResp" BU_SG_REL_ CGM_HS SG_ 201 EngSpd 1;
BA_REL_ "GenSigTimeoutTime" BU_SG_REL_ EPS_HS SG_ 201 EngSpd 250;
BA_REL_ "GenSigTimeoutMsg" BU_SG_REL_ EPS_HS SG_ 201 EngSpd 201;
BA_REL_ "GenSigSuprvResp" BU_SG_REL_ EPS_HS SG_ 201 EngSpd 1;
BA_REL_ "GenSigTimeoutTime" BU_SG_REL_ BCP_HS SG_ 201 EngSpd 250;
BA_REL_ "GenSigTimeoutMsg" BU_SG_REL_ BCP_HS SG_ 201 EngSpd 201;
BA_REL_ "GenSigSuprvResp" BU_SG_REL_ BCP_HS SG_ 201 EngSpd 1;
BA_REL_ "GenSigTimeoutTime" BU_SG_REL_ EPB_HS SG_ 201 EngSpd 250;
BA_REL_ "GenSigTimeoutMsg" BU_SG_REL_ EPB_HS SG_ 201 EngSpd 201;
BA_REL_ "GenSigSuprvResp" BU_SG_REL_ EPB_HS SG_ 201 EngSpd 1;
BA_REL_ "GenSigTimeoutTime" BU_SG_REL_ BCM_HS SG_ 201 EngSpd 250;
BA_REL_ "GenSigTimeoutMsg" BU_SG_REL_ BCM_HS SG_ 201 EngSpd 201;
BA_REL_ "GenSigSuprvResp" BU_SG_REL_ BCM_HS SG_ 201 EngSpd 1;
BA_REL_ "GenSigTimeoutTime" BU_SG_REL_ CGM_HS SG_ 201 EngRunAtv 250;
BA_REL_ "GenSigTimeoutMsg" BU_SG_REL_ CGM_HS SG_ 201 EngRunAtv 201;
BA_REL_ "GenSigSuprvResp" BU_SG_REL_ CGM_HS SG_ 201 EngRunAtv 1;
BA_REL_ "GenSigTimeoutTime" BU_SG_REL_ ICCM_OBD_HS SG_ 201 EngRunAtv 250;
BA_REL_ "GenSigTimeoutMsg" BU_SG_REL_ ICCM_OBD_HS SG_ 201 EngRunAtv 201;
BA_REL_ "GenSigSuprvResp" BU_SG_REL_ ICCM_OBD_HS SG_ 201 EngRunAtv 1;
BA_REL_ "GenSigTimeoutTime" BU_SG_REL_ ICCM_HS SG_ 201 EngRunAtv 250;
BA_REL_ "GenSigTimeoutMsg" BU_SG_REL_ ICCM_HS SG_ 201 EngRunAtv 201;
BA_REL_ "GenSigSuprvResp" BU_SG_REL_ ICCM_HS SG_ 201 EngRunAtv 1;
BA_REL_ "GenSigTimeoutTime" BU_SG_REL_ EPS_HS SG_ 201 EngRunAtv 250;
BA_REL_ "GenSigTimeoutMsg" BU_SG_REL_ EPS_HS SG_ 201 EngRunAtv 201;
BA_REL_ "GenSigSuprvResp" BU_SG_REL_ EPS_HS SG_ 201 EngRunAtv 1;
BA_REL_ "GenSigTimeoutTime" BU_SG_REL_ TCCM_HS SG_ 201 EngRunAtv 32;
BA_REL_ "GenSigTimeoutMsg" BU_SG_REL_ TCCM_HS SG_ 201 EngRunAtv 201;
BA_REL_ "GenSigSuprvResp" BU_SG_REL_ TCCM_HS SG_ 201 EngRunAtv 1;
BA_REL_ "GenSigTimeoutTime" BU_SG_REL_ BCM_HS SG_ 201 EngRunAtv 250;
BA_REL_ "GenSigTimeoutMsg" BU_SG_REL_ BCM_HS SG_ 201 EngRunAtv 201;
BA_REL_ "GenSigSuprvResp" BU_SG_REL_ BCM_HS SG_ 201 EngRunAtv 1;
BA_REL_ "GenSigTimeoutTime" BU_SG_REL_ CGM_HS SG_ 201 EngIdlAtv 250;
BA_REL_ "GenSigTimeoutMsg" BU_SG_REL_ CGM_HS SG_ 201 EngIdlAtv 201;
BA_REL_ "GenSigSuprvResp" BU_SG_REL_ CGM_HS SG_ 201 EngIdlAtv 1;
BA_REL_ "GenSigTimeoutTime" BU_SG_REL_ BCM_HS SG_ 501 TmpDrvrShftCtlAct 250;
BA_REL_ "GenSigTimeoutMsg" BU_SG_REL_ BCM_HS SG_ 501 TmpDrvrShftCtlAct 501;
BA_REL_ "GenSigSuprvResp" BU_SG_REL_ BCM_HS SG_ 501 TmpDrvrShftCtlAct 1;
BA_REL_ "GenSigTimeoutTime" BU_SG_REL_ TCCM_HS SG_ 501 CltStartSwAtv 250;
BA_REL_ "GenSigTimeoutMsg" BU_SG_REL_ TCCM_HS SG_ 501 CltStartSwAtv 501;
BA_REL_ "GenSigSuprvResp" BU_SG_REL_ TCCM_HS SG_ 501 CltStartSwAtv 1;
BA_REL_ "GenSigTimeoutTime" BU_SG_REL_ BCM_HS SG_ 501 CltStartSwAtv 250;
BA_REL_ "GenSigTimeoutMsg" BU_SG_REL_ BCM_HS SG_ 501 CltStartSwAtv 501;
BA_REL_ "GenSigVBitResp" BU_SG_REL_ BCM_HS SG_ 501 CltStartSwAtv 1;
BA_REL_ "GenSigSuprvResp" BU_SG_REL_ BCM_HS SG_ 501 CltStartSwAtv 1;
BA_REL_ "GenSigTimeoutTime" BU_SG_REL_ EBCM_OBD_HS SG_ 501 CltchPdlActPos 250;
BA_REL_ "GenSigTimeoutMsg" BU_SG_REL_ EBCM_OBD_HS SG_ 501 CltchPdlActPos 501;
BA_REL_ "GenSigSuprvResp" BU_SG_REL_ EBCM_OBD_HS SG_ 501 CltchPdlActPos 1;
BA_REL_ "GenSigTimeoutTime" BU_SG_REL_ EPB_HS SG_ 501 CltchPdlActPos 250;
BA_REL_ "GenSigTimeoutMsg" BU_SG_REL_ EPB_HS SG_ 501 CltchPdlActPos 501;
BA_REL_ "GenSigSuprvResp" BU_SG_REL_ EPB_HS SG_ 501 CltchPdlActPos 1;
BA_REL_ "GenSigTimeoutTime" BU_SG_REL_ TCCM_HS SG_ 501 CltchPdlActPos 250;
BA_REL_ "GenSigTimeoutMsg" BU_SG_REL_ TCCM_HS SG_ 501 CltchPdlActPos 501;
BA_REL_ "GenSigSuprvResp" BU_SG_REL_ TCCM_HS SG_ 501 CltchPdlActPos 1;
BA_REL_ "GenSigTimeoutTime" BU_SG_REL_ EBCM_HS SG_ 501 CltchPdlActPos 250;
BA_REL_ "GenSigTimeoutMsg" BU_SG_REL_ EBCM_HS SG_ 501 CltchPdlActPos 501;
BA_REL_ "GenSigSuprvResp" BU_SG_REL_ EBCM_HS SG_ 501 CltchPdlActPos 1;
BA_REL_ "GenSigTimeoutTime" BU_SG_REL_ BCM_HS SG_ 501 TrnsEngdState 250;
BA_REL_ "GenSigTimeoutMsg" BU_SG_REL_ BCM_HS SG_ 501 TrnsEngdState 501;
BA_REL_ "GenSigVBitResp" BU_SG_REL_ BCM_HS SG_ 501 TrnsEngdState 1;
BA_REL_ "GenSigSuprvResp" BU_SG_REL_ BCM_HS SG_ 501 TrnsEngdState 1;
BA_REL_ "GenSigTimeoutTime" BU_SG_REL_ EBCM_OBD_HS SG_ 501 TransTUDMdStat 250;
BA_REL_ "GenSigTimeoutMsg" BU_SG_REL_ EBCM_OBD_HS SG_ 501 TransTUDMdStat 501;
BA_REL_ "GenSigSuprvResp" BU_SG_REL_ EBCM_OBD_HS SG_ 501 TransTUDMdStat 1;
BA_REL_ "GenSigTimeoutTime" BU_SG_REL_ BCM_HS SG_ 501 TransTUDMdStat 250;
BA_REL_ "GenSigTimeoutMsg" BU_SG_REL_ BCM_HS SG_ 501 TransTUDMdStat 501;
BA_REL_ "GenSigSuprvResp" BU_SG_REL_ BCM_HS SG_ 501 TransTUDMdStat 1;
BA_REL_ "GenSigTimeoutTime" BU_SG_REL_ EBCM_HS SG_ 501 TransTUDMdStat 250;
BA_REL_ "GenSigTimeoutMsg" BU_SG_REL_ EBCM_HS SG_ 501 TransTUDMdStat 501;
BA_REL_ "GenSigSuprvResp" BU_SG_REL_ EBCM_HS SG_ 501 TransTUDMdStat 1;
BA_REL_ "GenSigTimeoutTime" BU_SG_REL_ EBCM_OBD_HS SG_ 501 TrnsSftMdStat 250;
BA_REL_ "GenSigTimeoutMsg" BU_SG_REL_ EBCM_OBD_HS SG_ 501 TrnsSftMdStat 501;
BA_REL_ "GenSigSuprvResp" BU_SG_REL_ EBCM_OBD_HS SG_ 501 TrnsSftMdStat 1;
BA_REL_ "GenSigTimeoutTime" BU_SG_REL_ EBCM_HS SG_ 501 TrnsSftMdStat 250;
BA_REL_ "GenSigTimeoutMsg" BU_SG_REL_ EBCM_HS SG_ 501 TrnsSftMdStat 501;
BA_REL_ "GenSigSuprvResp" BU_SG_REL_ EBCM_HS SG_ 501 TrnsSftMdStat 1;
BA_REL_ "GenSigTimeoutTime" BU_SG_REL_ BCM_HS SG_ 501 TopTrvlCltchSwAct 250;
BA_REL_ "GenSigTimeoutMsg" BU_SG_REL_ BCM_HS SG_ 501 TopTrvlCltchSwAct 501;
BA_REL_ "GenSigVBitResp" BU_SG_REL_ BCM_HS SG_ 501 TopTrvlCltchSwAct 1;
BA_REL_ "GenSigSuprvResp" BU_SG_REL_ BCM_HS SG_ 501 TopTrvlCltchSwAct 1;
BA_REL_ "GenSigTimeoutTime" BU_SG_REL_ EPS_HS SG_ 501 TrnsShftLvrPos 250;
BA_REL_ "GenSigTimeoutMsg" BU_SG_REL_ EPS_HS SG_ 501 TrnsShftLvrPos 501;
BA_REL_ "GenSigSuprvResp" BU_SG_REL_ EPS_HS SG_ 501 TrnsShftLvrPos 1;
BA_REL_ "GenSigTimeoutTime" BU_SG_REL_ EBCM_OBD_HS SG_ 501 TrnsShftLvrPos 250;
BA_REL_ "GenSigTimeoutMsg" BU_SG_REL_ EBCM_OBD_HS SG_ 501 TrnsShftLvrPos 501;
BA_REL_ "GenSigSuprvResp" BU_SG_REL_ EBCM_OBD_HS SG_ 501 TrnsShftLvrPos 1;
BA_REL_ "GenSigTimeoutTime" BU_SG_REL_ BCM_HS SG_ 501 TrnsShftLvrPos 250;
BA_REL_ "GenSigTimeoutMsg" BU_SG_REL_ BCM_HS SG_ 501 TrnsShftLvrPos 501;
BA_REL_ "GenSigVBitResp" BU_SG_REL_ BCM_HS SG_ 501 TrnsShftLvrPos 1;
BA_REL_ "GenSigSuprvResp" BU_SG_REL_ BCM_HS SG_ 501 TrnsShftLvrPos 1;
BA_REL_ "GenSigTimeoutTime" BU_SG_REL_ EBCM_HS SG_ 501 TrnsShftLvrPos 250;
BA_REL_ "GenSigTimeoutMsg" BU_SG_REL_ EBCM_HS SG_ 501 TrnsShftLvrPos 501;
BA_REL_ "GenSigSuprvResp" BU_SG_REL_ EBCM_HS SG_ 501 TrnsShftLvrPos 1;
BA_REL_ "GenSigTimeoutTime" BU_SG_REL_ ECM_HS SG_ 501 TrnsTrqCnvCltCmndMd 62;
BA_REL_ "GenSigTimeoutMsg" BU_SG_REL_ ECM_HS SG_ 501 TrnsTrqCnvCltCmndMd 501;
BA_REL_ "GenSigSuprvResp" BU_SG_REL_ ECM_HS SG_ 501 TrnsTrqCnvCltCmndMd 1;
BA_REL_ "GenSigTimeoutTime" BU_SG_REL_ BCM_HS SG_ 501 AutoTransComndGear 250;
BA_REL_ "GenSigTimeoutMsg" BU_SG_REL_ BCM_HS SG_ 501 AutoTransComndGear 501;
BA_REL_ "GenSigSuprvResp" BU_SG_REL_ BCM_HS SG_ 501 AutoTransComndGear 1;
BA_REL_ "GenSigTimeoutTime" BU_SG_REL_ ECM_HS SG_ 501 AutoTransComndGear 62;
BA_REL_ "GenSigTimeoutMsg" BU_SG_REL_ ECM_HS SG_ 501 AutoTransComndGear 501;
BA_REL_ "GenSigSuprvResp" BU_SG_REL_ ECM_HS SG_ 501 AutoTransComndGear 1;
BA_REL_ "GenSigTimeoutTime" BU_SG_REL_ ICCM_OBD_HS SG_ 501 AutoTransGrSftDirect 250;
BA_REL_ "GenSigTimeoutMsg" BU_SG_REL_ ICCM_OBD_HS SG_ 501 AutoTransGrSftDirect 501;
BA_REL_ "GenSigSuprvResp" BU_SG_REL_ ICCM_OBD_HS SG_ 501 AutoTransGrSftDirect 1;
BA_REL_ "GenSigTimeoutTime" BU_SG_REL_ ICCM_HS SG_ 501 AutoTransGrSftDirect 250;
BA_REL_ "GenSigTimeoutMsg" BU_SG_REL_ ICCM_HS SG_ 501 AutoTransGrSftDirect 501;
BA_REL_ "GenSigSuprvResp" BU_SG_REL_ ICCM_HS SG_ 501 AutoTransGrSftDirect 1;
BA_REL_ "GenSigTimeoutTime" BU_SG_REL_ HMIM_HS SG_ 501 TransEstGear 250;
BA_REL_ "GenSigTimeoutMsg" BU_SG_REL_ HMIM_HS SG_ 501 TransEstGear 501;
BA_REL_ "GenSigSuprvResp" BU_SG_REL_ HMIM_HS SG_ 501 TransEstGear 1;
BA_REL_ "GenSigTimeoutTime" BU_SG_REL_ ONSTAR_HS SG_ 501 TransEstGear 250;
BA_REL_ "GenSigTimeoutMsg" BU_SG_REL_ ONSTAR_HS SG_ 501 TransEstGear 501;
BA_REL_ "GenSigVBitResp" BU_SG_REL_ ONSTAR_HS SG_ 501 TransEstGear 1;
BA_REL_ "GenSigSuprvResp" BU_SG_REL_ ONSTAR_HS SG_ 501 TransEstGear 1;
BA_REL_ "GenSigTimeoutTime" BU_SG_REL_ TCCM_HS SG_ 501 TransEstGear 63;
BA_REL_ "GenSigTimeoutMsg" BU_SG_REL_ TCCM_HS SG_ 501 TransEstGear 501;
BA_REL_ "GenSigSuprvResp" BU_SG_REL_ TCCM_HS SG_ 501 TransEstGear 1;
BA_REL_ "GenSigTimeoutTime" BU_SG_REL_ BCM_HS SG_ 501 TransEstGear 250;
BA_REL_ "GenSigTimeoutMsg" BU_SG_REL_ BCM_HS SG_ 501 TransEstGear 501;
BA_REL_ "GenSigVBitResp" BU_SG_REL_ BCM_HS SG_ 501 TransEstGear 1;
BA_REL_ "GenSigSuprvResp" BU_SG_REL_ BCM_HS SG_ 501 TransEstGear 1;
BA_REL_ "GenSigTimeoutTime" BU_SG_REL_ BCM_HS SG_ 1225 TCTPIR_TnsEsClCDwT 1250;
BA_REL_ "GenSigTimeoutMsg" BU_SG_REL_ BCM_HS SG_ 1225 TCTPIR_TnsEsClCDwT 1225;
BA_REL_ "GenSigSuprvResp" BU_SG_REL_ BCM_HS SG_ 1225 TCTPIR_TnsEsClCDwT 1;
BA_REL_ "GenSigTimeoutTime" BU_SG_REL_ BCM_HS SG_ 1225 TCTPIR_TnsEsClTmpD 1250;
BA_REL_ "GenSigTimeoutMsg" BU_SG_REL_ BCM_HS SG_ 1225 TCTPIR_TnsEsClTmpD 1225;
BA_REL_ "GenSigSuprvResp" BU_SG_REL_ BCM_HS SG_ 1225 TCTPIR_TnsEsClTmpD 1;
BA_REL_ "GenSigTimeoutTime" BU_SG_REL_ BCM_HS SG_ 1225 TCTPIR_DrvNotfn 1250;
BA_REL_ "GenSigTimeoutMsg" BU_SG_REL_ BCM_HS SG_ 1225 TCTPIR_DrvNotfn 1225;
BA_REL_ "GenSigSuprvResp" BU_SG_REL_ BCM_HS SG_ 1225 TCTPIR_DrvNotfn 1;
BA_REL_ "GenSigTimeoutTime" BU_SG_REL_ BCM_HS SG_ 1225 GrdBrkgAct 1250;
BA_REL_ "GenSigTimeoutMsg" BU_SG_REL_ BCM_HS SG_ 1225 GrdBrkgAct 1225;
BA_REL_ "GenSigSuprvResp" BU_SG_REL_ BCM_HS SG_ 1225 GrdBrkgAct 1;
BA_REL_ "GenSigTimeoutTime" BU_SG_REL_ ICCM_OBD_HS SG_ 1225 RrPTCoolFanRatFltStat 1250;
BA_REL_ "GenSigTimeoutMsg" BU_SG_REL_ ICCM_OBD_HS SG_ 1225 RrPTCoolFanRatFltStat 1225;
BA_REL_ "GenSigSuprvResp" BU_SG_REL_ ICCM_OBD_HS SG_ 1225 RrPTCoolFanRatFltStat 1;
BA_REL_ "GenSigTimeoutTime" BU_SG_REL_ ICCM_HS SG_ 1225 RrPTCoolFanRatFltStat 1250;
BA_REL_ "GenSigTimeoutMsg" BU_SG_REL_ ICCM_HS SG_ 1225 RrPTCoolFanRatFltStat 1225;
BA_REL_ "GenSigSuprvResp" BU_SG_REL_ ICCM_HS SG_ 1225 RrPTCoolFanRatFltStat 1;
BA_REL_ "GenSigTimeoutTime" BU_SG_REL_ TCCM_HS SG_ 1225 TrnOilTmp 1250;
BA_REL_ "GenSigTimeoutMsg" BU_SG_REL_ TCCM_HS SG_ 1225 TrnOilTmp 1225;
BA_REL_ "GenSigSuprvResp" BU_SG_REL_ TCCM_HS SG_ 1225 TrnOilTmp 1;
BA_REL_ "GenSigTimeoutTime" BU_SG_REL_ BCM_HS SG_ 1225 TrnOilTmp 1250;
BA_REL_ "GenSigTimeoutMsg" BU_SG_REL_ BCM_HS SG_ 1225 TrnOilTmp 1225;
BA_REL_ "GenSigVBitResp" BU_SG_REL_ BCM_HS SG_ 1225 TrnOilTmp 1;
BA_REL_ "GenSigSuprvResp" BU_SG_REL_ BCM_HS SG_ 1225 TrnOilTmp 1;
BA_REL_ "GenSigTimeoutTime" BU_SG_REL_ EBCM_OBD_HS SG_ 249 TrnsRqHSABrkPrDcyRt 250;
BA_REL_ "GenSigTimeoutMsg" BU_SG_REL_ EBCM_OBD_HS SG_ 249 TrnsRqHSABrkPrDcyRt 249;
BA_REL_ "GenSigSuprvResp" BU_SG_REL_ EBCM_OBD_HS SG_ 249 TrnsRqHSABrkPrDcyRt 1;
BA_REL_ "GenSigTimeoutTime" BU_SG_REL_ EBCM_HS SG_ 249 TrnsRqHSABrkPrDcyRt 250;
BA_REL_ "GenSigTimeoutMsg" BU_SG_REL_ EBCM_HS SG_ 249 TrnsRqHSABrkPrDcyRt 249;
BA_REL_ "GenSigSuprvResp" BU_SG_REL_ EBCM_HS SG_ 249 TrnsRqHSABrkPrDcyRt 1;
BA_REL_ "GenSigTimeoutTime" BU_SG_REL_ EBCM_OBD_HS SG_ 249 TrnsOtptRotRC 250;
BA_REL_ "GenSigTimeoutMsg" BU_SG_REL_ EBCM_OBD_HS SG_ 249 TrnsOtptRotRC 249;
BA_REL_ "GenSigSuprvResp" BU_SG_REL_ EBCM_OBD_HS SG_ 249 TrnsOtptRotRC 1;
BA_REL_ "GenSigTimeoutTime" BU_SG_REL_ EBCM_HS SG_ 249 TrnsOtptRotRC 250;
BA_REL_ "GenSigTimeoutMsg" BU_SG_REL_ EBCM_HS SG_ 249 TrnsOtptRotRC 249;
BA_REL_ "GenSigSuprvResp" BU_SG_REL_ EBCM_HS SG_ 249 TrnsOtptRotRC 1;
BA_REL_ "GenSigTimeoutTime" BU_SG_REL_ EBCM_OBD_HS SG_ 249 TrnsOtptRotRCRstOcc 250;
BA_REL_ "GenSigTimeoutMsg" BU_SG_REL_ EBCM_OBD_HS SG_ 249 TrnsOtptRotRCRstOcc 249;
BA_REL_ "GenSigSuprvResp" BU_SG_REL_ EBCM_OBD_HS SG_ 249 TrnsOtptRotRCRstOcc 1;
BA_REL_ "GenSigTimeoutTime" BU_SG_REL_ EBCM_HS SG_ 249 TrnsOtptRotRCRstOcc 250;
BA_REL_ "GenSigTimeoutMsg" BU_SG_REL_ EBCM_HS SG_ 249 TrnsOtptRotRCRstOcc 249;
BA_REL_ "GenSigSuprvResp" BU_SG_REL_ EBCM_HS SG_ 249 TrnsOtptRotRCRstOcc 1;
BA_REL_ "GenSigTimeoutTime" BU_SG_REL_ EBCM_OBD_HS SG_ 249 TrnsOutShftAngVel 250;
BA_REL_ "GenSigTimeoutMsg" BU_SG_REL_ EBCM_OBD_HS SG_ 249 TrnsOutShftAngVel 249;
BA_REL_ "GenSigSuprvResp" BU_SG_REL_ EBCM_OBD_HS SG_ 249 TrnsOutShftAngVel 1;
BA_REL_ "GenSigTimeoutTime" BU_SG_REL_ TCCM_HS SG_ 249 TrnsOutShftAngVel 250;
BA_REL_ "GenSigTimeoutMsg" BU_SG_REL_ TCCM_HS SG_ 249 TrnsOutShftAngVel 249;
BA_REL_ "GenSigSuprvResp" BU_SG_REL_ TCCM_HS SG_ 249 TrnsOutShftAngVel 1;
BA_REL_ "GenSigTimeoutTime" BU_SG_REL_ EBCM_HS SG_ 249 TrnsOutShftAngVel 250;
BA_REL_ "GenSigTimeoutMsg" BU_SG_REL_ EBCM_HS SG_ 249 TrnsOutShftAngVel 249;
BA_REL_ "GenSigSuprvResp" BU_SG_REL_ EBCM_HS SG_ 249 TrnsOutShftAngVel 1;
VAL_ 463 FourWhlDrvIndReq 0 "No Indication" 1 "Indication 1" 2 "Indication 2" 3 "Indication 3" 4 "Indication 4" 5 "Indication 5" 6 "Indication 6" 7 "Indication 7" ;
VAL_ 463 SecAxlNonEmMalfIO 1 "true" 0 "false" ;
VAL_ 463 SecAxlOperMod 3 "Active All Wheel Drive (High)" 2 "4 Wheel Drive Low Locked" 1 "4 Wheel Drive High Locked" 0 "2 Wheel Drive High" 15 "Neutral" 14 "Unknown" 7 "2 Wheel Drive Low" 6 "Active All Wheel Drive (Low)" 5 "4 Wheel Drive Low Open" 4 "4 Wheel Drive High Open" ;
VAL_ 463 SecAxlTmpInhIO 1 "true" 0 "false" ;
VAL_ 953 DslGlwTypReqd 0 "Cold Start" 1 "Intermediate" 2 "Diesel Particulate Filter Cleaning" ;
VAL_ 953 RdctHtrCReq 0 "Off" 1 "On" ;
VAL_ 953 RdctHtrBReq 0 "Off" 1 "On" ;
VAL_ 953 RdctHtrAReq 0 "Off" 1 "On" ;
VAL_ 953 EngPwrCnfg 15 "Configuration 15" 14 "Configuration 14" 13 "Configuration 13" 12 "Configuration 12" 11 "Configuration 11" 10 "Configuration 10" 9 "Configuration 9" 8 "Configuration 8" 7 "Configuration 7" 6 "Configuration 6" 5 "Configuration 5" 4 "Configuration 4" 3 "Configuration 3" 2 "Configuration 2" 1 "Configuration 1" 0 "Default" ;
VAL_ 953 EngCntlSenPTRlyVltM 1 "Use Data" 0 "Don't Use Data" ;
VAL_ 953 CrntFlConsmpV 1 "Invalid" 0 "Valid" ;
VAL_ 953 DslPartFltrClngAlgActM 1 "Use Data" 0 "Don't Use Data" ;
VAL_ 953 DslPartFltrClngAlgAct 1 "true" 0 "false" ;
VAL_ 953 MassAirFloV 1 "Invalid" 0 "Valid" ;
VAL_ 953 GlwPlgReqdOn 1 "true" 0 "false" ;
VAL_ 1011 BatVltHiResV 1 "Invalid" 0 "Valid" ;
VAL_ 1011 BatCrntExtRngV 1 "Invalid" 0 "Valid" ;
VAL_ 1011 BatSnsrlntFlt 1 "true" 0 "false" ;
VAL_ 1011 BatCrntExtRngM 1 "Use Data" 0 "Don't Use Data" ;
VAL_ 1011 BatVltHiResM 1 "Use Data" 0 "Don't Use Data" ;
VAL_ 490 SrvcFlSysPrkInOpnArIO 1 "true" 0 "false" ;
VAL_ 490 FuelSysNEmsRltMalfAct 1 "true" 0 "false" ;
VAL_ 490 InActFuelMdFuelLvlIO 1 "true" 0 "false" ;
VAL_ 490 FlLvlTank2PctV 1 "Invalid" 0 "Valid" ;
VAL_ 490 AltFuelPHeatAct 1 "true" 0 "false" ;
VAL_ 490 AltFuelMdReqDndIO 1 "true" 0 "false" ;
VAL_ 490 AltFuelLvlLo 1 "true" 0 "false" ;
VAL_ 490 AltFuelAccWrnngAct 1 "true" 0 "false" ;
VAL_ 490 FuelMdStat 3 "Alternative Fuel Cut-off Active" 2 "Liquified Petroleum Gas Mode" 1 "Natural Gas Mode" 0 "Gasoline Mode" ;
VAL_ 453 DrvIntndAxlTrqV 1 "Invalid" 0 "Valid" ;
VAL_ 453 DrvIntndAxlTrqMinV 1 "Invalid" 0 "Valid" ;
VAL_ 453 DrvIntndAxlTrqMaxV 1 "Invalid" 0 "Valid" ;
VAL_ 452 FSpRgACCSwADd 1 "true" 0 "false" ;
VAL_ 452 ABAAPS_AccPosV 1 "Invalid" 0 "Valid" ;
VAL_ 452 ACCATCS_LmtgStat 3 "Request Rate Limited" 2 "Request Value Limited Maximum" 1 "Request Value Limited Minimum" 0 "Request Not Limited" ;
VAL_ 452 ACCATCS_RqStat 4 "Request Suspended Till Driver Input" 3 "Request Denied" 2 "Lost Arbitration" 1 "Request Honored" 0 "No Request" ;
VAL_ 452 AccPdlOvrrdAtv 1 "true" 0 "false" ;
VAL_ 452 CPSATCS_ReqStatus 0 "No Request" 1 "Request Honored" 2 "Lost Arbitration" 3 "Serial Data Failure Temporary" 4 "Serial Data Failure Permanent" 5 "Control System Failure Temporary" 6 "Control System Failure Permanent" ;
VAL_ 452 CPSATCS_LmtngStatus 0 "Request Not Limited" 1 "Request Value Limited to Minimum" 2 "Request Value Limited to Maximum" 3 "Request Rate Limited" ;
VAL_ 452 RVBATCS_ReqStat 0 "No Request" 1 "Request Honored" 2 "Lost Arbitration" 3 "Serial Data Failure Temporary" 4 "Serial Data Failure Permanent" 5 "Control System Failure Temporary" 6 "Control System Failure Permanent" ;
VAL_ 452 RVBATCS_LmtngStat 0 "Request Not Limited" 1 "Request Value Limited to Minimum" 2 "Request Value Limited to Maximum" 3 "Request Rate Limited" ;
VAL_ 190 TrnsAuxPmpAct 1 "true" 0 "false" ;
VAL_ 190 PSBPI_PTSnBrkPdlPsV 1 "Invalid" 0 "Valid" ;
VAL_ 451 HillDscntCtrlSwStat 0 "No Activation" 1 "Increment" 2 "Decrement" 3 "Faulted" ;
VAL_ 451 GlwPlgCrnkDelAct 1 "true" 0 "false" ;
VAL_ 451 AuxHtrAlwd 1 "true" 0 "false" ;
VAL_ 451 AppCltchAutSrtIO 1 "true" 0 "false" ;
VAL_ 451 AccPosV 1 "Invalid" 0 "Valid" ;
VAL_ 451 EngTrqRdFlrSt 4 "Torq Reduction Communication Failed" 3 "Torque Reduction Limited" 2 "Torque Reduction Permanently Failed" 1 "Torque Reduction Temporarily Failed" 0 "Torque Reduction OK" ;
VAL_ 451 EngTrqDrRqdExtRngV 1 "Invalid" 0 "Valid" ;
VAL_ 451 EngTrqActExtRngV 1 "Invalid" 0 "Valid" ;
VAL_ 495 MassAirFloV 1 "Invalid" 0 "Valid" ;
VAL_ 1906 DTCI_DTCFaultType_772 3 "Type C" 2 "Type B" 1 "Type A" 0 "Not Supported" ;
VAL_ 1906 DTCI_CodeSupported_772 1 "true" 0 "false" ;
VAL_ 1906 DTCI_CurrentStatus_772 1 "true" 0 "false" ;
VAL_ 1906 DTCI_TstNPsdCdClrdSt_772 1 "true" 0 "false" ;
VAL_ 1906 DTCI_TstFldCdClrdStat_772 1 "true" 0 "false" ;
VAL_ 1906 DTCI_HistStat_772 1 "true" 0 "false" ;
VAL_ 1906 DTCI_TstNPsdPwrUpSt_772 1 "true" 0 "false" ;
VAL_ 1906 DTCI_TstFldPwrUpSt_772 1 "true" 0 "false" ;
VAL_ 1906 DTCI_WrnIndRqdSt_772 1 "true" 0 "false" ;
VAL_ 1906 DTCI_DTCTriggered_772 1 "true" 0 "false" ;
VAL_ 1906 DTCIUnused7_772 1 "true" 0 "false" ;
VAL_ 1906 DTCIUnused6_772 1 "true" 0 "false" ;
VAL_ 1906 DTCIUnused5_772 1 "true" 0 "false" ;
VAL_ 1906 DTCIUnused4_772 1 "true" 0 "false" ;
VAL_ 1906 DTCIUnused3_772 1 "true" 0 "false" ;
VAL_ 1906 DTCIUnused2_772 1 "true" 0 "false" ;
VAL_ 1906 DTCIUnused1_772 1 "true" 0 "false" ;
VAL_ 1001 DistRollCntAvgDrvnSrc 1 "Wheel Speed" 0 "Transmission Output Speed" ;
VAL_ 1001 VehSpdAvgDrvnSrc 1 "Wheel Speed" 0 "Transmission Output Speed" ;
VAL_ 1001 DstRolCntAvgNonDrvnV 1 "Invalid" 0 "Valid" ;
VAL_ 1001 DstRolCntAvNDrRstOc 1 "true" 0 "false" ;
VAL_ 1001 DistRollCntAvgDrvnV 1 "Invalid" 0 "Valid" ;
VAL_ 1001 DstRolCntAvgDrnRstOc 1 "true" 0 "false" ;
VAL_ 1001 VehSpdAvgNDrvnV 1 "Invalid" 0 "Valid" ;
VAL_ 1001 VehSpdAvgDrvnV 1 "Invalid" 0 "Valid" ;
VAL_ 1019 FuelAlchlCompAdptnPrg 1 "true" 0 "false" ;
VAL_ 1019 FuelLvlEmnsRelStat 0 "Valid" 1 "Invalid" ;
VAL_ 1019 EmnsRelFuelLvlLw 1 "true" 0 "false" ;
VAL_ 1019 EngFuelCntlState 2 "Stoichiometric Closed Loop" 1 "Non-Stoichiometric Closed Loop" 0 "Open Loop" ;
VAL_ 1019 FuelAlcoholCompV 1 "Invalid" 0 "Valid" ;
VAL_ 493 EngRunng 1 "true" 0 "false" ;
VAL_ 493 FlPmpEDscOtptCmdSta 1 "Fuel Pump Enabled" 0 "Fuel Pump Disabled" ;
VAL_ 493 FuelCntlSysFltPrsnt 1 "true" 0 "false" ;
VAL_ 401 EngTrqTrnRqTmpFld 1 "true" 0 "false" ;
VAL_ 401 EngTrqTrnRqLmtd 1 "true" 0 "false" ;
VAL_ 401 TrnsEngSpdReqFld 1 "true" 0 "false" ;
VAL_ 401 EngTrqTnsRqFld 1 "true" 0 "false" ;
VAL_ 401 EngTrqRdnFld 1 "true" 0 "false" ;
VAL_ 401 EngNTrnsRegStdyStTqV 1 "Invalid" 0 "Valid" ;
VAL_ 401 EngAirflwStdyStTorqV 1 "Invalid" 0 "Valid" ;
VAL_ 401 AccKdwnAtv 1 "true" 0 "false" ;
VAL_ 401 AccPosV 1 "Invalid" 0 "Valid" ;
VAL_ 401 EngActStdyStTorqV 1 "Invalid" 0 "Valid" ;
VAL_ 707 CSTATRS_ReqStat 6 "Control System Failure Permanent" 5 "Control System Failure Temporary" 4 "Serial Data Failure Permanent" 3 "Serial Data Failure Temporary" 2 "Lost Arbitration" 1 "Request Honored" 0 "No Request" ;
VAL_ 707 CSTATRS_LmtgStat 3 "Rate and Value Limited" 2 "Value Limited" 1 "Rate Limited" 0 "Not Limited" ;
VAL_ 707 EngManfldAbsPrsV 1 "Invalid" 0 "Valid" ;
VAL_ 707 EngTrqMinExtRngV 1 "Invalid" 0 "Valid" ;
VAL_ 707 EngTrqMaxExtRngV 1 "Invalid" 0 "Valid" ;
VAL_ 1265 PTSysHzrdLghtReq 1 "true" 0 "false" ;
VAL_ 1265 EngOffTmPTV 1 "Invalid" 0 "Valid" ;
VAL_ 1265 EngOffTmPTM 1 "Use Data" 0 "Don't Use Data" ;
VAL_ 417 EngCrsCntrlMode 5 "Tap" 4 "Coast" 3 "Accel" 2 "Resume" 1 "Engaged" 0 "Inactive" ;
VAL_ 417 EngPstOxgSnsDgAstRq 1 "true" 0 "false" ;
VAL_ 417 CrsCtrlCnstSpdAct 1 "true" 0 "false" ;
VAL_ 417 WrmUpShftPtrnRq 1 "Active" 0 "Inactive" ;
VAL_ 417 EngAlwCltAdp 1 "true" 0 "false" ;
VAL_ 417 AccPdlPosPcntFullRngV 1 "Invalid" 0 "Valid" ;
VAL_ 417 DslPrtFltrIdlRgtnMdReq 1 "true" 0 "false" ;
VAL_ 417 DslPartFltrClngAlgActM 1 "Use Data" 0 "Don't Use Data" ;
VAL_ 417 DslPartFltrClngAlgAct 1 "true" 0 "false" ;
VAL_ 417 EngCylDeactMd 3 "Reactivation In Progress" 2 "Half of Total Cylinders Active" 1 "Deactivation In Progress" 0 "All Cylinders Active" ;
VAL_ 417 ACCmCltEngd 1 "true" 0 "false" ;
VAL_ 417 ParkNeutralSwStatV 1 "Invalid" 0 "Valid" ;
VAL_ 417 ParkNeutralSwStat 1 "Not Park/Neutral" 0 "Park/Neutral" ;
VAL_ 417 EngColdHiIdleActive 1 "true" 0 "false" ;
VAL_ 417 EngCyDactTqSmtAct 1 "true" 0 "false" ;
VAL_ 417 EngBrkStat 2 "Active Absorbing Torque" 1 "Active Not Absorbing Torque" 0 "Inactive" ;
VAL_ 417 TracCntlSysPwrtrnInhbt 1 "true" 0 "false" ;
VAL_ 417 EngMtlProtAtv 1 "true" 0 "false" ;
VAL_ 417 EngDgTrqCnvClUnlkRqd 1 "true" 0 "false" ;
VAL_ 417 EngCyldrDeactReqd 1 "true" 0 "false" ;
VAL_ 417 ETGRReqdGear 8 "Eighth Gear" 7 "Seventh Gear" 6 "Sixth Gear" 5 "Fifth Gear" 4 "Fourth Gear" 3 "Third Gear" 2 "Second Gear" 1 "First Gear" 0 "No Action" ;
VAL_ 417 ETGRReqType 0 "No Action" 3 "Hold Gear" 2 "Min Gear Request" 1 "Max Gear Request" ;
VAL_ 1233 a_12VBatSysUnstab 1 "true" 0 "false" ;
VAL_ 1233 EngShtdwnAct 1 "true" 0 "false" ;
VAL_ 1233 EngShtdwnPndgIO 1 "true" 0 "false" ;
VAL_ 1233 FuelFltChgNwIO 1 "true" 0 "false" ;
VAL_ 1233 PTExPrtclFltrWrn2IO 1 "true" 0 "false" ;
VAL_ 1233 PTHiElecLdReqd 1 "true" 0 "false" ;
VAL_ 1233 PTExPrtclFltrWrnIO 1 "true" 0 "false" ;
VAL_ 1233 AirCndOffIO 1 "true" 0 "false" ;
VAL_ 1233 DslGlwPlgIO 1 "true" 0 "false" ;
VAL_ 1233 RdcdPwrIO 1 "true" 0 "false" ;
VAL_ 1233 FlLvlPctV 1 "Invalid" 0 "Valid" ;
VAL_ 1233 EngWtrInFlIO 1 "true" 0 "false" ;
VAL_ 1233 EngOilTmpV 1 "Invalid" 0 "Valid" ;
VAL_ 1233 EngOilPrsV 1 "Invalid" 0 "Valid" ;
VAL_ 1233 EngOilPrsLwIO 1 "true" 0 "false" ;
VAL_ 1233 EngOilLvlLwIO 1 "true" 0 "false" ;
VAL_ 1233 EngOilChngIO 1 "true" 0 "false" ;
VAL_ 1233 EngHt_StpEngIO 1 "true" 0 "false" ;
VAL_ 1233 EngHotFuelEnrchmntIO 1 "true" 0 "false" ;
VAL_ 1233 CkFlFilrCapIO 1 "true" 0 "false" ;
VAL_ 1217 LDMinEngCltTmpRchd 1 "true" 0 "false" ;
VAL_ 1217 LegPstDTCClrDrvCyCm 1 "true" 0 "false" ;
VAL_ 1217 LegDiagColdStCndMet 1 "true" 0 "false" ;
VAL_ 1217 LegDiagColdStCndFltPr 1 "true" 0 "false" ;
VAL_ 1217 EngEconMdCmnd 1 "true" 0 "false" ;
VAL_ 1217 DslExhFldRmngDstHRsV 1 "Invalid" 0 "Valid" ;
VAL_ 1217 EngOilHotIO 1 "true" 0 "false" ;
VAL_ 1217 OAT_PT_EstV 1 "Invalid" 0 "Valid" ;
VAL_ 1217 LegDiagStndCndMet 1 "true" 0 "false" ;
VAL_ 1217 LegDiagStndCndFltPr 1 "true" 0 "false" ;
VAL_ 1217 OAT_PT_EstM 1 "Use Data" 0 "Don't Use Data" ;
VAL_ 1217 EngWrmUpAch 1 "true" 0 "false" ;
VAL_ 1217 EngIntAirTmpV 1 "Invalid" 0 "Valid" ;
VAL_ 1217 EngCltTmpV 1 "Invalid" 0 "Valid" ;
VAL_ 1217 BarPrsAbsV 1 "Invalid" 0 "Valid" ;
VAL_ 665 EngFuelCntlState_299 2 "Stoichiometric Closed Loop" 1 "Non-Stoichiometric Closed Loop" 0 "Open Loop" ;
VAL_ 665 RdGasFuelDsblAct 1 "true" 0 "false" ;
VAL_ 665 RdDistFuelMdCmd 3 "FICM" 2 "Dual" 1 "ECM" 0 "state0805" ;
VAL_ 665 PetrolFuelSysReqAval 3 "Not Available" 2 "Fault Transition Required" 1 "Fault Transition Requests" 0 "Available" ;
VAL_ 665 AltFuelSysReqAlwd 1 "true" 0 "false" ;
VAL_ 665 AltFuelInjHCmdLwRes 1 "FICM" 0 "ECM" ;
VAL_ 665 AltFuelInjGCmdLwRes 1 "FICM" 0 "ECM" ;
VAL_ 665 AltFuelInjFCmdLwRes 1 "FICM" 0 "ECM" ;
VAL_ 665 AltFuelInjECmdLwRes 1 "FICM" 0 "ECM" ;
VAL_ 665 AltFuelInjDCmdLwRes 1 "FICM" 0 "ECM" ;
VAL_ 665 AltFuelInjCCmdLwRes 1 "FICM" 0 "ECM" ;
VAL_ 665 AltFuelInjBCmdLwRes 1 "FICM" 0 "ECM" ;
VAL_ 665 AltFuelInjACmdLwRes 1 "FICM" 0 "ECM" ;
VAL_ 985 ManTransIndReq 3 "Indication 3" 2 "Indication 2" 1 "Indication 1" 0 "No Indication" ;
VAL_ 985 EngIntkArBstPrExtRngV 1 "Invalid" 0 "Valid" ;
VAL_ 985 EDADS_RcmndtFwdGr 15 "Unused and Reserved 7" 14 "Unused and Reserved 6" 13 "Unused and Reserved 5" 12 "Unused and Reserved 4" 11 "Unused and Reserved 3" 10 "Unused and Reserved 2" 9 "Unused and Reserved 1" 8 "Eighth Gear" 7 "Seventh Gear" 6 "Sixth Gear" 5 "Fifth Gear" 4 "Fourth Gear" 3 "Third Gear" 2 "Second Gear" 1 "First Gear" 0 "None" ;
VAL_ 985 EDADS_CrntFwdMsdG 15 "Unused and Reserved 7" 14 "Unused and Reserved 6" 13 "Unused and Reserved 5" 12 "Unused and Reserved 4" 11 "Unused and Reserved 3" 10 "Unused and Reserved 2" 9 "Unused and Reserved 1" 8 "Eighth Gear" 7 "Seventh Gear" 6 "Sixth Gear" 5 "Fifth Gear" 4 "Fourth Gear" 3 "Third Gear" 2 "Second Gear" 1 "First Gear" 0 "None" ;
VAL_ 985 EDADS_ShftIndStat 2 "No Shift" 1 "Shift Up" 0 "Shift Down" ;
VAL_ 985 EDADS_EcoDrvShftIO 1 "true" 0 "false" ;
VAL_ 1017 ACRfHiSdFldPrsV 1 "Invalid" 0 "Valid" ;
VAL_ 1017 GenStptDtCycPtOvrAct 1 "true" 0 "false" ;
VAL_ 1017 VehTopSpdLmtMdAct 1 "true" 0 "false" ;
VAL_ 1017 GenFldDutCycV 1 "Invalid" 0 "Valid" ;
VAL_ 1017 GenFld 1 "true" 0 "false" ;
VAL_ 1017 FlInjRlCtRstOcc 1 "true" 0 "false" ;
VAL_ 1017 EngSpdLmtnMdAct 1 "true" 0 "false" ;
VAL_ 977 AutoMdSpdLmtStat 0 "No Speed Limit Change" 1 "Proposed Speed Limit Change" 2 "Accepted Speed Limit Change" 3 "Declined Speed Limit Change" ;
VAL_ 977 FuelFltLifRstPerf 1 "true" 0 "false" ;
VAL_ 977 SpdLmtrSpdWrngAct 1 "true" 0 "false" ;
VAL_ 977 CrsCntlDrSelSpdAct 1 "true" 0 "false" ;
VAL_ 977 ACCompCmnd 1 "On" 0 "Off" ;
VAL_ 977 EngBstPrsIndV 1 "Invalid" 0 "Valid" ;
VAL_ 977 ThrPosV 1 "Invalid" 0 "Valid" ;
VAL_ 977 EngOilStrvtnIO 1 "true" 0 "false" ;
VAL_ 977 EngNEmsnsRelMalfAct 1 "true" 0 "false" ;
VAL_ 977 EngEmsRelMalfIndReq 4 "Flashing 0.5 Hertz Indication" 3 "Flashing 2 Hertz Indication" 2 "Flashing 1 Hertz Indication" 1 "No Indication" 0 "Continuous Indication" ;
VAL_ 977 EngCstFlCutAct 1 "true" 0 "false" ;
VAL_ 201 Eng12vStrtrMtrCmmdOn 1 "true" 0 "false" ;
VAL_ 201 EngCntrlRunCrnkTrmSt 1 "Active" 0 "Inactive" ;
VAL_ 201 EngAirIntBstPrV 1 "Invalid" 0 "Valid" ;
VAL_ 201 SpdLmtrSpdWrngEnbld 1 "true" 0 "false" ;
VAL_ 201 EngCylDactEvntPndg 1 "true" 0 "false" ;
VAL_ 201 EngCylDeactMd 3 "Reactivation In Progress" 2 "Half of Total Cylinders Active" 1 "Deactivation In Progress" 0 "All Cylinders Active" ;
VAL_ 201 RmVhStrtEngRng 1 "true" 0 "false" ;
VAL_ 201 PFEngSpdCmndSpcd 1 "true" 0 "false" ;
VAL_ 201 PltfrmEngSpdCmdInhtRq 1 "Inhibit Platform Eng. Speed Control" 0 "Allow Platform Engine Speed Control" ;
VAL_ 201 PT_BrkPedDscrtInpStatV 1 "Invalid" 0 "Valid" ;
VAL_ 201 PT_BrkPedDscrtInpStat 1 "Brake Applied" 0 "Brake Not Applied" ;
VAL_ 201 CrsCntEnbld 1 "true" 0 "false" ;
VAL_ 201 CrsCntAtv 1 "true" 0 "false" ;
VAL_ 201 DrvThrottlOvrrdDet 1 "true" 0 "false" ;
VAL_ 201 PT_CrnkAct 1 "true" 0 "false" ;
VAL_ 201 PTRunAbrt 1 "true" 0 "false" ;
VAL_ 201 PTO_PT_RunAbrtd 1 "true" 0 "false" ;
VAL_ 201 PTCrnkAbrted 1 "true" 0 "false" ;
VAL_ 201 EngSpdStat 3 "Invalid" 1 "Degraded Operation" 0 "Normal Operation" ;
VAL_ 201 EngRunAtv 1 "true" 0 "false" ;
VAL_ 201 EngIdlAtv 1 "true" 0 "false" ;
VAL_ 201 AccActPosV 1 "Invalid" 0 "Valid" ;
VAL_ 501 TmpDrvrShftCtlAct 1 "true" 0 "false" ;
VAL_ 501 EngRecDwnshftIO 1 "true" 0 "false" ;
VAL_ 501 TrnsPattSelEcnMdOCm 1 "true" 0 "false" ;
VAL_ 501 CltStartSwAtvV 1 "Invalid" 0 "Valid" ;
VAL_ 501 CltStartSwAtv 1 "true" 0 "false" ;
VAL_ 501 CltchPdlActPosV 1 "Invalid" 0 "Valid" ;
VAL_ 501 TrnsEngdStateV 1 "Invalid" 0 "Valid" ;
VAL_ 501 TrnsEngdState 3 "Operating State Not Reached" 2 "Transmission Engaged in Reverse" 1 "Transmission Engaged in Forward" 0 "Transmission Not Engaged" ;
VAL_ 501 TrnsShftLvrLckRqd 1 "true" 0 "false" ;
VAL_ 501 TransTUDMdStat 2 "Electronic Range Select Active" 1 "Driver Shift Control Active" 0 "No Activation" ;
VAL_ 501 TrnCrpMdAtv 1 "true" 0 "false" ;
VAL_ 501 TrnsSkpShftIO 1 "true" 0 "false" ;
VAL_ 501 TrnsSftMdStat 3 "Automatic Grade Braking Mode" 2 "Lift-Foot Cornering Mode" 1 "Performance Mode" 0 "No Override Mode" ;
VAL_ 501 TrnsRngInhbtStat 4 "Diagnostic Inhibit Active" 3 "Driveline Not Engaged" 2 "Transmission Range Re-Selection Req" 1 "Transmission Inhibit Active" 0 "No Range Inhibit Active" ;
VAL_ 501 TopTrvlCltchSwActV 1 "Invalid" 0 "Valid" ;
VAL_ 501 TopTrvlCltchSwAct 1 "true" 0 "false" ;
VAL_ 501 EngRecmndUpshftIO 1 "true" 0 "false" ;
VAL_ 501 DrvtShftCntrlTrgtGear 8 "Eighth Gear" 7 "Seventh Gear" 6 "Sixth Gear" 5 "Fifth Gear" 4 "Fourth Gear" 3 "Third Gear" 2 "Second Gear" 1 "First Gear" 0 "Not Supported" ;
VAL_ 501 DrShftCntrlReqDndIO 1 "true" 0 "false" ;
VAL_ 501 TrnShftPtrnActStat 6 "PT Protection Pattern Active" 5 "PT Non-Protection Pattern Active" 4 "Shift Pattern 4 Active" 3 "Shift Pattern 3 Active" 2 "Shift Pattern 2 Active" 1 "Shift Pattern 1 Active" 0 "Default Shift Pattern Active" ;
VAL_ 501 TrnsFldPrsPrsnt 1 "true" 0 "false" ;
VAL_ 501 TrnsShftLvrPos 15 "Lever Position Unknown" 11 "Forward Range H" 10 "Forward Range G" 9 "Forward Range F" 8 "Forward Range E" 7 "Forward Range D" 6 "Forward Range C" 5 "Forward Range B" 4 "Forward Range A" 3 "Neutral Range" 2 "Reverse Range" 1 "Park Range" 0 "Between Ranges" ;
VAL_ 501 TrnsShftLvrPosV 1 "Invalid" 0 "Valid" ;
VAL_ 501 TrnsTrqCnvCltCmndMd 7 "Not Supported" 3 "Locked" 2 "Controlled Slip" 1 "Transitioning" 0 "Unlocked" ;
VAL_ 501 AutoTransComndGear 15 "Park Gear" 14 "Reverse Gear" 13 "Neutral Gear" 12 "CVT Forward Gear" 11 "EVT Mode 2" 10 "EVT Mode 1" 8 "Eighth Gear" 7 "Seventh Gear" 6 "Sixth Gear" 5 "Fifth Gear" 4 "Fourth Gear" 3 "Third Gear" 2 "Second Gear" 1 "First Gear" 0 "Not Supported" ;
VAL_ 501 AutoTransGrSftDirect 2 "Downshift in Progress" 1 "Upshift in Progress" 0 "No Shift in Progress" ;
VAL_ 501 TransEstGear 15 "Park Gear" 14 "Reverse Gear" 13 "Neutral Gear" 12 "CVT Forward Gear" 11 "EVT Mode 2" 10 "EVT Mode 1" 8 "Eighth Gear" 7 "Seventh Gear" 6 "Sixth Gear" 5 "Fifth Gear" 4 "Fourth Gear" 3 "Third Gear" 2 "Second Gear" 1 "First Gear" 0 "Not Supported" ;
VAL_ 501 TransEstGearV 1 "Invalid" 0 "Valid" ;
VAL_ 1225 TCTPIR_DrvNotfn 15 "Indication 15" 14 "Indication 14" 13 "Indication 13" 12 "Indication 12" 11 "Indication 11" 10 "Indication 10" 9 "Indication 9" 8 "Indication 8" 7 "Indication 7" 6 "Indication 6" 5 "Indication 5" 4 "Indication 4" 3 "Indication 3" 2 "Indication 2" 1 "Indication 1" 0 "No Indication" ;
VAL_ 1225 GrdBrkgAct 1 "true" 0 "false" ;
VAL_ 1225 RrPTCoolFanRatFltStat 0 "state0805" 1 "Pass" 2 "Fail" 3 "Reserved and Unused" ;
VAL_ 1225 TrnsThrmlMngmntStat 2 "Driver Intervention Requested" 1 "Countermeasures Active" 0 "Normal" ;
VAL_ 1225 TrnsNEmsRltMalfActv 1 "true" 0 "false" ;
VAL_ 1225 TransOilTempSensPres 1 "true" 0 "false" ;
VAL_ 1225 TrnEmsMlfAtv 1 "true" 0 "false" ;
VAL_ 1225 TrnOilTmpV 1 "Invalid" 0 "Valid" ;
VAL_ 1225 TERDTC_SysDes 15 "U3-Network Codes Reserved" 14 "U2-Network Codes Reserved" 13 "U1-Network Codes MFG Controlled" 12 "U0-Network Codes SAE Controlled" 11 "B3-Body Codes Reserved" 10 "B2-Body Codes Reserved" 9 "B1-Body Codes MFG Controlled" 8 "B0-Body Codes SAE Controlled" 7 "C3-Chassis Codes Reserved" 6 "C2-Chassis Codes Reserved" 5 "C1-Chassis Codes MFG Controlled" 4 "C0-Chassis Codes SAE Controlled" 3 "P3-Powertrain Codes Reserved" 2 "P2-Powertrain Codes Reserved" 1 "P1-Powertrain Codes MFG Controlled" 0 "P0-Powertrain Codes SAE Controlled" ;
VAL_ 249 TrnsRqHSABrkPrDcyRt 0 "Normal" 1 "Level 1" 2 "Level 2" 3 "Level 3" ;
VAL_ 249 TrnsDrvlneTqShpDisRq 1 "true" 0 "false" ;
VAL_ 249 TrnsOtptRotRCRstOcc 1 "true" 0 "false" ;
VAL_ 249 TrnsOtptRotRCV 1 "Invalid" 0 "Valid" ;
VAL_ 249 TrnsOtptShftAngVelSnrPr 1 "true" 0 "false" ;
VAL_ 249 TrnsOutShftAngVelV 1 "Invalid" 0 "Valid" ;
VAL_ 249 TrnsOvrallEstTorqRatioV 1 "Invalid" 0 "Valid" ;
SIG_GROUP_ 452 AutBrkAccActPsSt 1 : ABAAPS_AccPos ABAAPS_AccPosV;
SIG_GROUP_ 452 ACCAxlTrqCmdStat 1 : ACCATCS_LmtgStat ACCATCS_RqStat;
SIG_GROUP_ 452 ColPrSysAxlTrqCmdStat 1 : CPSATCS_ReqStatus CPSATCS_LmtngStatus;
SIG_GROUP_ 452 RrVrtBmpAxlTrqCmdStat 1 : RVBATCS_ReqStat RVBATCS_LmtngStat;
SIG_GROUP_ 190 PTSnsdBrkPdlInf 1 : PSBPI_PTSnBrkPdlPsV PSBPI_PTSnBrkPdlPs;
SIG_GROUP_ 1906 DTCInfo_772 1 : DTCI_DTCFaultType_772 DTCI_CodeSupported_772 DTCI_CurrentStatus_772 DTCI_TstNPsdCdClrdSt_772 DTCI_TstFldCdClrdStat_772 DTCI_HistStat_772 DTCI_TstNPsdPwrUpSt_772 DTCI_TstFldPwrUpSt_772 DTCI_WrnIndRqdSt_772 DTCI_DTCFailType_772 DTCI_DTCNumber_772 DTCI_DTCSource_772 DTCI_DTCTriggered_772 DTCIUnused7_772 DTCIUnused6_772 DTCIUnused5_772 DTCIUnused4_772 DTCIUnused3_772 DTCIUnused2_772 DTCIUnused1_772;
SIG_GROUP_ 707 ChsSysTtlAxleTrqRqSt 1 : CSTATRS_ReqStat CSTATRS_LmtgStat;
SIG_GROUP_ 417 EngTransGearReq 1 : ETGRReqdGear ETGRReqType;
SIG_GROUP_ 985 ECODrvAsstDsplyStat 1 : EDADS_RcmndtFwdGr EDADS_CrntFwdMsdG EDADS_ShftIndStat EDADS_EcoDrvShftIO;
SIG_GROUP_ 1225 TrnsCltchThrmlProtIndR 1 : TCTPIR_TnsEsClCDwT TCTPIR_TnsEsClTmpD TCTPIR_DrvNotfn;
SIG_GROUP_ 1225 TransEmsnsRelDTC 1 : TERDTC_SysDes TERDTC_CdNum;
